VERSION ""

NS_ :

BS_:

BU_: OpticalSensor EMUS_BMS SCIMO_PE TelemetryNode Master SensorF SensorR BrakeF BrakeR PDU HVCU HVTU TestBench

BO_ 1538 SensorR_SDO_Req_Down: 2 TelemetryNode
 SG_ SensorR_SDO_ID M : 0|12@1+ (1,0) [0|4095] ""  SensorR

BO_ 1794 SensorR_Heartbeat: 1 SensorR
 SG_ SensorR_NodeState : 0|8@1+ (1,0) [0|0] ""  SensorF,Master,TelemetryNode

BO_ 1858 SensorR_BTL_TX: 8 SensorR

BO_ 1922 SensorR_BTL_RX: 8 TelemetryNode

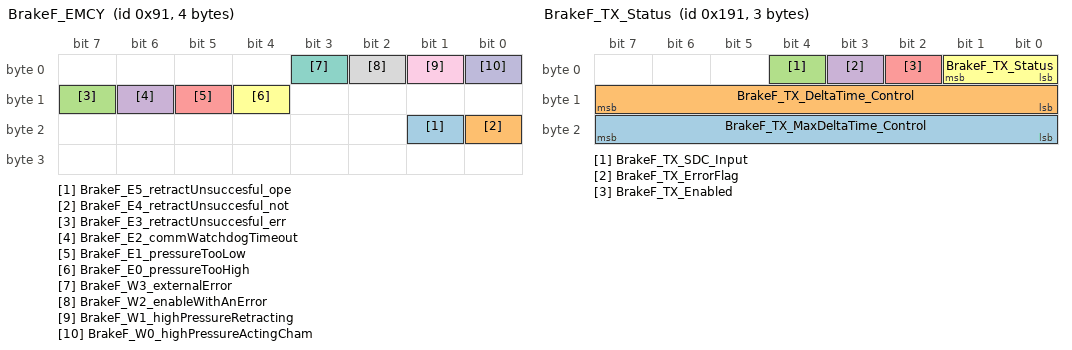
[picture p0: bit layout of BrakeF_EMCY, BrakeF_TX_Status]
BO_ 145 BrakeF_EMCY: 4 BrakeF
 SG_ BrakeF_E5_retractUnsuccesful_ope : 17|1@1+ (1,0) [0|0] ""  Master,TelemetryNode
 SG_ BrakeF_E4_retractUnsuccesful_not : 16|1@1+ (1,0) [0|0] ""  Master,TelemetryNode
 SG_ BrakeF_E3_retractUnsuccesful_err : 15|1@1+ (1,0) [0|0] ""  Master,TelemetryNode
 SG_ BrakeF_E2_commWatchdogTimeout : 14|1@1+ (1,0) [0|0] ""  Master,TelemetryNode
 SG_ BrakeF_E1_pressureTooLow : 13|1@1+ (1,0) [0|0] ""  Master,TelemetryNode
 SG_ BrakeF_E0_pressureTooHigh : 12|1@1+ (1,0) [0|0] ""  Master,TelemetryNode
 SG_ BrakeF_W3_externalError : 3|1@1+ (1,0) [0|0] ""  Master,TelemetryNode
 SG_ BrakeF_W2_enableWithAnError : 2|1@1+ (1,0) [0|0] ""  Master,TelemetryNode
 SG_ BrakeF_W1_highPressureRetracting : 1|1@1+ (1,0) [0|0] ""  Master,TelemetryNode
 SG_ BrakeF_W0_highPressureActingCham : 0|1@1+ (1,0) [0|0] ""  Master,TelemetryNode

BO_ 401 BrakeF_TX_Status: 3 BrakeF
 SG_ BrakeF_TX_MaxDeltaTime_Control : 16|8@1+ (1,0) [0|255] "ms" Vector__XXX
 SG_ BrakeF_TX_DeltaTime_Control : 8|8@1+ (1,0) [0|255] "ms" Vector__XXX
 SG_ BrakeF_TX_SDC_Input : 4|1@1+ (1,0) [0|0] "" Vector__XXX
 SG_ BrakeF_TX_ErrorFlag : 3|1@1+ (1,0) [0|0] ""  SensorF
 SG_ BrakeF_TX_Enabled : 2|1@1+ (1,0) [0|0] ""  SensorF
 SG_ BrakeF_TX_Status : 0|2@1+ (1,0) [0|0] ""  SensorF

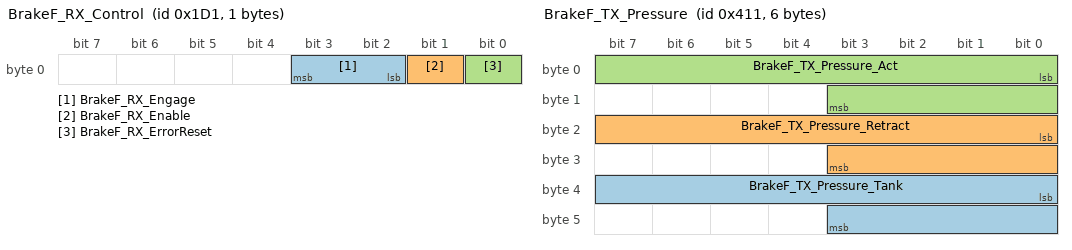
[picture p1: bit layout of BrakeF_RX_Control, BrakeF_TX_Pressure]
BO_ 465 BrakeF_RX_Control: 1 SensorF
 SG_ BrakeF_RX_Engage : 2|2@1+ (1,0) [0|0] "" Vector__XXX
 SG_ BrakeF_RX_Enable : 1|1@1+ (1,0) [0|0] "" Vector__XXX
 SG_ BrakeF_RX_ErrorReset : 0|1@1+ (1,0) [0|0] "" Vector__XXX

BO_ 529 BrakeF_TX_PDO2: 0 BrakeF

BO_ 593 BrakeF_RX_PDO2: 0 Vector__XXX

BO_ 657 BrakeF_TX_PDO3: 0 BrakeF

BO_ 721 BrakeF_RX_PDO3: 0 Vector__XXX

BO_ 785 BrakeF_TX_PDO4: 0 BrakeF

BO_ 849 BrakeF_RX_PDO4: 0 Vector__XXX

BO_ 913 BrakeF_TX_PDO5: 0 BrakeF

BO_ 977 BrakeF_TX_PDO6: 0 BrakeF

BO_ 1041 BrakeF_TX_Pressure: 6 BrakeF
 SG_ BrakeF_TX_Pressure_Tank : 32|12@1+ (0.005,-2) [-2|18.475] "bar" Vector__XXX
 SG_ BrakeF_TX_Pressure_Retract : 16|12@1+ (0.005,-2) [-2|18.475] "bar" Vector__XXX
 SG_ BrakeF_TX_Pressure_Act : 0|12@1+ (0.005,-2) [-2|18.475] "bar" Vector__XXX

BO_ 1105 BrakeF_TX_PDO8: 0 BrakeF

BO_ 1169 BrakeF_TX_PDO9: 0 BrakeF

BO_ 1233 BrakeF_TX_PDO10: 0 BrakeF

BO_ 1297 BrakeF_TX_PDO11: 0 BrakeF

BO_ 1361 BrakeF_TX_PDO12: 0 BrakeF

BO_ 1425 BrakeF_SDO_Resp: 8 BrakeF
 SG_ BrakeF_OD_valveUpperTolerance m2053 : 16|16@1+ (0.005,0) [0|327.675] "bar"  TelemetryNode
 SG_ BrakeF_OD_commWatchdog m2052 : 16|16@1+ (1,0) [0|65535] "ms"  TelemetryNode
 SG_ BrakeF_OD_counterLimit m2051 : 16|8@1+ (1,0) [0|255] ""  TelemetryNode
 SG_ BrakeF_OD_delay m2050 : 16|8@1+ (0.5,0) [0|127.5] "ms"  TelemetryNode
 SG_ BrakeF_OD_tankUpperControlLimit m2049 : 16|16@1+ (0.005,0) [0|327.675] "bar"  TelemetryNode
 SG_ BrakeF_OD_tankLowerControlLimit m2048 : 16|16@1+ (0.005,0) [0|327.675] "bar"  TelemetryNode
 SG_ BrakeF_OD_CAN2_DelayedTxMessages m1129 : 16|24@1+ (1,0) [0|16777215] ""  TelemetryNode
 SG_ BrakeF_OD_CAN2_ErrorStatus m1128 : 16|8@1+ (1,0) [0|255] ""  TelemetryNode
 SG_ BrakeF_OD_CAN2_DiscardedTxMessag m1127 : 16|24@1+ (1,0) [0|16777215] ""  TelemetryNode
 SG_ BrakeF_OD_CAN2_Status m1126 : 16|8@1+ (1,0) [0|255] ""  TelemetryNode
 SG_ BrakeF_OD_CAN2_Baudrate m1124 : 16|16@1+ (1,0) [125|1000] "kbps"  TelemetryNode
 SG_ BrakeF_OD_CAN2_autoErrorReset m1123 : 16|8@1+ (1,0) [0|255] ""  TelemetryNode
 SG_ BrakeF_OD_CAN2_lastErrorCode m1122 : 16|32@1+ (1,0) [0|4294967295] ""  TelemetryNode
 SG_ BrakeF_OD_CAN2_RxErrCnt m1121 : 16|8@1+ (1,0) [0|255] ""  TelemetryNode
 SG_ BrakeF_OD_CAN2_TxErrCnt m1120 : 16|8@1+ (1,0) [0|255] ""  TelemetryNode
 SG_ BrakeF_OD_CAN1_DelayedTxMessages m1113 : 16|24@1+ (1,0) [0|16777215] ""  TelemetryNode
 SG_ BrakeF_OD_CAN1_ErrorStatus m1112 : 16|8@1+ (1,0) [0|255] ""  TelemetryNode
 SG_ BrakeF_OD_CAN1_DiscardedTxMessag m1111 : 16|24@1+ (1,0) [0|16777215] ""  TelemetryNode
 SG_ BrakeF_OD_CAN1_Status m1110 : 16|8@1+ (1,0) [0|255] ""  TelemetryNode
 SG_ BrakeF_OD_CAN1_Baudrate m1108 : 16|16@1+ (1,0) [125|1000] "kbps"  TelemetryNode
 SG_ BrakeF_OD_CAN1_autoErrorReset m1107 : 16|8@1+ (1,0) [0|255] ""  TelemetryNode
 SG_ BrakeF_OD_CAN1_lastErrorCode m1106 : 16|32@1+ (1,0) [0|4294967295] ""  TelemetryNode
 SG_ BrakeF_OD_CAN1_RxErrCnt m1105 : 16|8@1+ (1,0) [0|255] ""  TelemetryNode
 SG_ BrakeF_OD_CAN1_TxErrCnt m1104 : 16|8@1+ (1,0) [0|255] ""  TelemetryNode
 SG_ BrakeF_OD_BuildTime m1073 : 16|24@1+ (1,0) [0|16777215] ""  TelemetryNode
 SG_ BrakeF_OD_BuildDate m1072 : 16|32@1+ (1,0) [0|4294967295] ""  TelemetryNode
 SG_ BrakeF_OD_ChipUID2 m1057 : 16|48@1+ (1,0) [0|281474976710655] ""  TelemetryNode
 SG_ BrakeF_OD_ChipUID1 m1056 : 16|48@1+ (1,0) [0|281474976710655] ""  TelemetryNode
 SG_ BrakeF_OD_SdcOut m1046 : 16|8@1+ (1,0) [0|255] ""  TelemetryNode
 SG_ BrakeF_OD_SdcIn m1045 : 16|8@1+ (1,0) [0|255] ""  TelemetryNode
 SG_ BrakeF_OD_runtime m1044 : 16|24@1+ (1,0) [0|16777215] "ms"  TelemetryNode
 SG_ BrakeF_OD_InputVoltage m1043 : 16|16@1+ (0.001,0) [0|65.535] "V"  TelemetryNode
 SG_ BrakeF_OD_BoardTemp m1042 : 16|16@1+ (0.01,-30) [-30|625.35] "°C"  TelemetryNode
 SG_ BrakeF_OD_MemFree m1041 : 16|16@1+ (4,0) [0|262140] "bytes"  TelemetryNode
 SG_ BrakeF_OD_CpuUsage m1040 : 16|8@1+ (0.5,0) [0|100] "%"  TelemetryNode
 SG_ BrakeF_OD_OdEntrySendInterval m33 : 16|16@1+ (1,0) [0|65535] "ms"  TelemetryNode
 SG_ BrakeF_OD_SendOdOnBootup m32 : 16|8@1+ (1,0) [0|255] ""  TelemetryNode
 SG_ BrakeF_OD_HeartbeatInterval m16 : 16|16@1+ (1,0) [0|65535] "ms"  TelemetryNode
 SG_ BrakeF_OD_DbcVersion m5 : 16|16@1+ (1,0) [0|65535] ""  TelemetryNode
 SG_ BrakeF_OD_StackVersion m4 : 16|16@1+ (1,0) [0|65535] ""  TelemetryNode
 SG_ BrakeF_OD_ProtocolVersion m3 : 16|16@1+ (1,0) [0|65535] ""  TelemetryNode
 SG_ BrakeF_OD_NodeStatus m2 : 16|8@1+ (1,0) [0|255] ""  TelemetryNode
 SG_ BrakeF_OD_NodeID m1 : 16|8@1+ (1,0) [0|255] ""  TelemetryNode
 SG_ BrakeF_SDO_RespCode : 12|4@1+ (1,0) [0|0] ""  TelemetryNode
 SG_ BrakeF_SDO_ID M : 0|12@1+ (1,0) [0|4095] ""  TelemetryNode

BO_ 1489 BrakeF_SDO_Req_Up: 8 TelemetryNode
 SG_ BrakeF_OD_valveUpperTolerance m2053 : 16|16@1+ (0.005,0) [0|327.675] "bar"  BrakeF
 SG_ BrakeF_OD_commWatchdog m2052 : 16|16@1+ (1,0) [0|65535] "ms"  BrakeF
 SG_ BrakeF_OD_counterLimit m2051 : 16|8@1+ (1,0) [0|255] ""  BrakeF
 SG_ BrakeF_OD_delay m2050 : 16|8@1+ (0.5,0) [0|127.5] "ms"  BrakeF
 SG_ BrakeF_OD_tankUpperControlLimit m2049 : 16|16@1+ (0.005,0) [0|327.675] "bar"  BrakeF
 SG_ BrakeF_OD_tankLowerControlLimit m2048 : 16|16@1+ (0.005,0) [0|327.675] "bar"  BrakeF
 SG_ BrakeF_OD_CAN2_DelayedTxMessages m1129 : 16|24@1+ (1,0) [0|16777215] ""  BrakeF
 SG_ BrakeF_OD_CAN2_ErrorStatus m1128 : 16|8@1+ (1,0) [0|255] ""  BrakeF
 SG_ BrakeF_OD_CAN2_DiscardedTxM_0000 m1127 : 16|24@1+ (1,0) [0|16777215] ""  BrakeF
 SG_ BrakeF_OD_CAN2_Status m1126 : 16|8@1+ (1,0) [0|255] ""  BrakeF
 SG_ BrakeF_OD_CAN2_Baudrate m1124 : 16|16@1+ (1,0) [125|1000] "kbps"  BrakeF
 SG_ BrakeF_OD_CAN2_autoErrorReset m1123 : 16|8@1+ (1,0) [0|255] ""  BrakeF
 SG_ BrakeF_OD_CAN2_lastErrorCode m1122 : 16|32@1+ (1,0) [0|4294967295] ""  BrakeF
 SG_ BrakeF_OD_CAN2_RxErrCnt m1121 : 16|8@1+ (1,0) [0|255] ""  BrakeF
 SG_ BrakeF_OD_CAN2_TxErrCnt m1120 : 16|8@1+ (1,0) [0|255] ""  BrakeF
 SG_ BrakeF_OD_CAN1_DelayedTxMessages m1113 : 16|24@1+ (1,0) [0|16777215] ""  BrakeF
 SG_ BrakeF_OD_CAN1_ErrorStatus m1112 : 16|8@1+ (1,0) [0|255] ""  BrakeF
 SG_ BrakeF_OD_CAN1_DiscardedTxM_0000 m1111 : 16|24@1+ (1,0) [0|16777215] ""  BrakeF
 SG_ BrakeF_OD_CAN1_Status m1110 : 16|8@1+ (1,0) [0|255] ""  BrakeF
 SG_ BrakeF_OD_CAN1_Baudrate m1108 : 16|16@1+ (1,0) [125|1000] "kbps"  BrakeF
 SG_ BrakeF_OD_CAN1_autoErrorReset m1107 : 16|8@1+ (1,0) [0|255] ""  BrakeF
 SG_ BrakeF_OD_CAN1_lastErrorCode m1106 : 16|32@1+ (1,0) [0|4294967295] ""  BrakeF
 SG_ BrakeF_OD_CAN1_RxErrCnt m1105 : 16|8@1+ (1,0) [0|255] ""  BrakeF
 SG_ BrakeF_OD_CAN1_TxErrCnt m1104 : 16|8@1+ (1,0) [0|255] ""  BrakeF
 SG_ BrakeF_OD_BuildTime m1073 : 16|24@1+ (1,0) [0|16777215] ""  BrakeF
 SG_ BrakeF_OD_BuildDate m1072 : 16|32@1+ (1,0) [0|4294967295] ""  BrakeF
 SG_ BrakeF_OD_ChipUID2 m1057 : 16|48@1+ (1,0) [0|281474976710655] ""  BrakeF
 SG_ BrakeF_OD_ChipUID1 m1056 : 16|48@1+ (1,0) [0|281474976710655] ""  BrakeF
 SG_ BrakeF_OD_SdcOut m1046 : 16|8@1+ (1,0) [0|255] ""  BrakeF
 SG_ BrakeF_OD_SdcIn m1045 : 16|8@1+ (1,0) [0|255] ""  BrakeF
 SG_ BrakeF_OD_runtime m1044 : 16|24@1+ (1,0) [0|16777215] "ms"  BrakeF
 SG_ BrakeF_OD_InputVoltage m1043 : 16|16@1+ (0.001,0) [0|65.535] "V"  BrakeF
 SG_ BrakeF_OD_BoardTemp m1042 : 16|16@1+ (0.01,-30) [-30|625.35] "°C"  BrakeF
 SG_ BrakeF_OD_MemFree m1041 : 16|16@1+ (4,0) [0|262140] "bytes"  BrakeF
 SG_ BrakeF_OD_CpuUsage m1040 : 16|8@1+ (0.5,0) [0|100] "%"  BrakeF
 SG_ BrakeF_OD_OdEntrySendInterval m33 : 16|16@1+ (1,0) [0|65535] "ms"  BrakeF
 SG_ BrakeF_OD_SendOdOnBootup m32 : 16|8@1+ (1,0) [0|255] ""  BrakeF
 SG_ BrakeF_OD_HeartbeatInterval m16 : 16|16@1+ (1,0) [0|65535] "ms"  BrakeF
 SG_ BrakeF_OD_DbcVersion m5 : 16|16@1+ (1,0) [0|65535] ""  BrakeF
 SG_ BrakeF_OD_StackVersion m4 : 16|16@1+ (1,0) [0|65535] ""  BrakeF
 SG_ BrakeF_OD_ProtocolVersion m3 : 16|16@1+ (1,0) [0|65535] ""  BrakeF
 SG_ BrakeF_OD_NodeStatus m2 : 16|8@1+ (1,0) [0|255] ""  BrakeF
 SG_ BrakeF_OD_NodeID m1 : 16|8@1+ (1,0) [0|255] ""  BrakeF
 SG_ BrakeF_SDO_ID M : 0|12@1+ (1,0) [0|4095] ""  BrakeF

BO_ 1553 BrakeF_SDO_Req_Down: 2 TelemetryNode
 SG_ BrakeF_SDO_ID M : 0|12@1+ (1,0) [0|4095] ""  BrakeF

BO_ 1809 BrakeF_Heartbeat: 1 BrakeF
 SG_ BrakeF_NodeState : 0|8@1+ (1,0) [0|0] ""  SensorF,Master,TelemetryNode

BO_ 1873 BrakeF_BTL_TX: 8 BrakeF

BO_ 1937 BrakeF_BTL_RX: 8 TelemetryNode

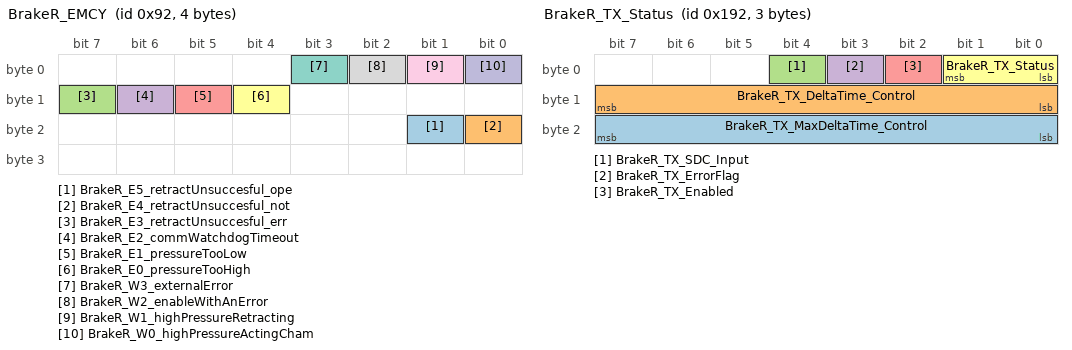
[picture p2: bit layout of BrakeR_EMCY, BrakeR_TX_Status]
BO_ 146 BrakeR_EMCY: 4 BrakeR
 SG_ BrakeR_E5_retractUnsuccesful_ope : 17|1@1+ (1,0) [0|0] ""  Master,TelemetryNode
 SG_ BrakeR_E4_retractUnsuccesful_not : 16|1@1+ (1,0) [0|0] ""  Master,TelemetryNode
 SG_ BrakeR_E3_retractUnsuccesful_err : 15|1@1+ (1,0) [0|0] ""  Master,TelemetryNode
 SG_ BrakeR_E2_commWatchdogTimeout : 14|1@1+ (1,0) [0|0] ""  Master,TelemetryNode
 SG_ BrakeR_E1_pressureTooLow : 13|1@1+ (1,0) [0|0] ""  Master,TelemetryNode
 SG_ BrakeR_E0_pressureTooHigh : 12|1@1+ (1,0) [0|0] ""  Master,TelemetryNode
 SG_ BrakeR_W3_externalError : 3|1@1+ (1,0) [0|0] ""  Master,TelemetryNode
 SG_ BrakeR_W2_enableWithAnError : 2|1@1+ (1,0) [0|0] ""  Master,TelemetryNode
 SG_ BrakeR_W1_highPressureRetracting : 1|1@1+ (1,0) [0|0] ""  Master,TelemetryNode
 SG_ BrakeR_W0_highPressureActingCham : 0|1@1+ (1,0) [0|0] ""  Master,TelemetryNode

BO_ 402 BrakeR_TX_Status: 3 BrakeR
 SG_ BrakeR_TX_MaxDeltaTime_Control : 16|8@1+ (1,0) [0|255] "ms" Vector__XXX
 SG_ BrakeR_TX_DeltaTime_Control : 8|8@1+ (1,0) [0|255] "ms" Vector__XXX
 SG_ BrakeR_TX_SDC_Input : 4|1@1+ (1,0) [0|0] "" Vector__XXX
 SG_ BrakeR_TX_ErrorFlag : 3|1@1+ (1,0) [0|0] ""  SensorF
 SG_ BrakeR_TX_Enabled : 2|1@1+ (1,0) [0|0] ""  SensorF
 SG_ BrakeR_TX_Status : 0|2@1+ (1,0) [0|0] ""  SensorF

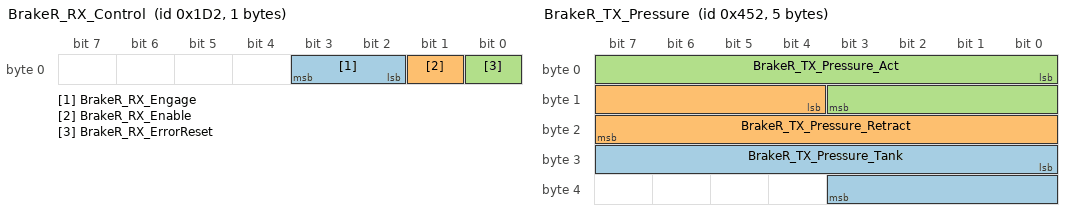
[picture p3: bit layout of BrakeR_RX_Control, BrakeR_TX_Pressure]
BO_ 466 BrakeR_RX_Control: 1 SensorF
 SG_ BrakeR_RX_Engage : 2|2@1+ (1,0) [0|0] "" Vector__XXX
 SG_ BrakeR_RX_Enable : 1|1@1+ (1,0) [0|0] "" Vector__XXX
 SG_ BrakeR_RX_ErrorReset : 0|1@1+ (1,0) [0|0] "" Vector__XXX

BO_ 530 BrakeR_TX_PDO2: 0 BrakeR

BO_ 594 BrakeR_RX_PDO2: 0 Vector__XXX

BO_ 658 BrakeR_TX_PDO3: 0 BrakeR

BO_ 722 BrakeR_RX_PDO3: 0 Vector__XXX

BO_ 786 BrakeR_TX_PDO4: 0 BrakeR

BO_ 850 BrakeR_RX_PDO4: 0 Vector__XXX

BO_ 914 BrakeR_TX_PDO5: 0 BrakeR

BO_ 978 BrakeR_TX_PDO6: 0 BrakeR

BO_ 1042 BrakeR_TX_PDO7: 0 BrakeR

BO_ 1106 BrakeR_TX_Pressure: 5 BrakeR
 SG_ BrakeR_TX_Pressure_Tank : 24|12@1+ (0.005,-2) [-2|18.475] "bar" Vector__XXX
 SG_ BrakeR_TX_Pressure_Retract : 12|12@1+ (0.005,-2) [-2|18.475] "bar" Vector__XXX
 SG_ BrakeR_TX_Pressure_Act : 0|12@1+ (0.005,-2) [-2|18.475] "bar" Vector__XXX

BO_ 1170 BrakeR_TX_PDO9: 0 BrakeR

BO_ 1234 BrakeR_TX_PDO10: 0 BrakeR

BO_ 1298 BrakeR_TX_PDO11: 0 BrakeR

BO_ 1362 BrakeR_TX_PDO12: 0 BrakeR

BO_ 1426 BrakeR_SDO_Resp: 8 BrakeR
 SG_ BrakeR_OD_valveUpperTolerance m2053 : 16|16@1+ (0.005,0) [0|327.675] "bar"  TelemetryNode
 SG_ BrakeR_OD_commWatchdog m2052 : 16|16@1+ (1,0) [0|65535] "ms"  TelemetryNode
 SG_ BrakeR_OD_counterLimit m2051 : 16|8@1+ (1,0) [0|255] ""  TelemetryNode
 SG_ BrakeR_OD_delay m2050 : 16|8@1+ (0.5,0) [0|127.5] "ms"  TelemetryNode
 SG_ BrakeR_OD_tankUpperControlLimit m2049 : 16|16@1+ (0.005,0) [0|327.675] "bar"  TelemetryNode
 SG_ BrakeR_OD_tankLowerControlLimit m2048 : 16|16@1+ (0.005,0) [0|327.675] "bar"  TelemetryNode
 SG_ BrakeR_OD_CAN2_DelayedTxMessages m1129 : 16|24@1+ (1,0) [0|16777215] ""  TelemetryNode
 SG_ BrakeR_OD_CAN2_ErrorStatus m1128 : 16|8@1+ (1,0) [0|255] ""  TelemetryNode
 SG_ BrakeR_OD_CAN2_DiscardedTxMessag m1127 : 16|24@1+ (1,0) [0|16777215] ""  TelemetryNode
 SG_ BrakeR_OD_CAN2_Status m1126 : 16|8@1+ (1,0) [0|255] ""  TelemetryNode
 SG_ BrakeR_OD_CAN2_Baudrate m1124 : 16|16@1+ (1,0) [125|1000] "kbps"  TelemetryNode
 SG_ BrakeR_OD_CAN2_autoErrorReset m1123 : 16|8@1+ (1,0) [0|255] ""  TelemetryNode
 SG_ BrakeR_OD_CAN2_lastErrorCode m1122 : 16|32@1+ (1,0) [0|4294967295] ""  TelemetryNode
 SG_ BrakeR_OD_CAN2_RxErrCnt m1121 : 16|8@1+ (1,0) [0|255] ""  TelemetryNode
 SG_ BrakeR_OD_CAN2_TxErrCnt m1120 : 16|8@1+ (1,0) [0|255] ""  TelemetryNode
 SG_ BrakeR_OD_CAN1_DelayedTxMessages m1113 : 16|24@1+ (1,0) [0|16777215] ""  TelemetryNode
 SG_ BrakeR_OD_CAN1_ErrorStatus m1112 : 16|8@1+ (1,0) [0|255] ""  TelemetryNode
 SG_ BrakeR_OD_CAN1_DiscardedTxMessag m1111 : 16|24@1+ (1,0) [0|16777215] ""  TelemetryNode
 SG_ BrakeR_OD_CAN1_Status m1110 : 16|8@1+ (1,0) [0|255] ""  TelemetryNode
 SG_ BrakeR_OD_CAN1_Baudrate m1108 : 16|16@1+ (1,0) [125|1000] "kbps"  TelemetryNode
 SG_ BrakeR_OD_CAN1_autoErrorReset m1107 : 16|8@1+ (1,0) [0|255] ""  TelemetryNode
 SG_ BrakeR_OD_CAN1_lastErrorCode m1106 : 16|32@1+ (1,0) [0|4294967295] ""  TelemetryNode
 SG_ BrakeR_OD_CAN1_RxErrCnt m1105 : 16|8@1+ (1,0) [0|255] ""  TelemetryNode
 SG_ BrakeR_OD_CAN1_TxErrCnt m1104 : 16|8@1+ (1,0) [0|255] ""  TelemetryNode
 SG_ BrakeR_OD_BuildTime m1073 : 16|24@1+ (1,0) [0|16777215] ""  TelemetryNode
 SG_ BrakeR_OD_BuildDate m1072 : 16|32@1+ (1,0) [0|4294967295] ""  TelemetryNode
 SG_ BrakeR_OD_ChipUID2 m1057 : 16|48@1+ (1,0) [0|281474976710655] ""  TelemetryNode
 SG_ BrakeR_OD_ChipUID1 m1056 : 16|48@1+ (1,0) [0|281474976710655] ""  TelemetryNode
 SG_ BrakeR_OD_SdcOut m1046 : 16|8@1+ (1,0) [0|255] ""  TelemetryNode
 SG_ BrakeR_OD_SdcIn m1045 : 16|8@1+ (1,0) [0|255] ""  TelemetryNode
 SG_ BrakeR_OD_runtime m1044 : 16|24@1+ (1,0) [0|16777215] "ms"  TelemetryNode
 SG_ BrakeR_OD_InputVoltage m1043 : 16|16@1+ (0.001,0) [0|65.535] "V"  TelemetryNode
 SG_ BrakeR_OD_BoardTemp m1042 : 16|16@1+ (0.01,-30) [-30|625.35] "°C"  TelemetryNode
 SG_ BrakeR_OD_MemFree m1041 : 16|16@1+ (4,0) [0|262140] "bytes"  TelemetryNode
 SG_ BrakeR_OD_CpuUsage m1040 : 16|8@1+ (0.5,0) [0|100] "%"  TelemetryNode
 SG_ BrakeR_OD_OdEntrySendInterval m33 : 16|16@1+ (1,0) [0|65535] "ms"  TelemetryNode
 SG_ BrakeR_OD_SendOdOnBootup m32 : 16|8@1+ (1,0) [0|255] ""  TelemetryNode
 SG_ BrakeR_OD_HeartbeatInterval m16 : 16|16@1+ (1,0) [0|65535] "ms"  TelemetryNode
 SG_ BrakeR_OD_DbcVersion m5 : 16|16@1+ (1,0) [0|65535] ""  TelemetryNode
 SG_ BrakeR_OD_StackVersion m4 : 16|16@1+ (1,0) [0|65535] ""  TelemetryNode
 SG_ BrakeR_OD_ProtocolVersion m3 : 16|16@1+ (1,0) [0|65535] ""  TelemetryNode
 SG_ BrakeR_OD_NodeStatus m2 : 16|8@1+ (1,0) [0|255] ""  TelemetryNode
 SG_ BrakeR_OD_NodeID m1 : 16|8@1+ (1,0) [0|255] ""  TelemetryNode
 SG_ BrakeR_SDO_RespCode : 12|4@1+ (1,0) [0|0] ""  TelemetryNode
 SG_ BrakeR_SDO_ID M : 0|12@1+ (1,0) [0|4095] ""  TelemetryNode

BO_ 1490 BrakeR_SDO_Req_Up: 8 TelemetryNode
 SG_ BrakeR_OD_valveUpperTolerance m2053 : 16|16@1+ (0.005,0) [0|327.675] "bar"  BrakeR
 SG_ BrakeR_OD_commWatchdog m2052 : 16|16@1+ (1,0) [0|65535] "ms"  BrakeR
 SG_ BrakeR_OD_counterLimit m2051 : 16|8@1+ (1,0) [0|255] ""  BrakeR
 SG_ BrakeR_OD_delay m2050 : 16|8@1+ (0.5,0) [0|127.5] "ms"  BrakeR
 SG_ BrakeR_OD_tankUpperControlLimit m2049 : 16|16@1+ (0.005,0) [0|327.675] "bar"  BrakeR
 SG_ BrakeR_OD_tankLowerControlLimit m2048 : 16|16@1+ (0.005,0) [0|327.675] "bar"  BrakeR
 SG_ BrakeR_OD_CAN2_DelayedTxMessages m1129 : 16|24@1+ (1,0) [0|16777215] ""  BrakeR
 SG_ BrakeR_OD_CAN2_ErrorStatus m1128 : 16|8@1+ (1,0) [0|255] ""  BrakeR
 SG_ BrakeR_OD_CAN2_DiscardedTxM_0000 m1127 : 16|24@1+ (1,0) [0|16777215] ""  BrakeR
 SG_ BrakeR_OD_CAN2_Status m1126 : 16|8@1+ (1,0) [0|255] ""  BrakeR
 SG_ BrakeR_OD_CAN2_Baudrate m1124 : 16|16@1+ (1,0) [125|1000] "kbps"  BrakeR
 SG_ BrakeR_OD_CAN2_autoErrorReset m1123 : 16|8@1+ (1,0) [0|255] ""  BrakeR
 SG_ BrakeR_OD_CAN2_lastErrorCode m1122 : 16|32@1+ (1,0) [0|4294967295] ""  BrakeR
 SG_ BrakeR_OD_CAN2_RxErrCnt m1121 : 16|8@1+ (1,0) [0|255] ""  BrakeR
 SG_ BrakeR_OD_CAN2_TxErrCnt m1120 : 16|8@1+ (1,0) [0|255] ""  BrakeR
 SG_ BrakeR_OD_CAN1_DelayedTxMessages m1113 : 16|24@1+ (1,0) [0|16777215] ""  BrakeR
 SG_ BrakeR_OD_CAN1_ErrorStatus m1112 : 16|8@1+ (1,0) [0|255] ""  BrakeR
 SG_ BrakeR_OD_CAN1_DiscardedTxM_0000 m1111 : 16|24@1+ (1,0) [0|16777215] ""  BrakeR
 SG_ BrakeR_OD_CAN1_Status m1110 : 16|8@1+ (1,0) [0|255] ""  BrakeR
 SG_ BrakeR_OD_CAN1_Baudrate m1108 : 16|16@1+ (1,0) [125|1000] "kbps"  BrakeR
 SG_ BrakeR_OD_CAN1_autoErrorReset m1107 : 16|8@1+ (1,0) [0|255] ""  BrakeR
 SG_ BrakeR_OD_CAN1_lastErrorCode m1106 : 16|32@1+ (1,0) [0|4294967295] ""  BrakeR
 SG_ BrakeR_OD_CAN1_RxErrCnt m1105 : 16|8@1+ (1,0) [0|255] ""  BrakeR
 SG_ BrakeR_OD_CAN1_TxErrCnt m1104 : 16|8@1+ (1,0) [0|255] ""  BrakeR
 SG_ BrakeR_OD_BuildTime m1073 : 16|24@1+ (1,0) [0|16777215] ""  BrakeR
 SG_ BrakeR_OD_BuildDate m1072 : 16|32@1+ (1,0) [0|4294967295] ""  BrakeR
 SG_ BrakeR_OD_ChipUID2 m1057 : 16|48@1+ (1,0) [0|281474976710655] ""  BrakeR
 SG_ BrakeR_OD_ChipUID1 m1056 : 16|48@1+ (1,0) [0|281474976710655] ""  BrakeR
 SG_ BrakeR_OD_SdcOut m1046 : 16|8@1+ (1,0) [0|255] ""  BrakeR
 SG_ BrakeR_OD_SdcIn m1045 : 16|8@1+ (1,0) [0|255] ""  BrakeR
 SG_ BrakeR_OD_runtime m1044 : 16|24@1+ (1,0) [0|16777215] "ms"  BrakeR
 SG_ BrakeR_OD_InputVoltage m1043 : 16|16@1+ (0.001,0) [0|65.535] "V"  BrakeR
 SG_ BrakeR_OD_BoardTemp m1042 : 16|16@1+ (0.01,-30) [-30|625.35] "°C"  BrakeR
 SG_ BrakeR_OD_MemFree m1041 : 16|16@1+ (4,0) [0|262140] "bytes"  BrakeR
 SG_ BrakeR_OD_CpuUsage m1040 : 16|8@1+ (0.5,0) [0|100] "%"  BrakeR
 SG_ BrakeR_OD_OdEntrySendInterval m33 : 16|16@1+ (1,0) [0|65535] "ms"  BrakeR
 SG_ BrakeR_OD_SendOdOnBootup m32 : 16|8@1+ (1,0) [0|255] ""  BrakeR
 SG_ BrakeR_OD_HeartbeatInterval m16 : 16|16@1+ (1,0) [0|65535] "ms"  BrakeR
 SG_ BrakeR_OD_DbcVersion m5 : 16|16@1+ (1,0) [0|65535] ""  BrakeR
 SG_ BrakeR_OD_StackVersion m4 : 16|16@1+ (1,0) [0|65535] ""  BrakeR
 SG_ BrakeR_OD_ProtocolVersion m3 : 16|16@1+ (1,0) [0|65535] ""  BrakeR
 SG_ BrakeR_OD_NodeStatus m2 : 16|8@1+ (1,0) [0|255] ""  BrakeR
 SG_ BrakeR_OD_NodeID m1 : 16|8@1+ (1,0) [0|255] ""  BrakeR
 SG_ BrakeR_SDO_ID M : 0|12@1+ (1,0) [0|4095] ""  BrakeR

BO_ 1554 BrakeR_SDO_Req_Down: 2 TelemetryNode
 SG_ BrakeR_SDO_ID M : 0|12@1+ (1,0) [0|4095] ""  BrakeR

BO_ 1810 BrakeR_Heartbeat: 1 BrakeR
 SG_ BrakeR_NodeState : 0|8@1+ (1,0) [0|0] ""  SensorF,Master,TelemetryNode

BO_ 1874 BrakeR_BTL_TX: 8 BrakeR

BO_ 1938 BrakeR_BTL_RX: 8 TelemetryNode

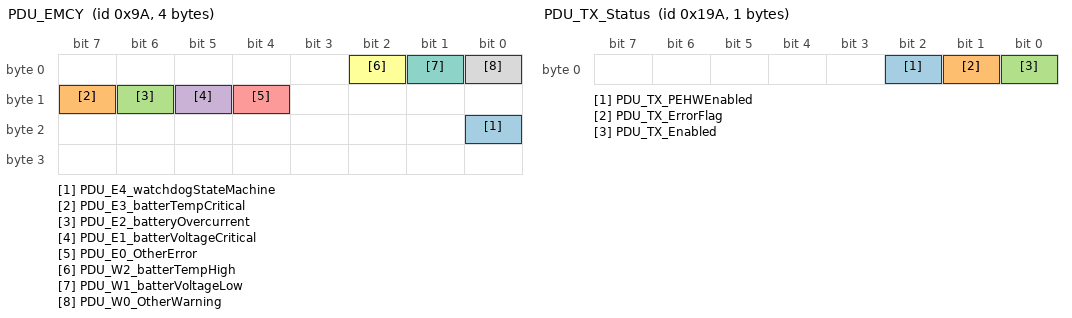
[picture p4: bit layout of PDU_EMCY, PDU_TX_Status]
BO_ 154 PDU_EMCY: 4 PDU
 SG_ PDU_E4_watchdogStateMachine : 16|1@1+ (1,0) [0|0] ""  Master,TelemetryNode
 SG_ PDU_E3_batterTempCritical : 15|1@1+ (1,0) [0|0] ""  Master,TelemetryNode
 SG_ PDU_E2_batteryOvercurrent : 14|1@1+ (1,0) [0|0] ""  Master,TelemetryNode
 SG_ PDU_E1_batterVoltageCritical : 13|1@1+ (1,0) [0|0] ""  Master,TelemetryNode
 SG_ PDU_E0_OtherError : 12|1@1+ (1,0) [0|0] ""  Master,TelemetryNode
 SG_ PDU_W2_batterTempHigh : 2|1@1+ (1,0) [0|0] ""  Master,TelemetryNode
 SG_ PDU_W1_batterVoltageLow : 1|1@1+ (1,0) [0|0] ""  Master,TelemetryNode
 SG_ PDU_W0_OtherWarning : 0|1@1+ (1,0) [0|0] ""  Master,TelemetryNode

BO_ 410 PDU_TX_Status: 1 PDU
 SG_ PDU_TX_PEHWEnabled : 2|1@1+ (1,0) [0|0] ""  SensorF
 SG_ PDU_TX_ErrorFlag : 1|1@1+ (1,0) [0|0] ""  SensorF
 SG_ PDU_TX_Enabled : 0|1@1+ (1,0) [0|0] ""  SensorF

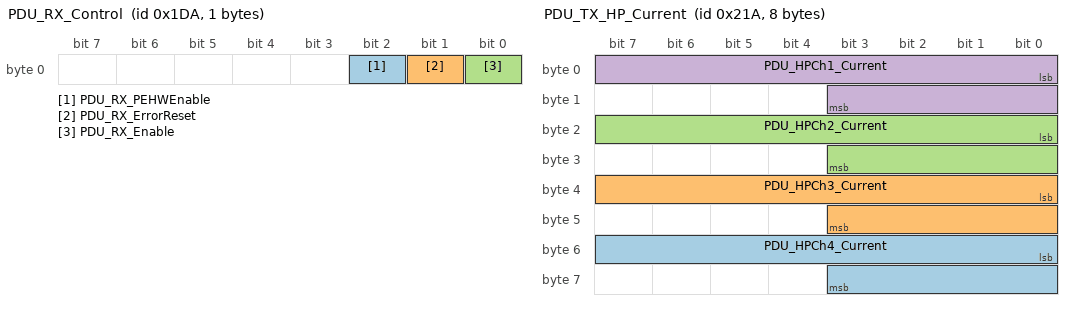
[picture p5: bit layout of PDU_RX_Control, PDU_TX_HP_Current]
BO_ 474 PDU_RX_Control: 1 SensorF
 SG_ PDU_RX_PEHWEnable : 2|1@1+ (1,0) [0|0] "" Vector__XXX
 SG_ PDU_RX_ErrorReset : 1|1@1+ (1,0) [0|0] "" Vector__XXX
 SG_ PDU_RX_Enable : 0|1@1+ (1,0) [0|0] "" Vector__XXX

BO_ 538 PDU_TX_HP_Current: 8 PDU
 SG_ PDU_HPCh4_Current : 48|12@1+ (0.004,0) [0|16.38] "A" Vector__XXX
 SG_ PDU_HPCh3_Current : 32|12@1+ (0.004,0) [0|16.38] "A" Vector__XXX
 SG_ PDU_HPCh2_Current : 16|12@1+ (0.004,0) [0|16.38] "A" Vector__XXX
 SG_ PDU_HPCh1_Current : 0|12@1+ (0.004,0) [0|16.38] "A" Vector__XXX

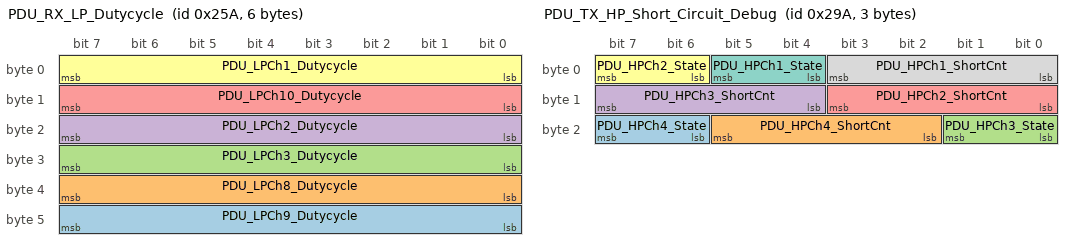
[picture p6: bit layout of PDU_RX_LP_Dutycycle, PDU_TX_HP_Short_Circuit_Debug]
BO_ 602 PDU_RX_LP_Dutycycle: 6 Vector__XXX
 SG_ PDU_LPCh9_Dutycycle : 40|8@1+ (0.5,0) [0|100] "%" Vector__XXX
 SG_ PDU_LPCh8_Dutycycle : 32|8@1+ (0.5,0) [0|100] "%" Vector__XXX
 SG_ PDU_LPCh3_Dutycycle : 24|8@1+ (0.5,0) [0|100] "%" Vector__XXX
 SG_ PDU_LPCh2_Dutycycle : 16|8@1+ (0.5,0) [0|100] "%" Vector__XXX
 SG_ PDU_LPCh10_Dutycycle : 8|8@1+ (0.5,0) [0|100] "%" Vector__XXX
 SG_ PDU_LPCh1_Dutycycle : 0|8@1+ (0.5,0) [0|100] "%" Vector__XXX

BO_ 666 PDU_TX_HP_Short_Circuit_Debug: 3 PDU
 SG_ PDU_HPCh4_State : 22|2@1+ (1,0) [0|3] "" Vector__XXX
 SG_ PDU_HPCh4_ShortCnt : 18|4@1+ (1,0) [0|15] "" Vector__XXX
 SG_ PDU_HPCh3_State : 16|2@1+ (1,0) [0|3] "" Vector__XXX
 SG_ PDU_HPCh3_ShortCnt : 12|4@1+ (1,0) [0|15] "" Vector__XXX
 SG_ PDU_HPCh2_ShortCnt : 8|4@1+ (1,0) [0|15] "" Vector__XXX
 SG_ PDU_HPCh2_State : 6|2@1+ (1,0) [0|3] "" Vector__XXX
 SG_ PDU_HPCh1_State : 4|2@1+ (1,0) [0|3] "" Vector__XXX
 SG_ PDU_HPCh1_ShortCnt : 0|4@1+ (1,0) [0|15] "" Vector__XXX

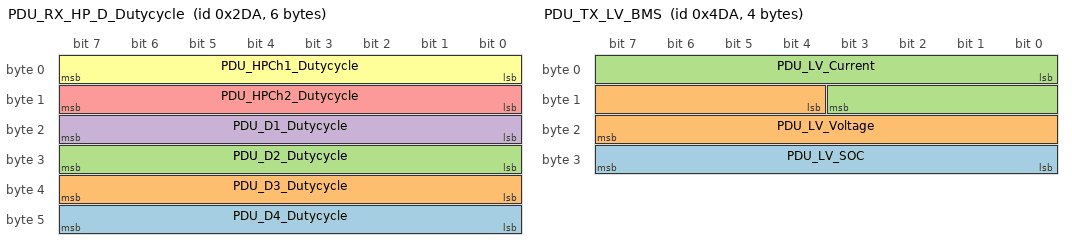
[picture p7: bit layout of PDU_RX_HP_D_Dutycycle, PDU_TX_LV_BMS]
BO_ 730 PDU_RX_HP_D_Dutycycle: 6 Vector__XXX
 SG_ PDU_D4_Dutycycle : 40|8@1+ (0.5,0) [0|100] "%" Vector__XXX
 SG_ PDU_D3_Dutycycle : 32|8@1+ (0.5,0) [0|100] "%" Vector__XXX
 SG_ PDU_D2_Dutycycle : 24|8@1+ (0.5,0) [0|100] "%" Vector__XXX
 SG_ PDU_D1_Dutycycle : 16|8@1+ (0.5,0) [0|100] "%" Vector__XXX
 SG_ PDU_HPCh2_Dutycycle : 8|8@1+ (0.5,0) [0|100] "%" Vector__XXX
 SG_ PDU_HPCh1_Dutycycle : 0|8@1+ (0.5,0) [0|100] "%" Vector__XXX

BO_ 794 PDU_TX_PDO4: 0 PDU

BO_ 858 PDU_RX_Manual_Control: 3 Vector__XXX
 SG_ PDU_SDC_Enable : 18|1@1+ (1,0) [0|0] "" Vector__XXX
 SG_ PDU_D4_Enable : 17|1@1+ (1,0) [0|1] "" Vector__XXX
 SG_ PDU_D3_Enable : 16|1@1+ (1,0) [0|1] "" Vector__XXX
 SG_ PDU_D2_Enable : 15|1@1+ (1,0) [0|1] "" Vector__XXX
 SG_ PDU_D1_Enable : 14|1@1+ (1,0) [0|1] "" Vector__XXX
 SG_ PDU_HPCh4_Enable : 13|1@1+ (1,0) [0|1] "" Vector__XXX
 SG_ PDU_HPCh3_Enable : 12|1@1+ (1,0) [0|1] "" Vector__XXX
 SG_ PDU_HPCh2_Enable : 11|1@1+ (1,0) [0|1] "" Vector__XXX
 SG_ PDU_HPCh1_Enable : 10|1@1+ (1,0) [0|1] "" Vector__XXX
 SG_ PDU_LPCh10_Enable : 9|1@1+ (1,0) [0|1] "" Vector__XXX
 SG_ PDU_LPCh9_Enable : 8|1@1+ (1,0) [0|1] "" Vector__XXX
 SG_ PDU_LPCh8_Enable : 7|1@1+ (1,0) [0|1] "" Vector__XXX
 SG_ PDU_LPCh7_Enable : 6|1@1+ (1,0) [0|1] "" Vector__XXX
 SG_ PDU_LPCh6_Enable : 5|1@1+ (1,0) [0|1] "" Vector__XXX
 SG_ PDU_LPCh5_Enable : 4|1@1+ (1,0) [0|1] "" Vector__XXX
 SG_ PDU_LPCh4_Enable : 3|1@1+ (1,0) [0|1] "" Vector__XXX
 SG_ PDU_LPCh3_Enable : 2|1@1+ (1,0) [0|1] "" Vector__XXX
 SG_ PDU_LPCh2_Enable : 1|1@1+ (1,0) [0|1] "" Vector__XXX
 SG_ PDU_LPCh1_Enable : 0|1@1+ (1,0) [0|1] "" Vector__XXX

BO_ 922 PDU_TX_PDO5: 0 PDU

BO_ 986 PDU_TX_PDO6: 0 PDU

BO_ 1050 PDU_TX_PDO7: 0 PDU

BO_ 1114 PDU_TX_PDO8: 0 PDU

BO_ 1178 PDU_TX_LP_Short_Circuit_Debug: 8 PDU
 SG_ PDU_LPCh9_State : 58|2@1+ (1,0) [0|3] "" Vector__XXX
 SG_ PDU_LPCh8_State : 56|2@1+ (1,0) [0|3] "" Vector__XXX
 SG_ PDU_LPCh7_State : 54|2@1+ (1,0) [0|3] "" Vector__XXX
 SG_ PDU_LPCh6_State : 52|2@1+ (1,0) [0|3] "" Vector__XXX
 SG_ PDU_LPCh5_State : 50|2@1+ (1,0) [0|3] "" Vector__XXX
 SG_ PDU_LPCh4_State : 48|2@1+ (1,0) [0|3] "" Vector__XXX
 SG_ PDU_LPCh3_State : 46|2@1+ (1,0) [0|3] "" Vector__XXX
 SG_ PDU_LPCh2_State : 44|2@1+ (1,0) [0|3] "" Vector__XXX
 SG_ PDU_LPCh1_State : 42|2@1+ (1,0) [0|3] "" Vector__XXX
 SG_ PDU_LPCh10_State : 40|2@1+ (1,0) [0|3] "" Vector__XXX
 SG_ PDU_LPCh9_ShortCnt : 36|4@1+ (1,0) [0|15] "" Vector__XXX
 SG_ PDU_LPCh8_ShortCnt : 32|4@1+ (1,0) [0|15] "" Vector__XXX
 SG_ PDU_LPCh7_ShortCnt : 28|4@1+ (1,0) [0|15] "" Vector__XXX
 SG_ PDU_LPCh6_ShortCnt : 24|4@1+ (1,0) [0|15] "" Vector__XXX
 SG_ PDU_LPCh5_ShortCnt : 20|4@1+ (1,0) [0|15] "" Vector__XXX
 SG_ PDU_LPCh4_ShortCnt : 16|4@1+ (1,0) [0|15] "" Vector__XXX
 SG_ PDU_LPCh3_ShortCnt : 12|4@1+ (1,0) [0|15] "" Vector__XXX
 SG_ PDU_LPCh2_ShortCnt : 8|4@1+ (1,0) [0|15] "" Vector__XXX
 SG_ PDU_LPCh1_ShortCnt : 4|4@1+ (1,0) [0|15] "" Vector__XXX
 SG_ PDU_LPCh10_ShortCnt : 0|4@1+ (1,0) [0|15] "" Vector__XXX

BO_ 1242 PDU_TX_LV_BMS: 4 PDU
 SG_ PDU_LV_SOC : 24|8@1- (1,0) [0|100] "%" Vector__XXX
 SG_ PDU_LV_Voltage : 12|12@1+ (0.01,0) [0|40.95] "V" Vector__XXX
 SG_ PDU_LV_Current : 0|12@1+ (0.01,0) [0|40.95] "A" Vector__XXX

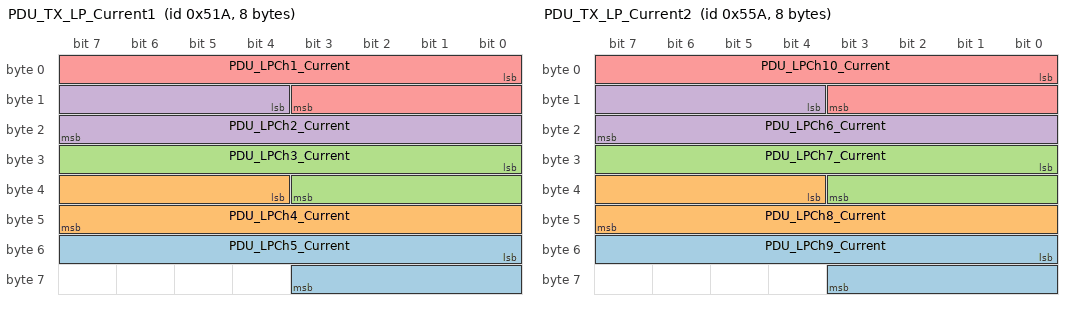
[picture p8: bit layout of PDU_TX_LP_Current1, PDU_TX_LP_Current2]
BO_ 1306 PDU_TX_LP_Current1: 8 PDU
 SG_ PDU_LPCh5_Current : 48|12@1+ (0.002,0) [0|8.19] "A" Vector__XXX
 SG_ PDU_LPCh4_Current : 36|12@1+ (0.002,0) [0|8.19] "A" Vector__XXX
 SG_ PDU_LPCh3_Current : 24|12@1+ (0.002,0) [0|8.19] "A" Vector__XXX
 SG_ PDU_LPCh2_Current : 12|12@1+ (0.002,0) [0|8.19] "A" Vector__XXX
 SG_ PDU_LPCh1_Current : 0|12@1+ (0.002,0) [0|8.19] "A" Vector__XXX

BO_ 1370 PDU_TX_LP_Current2: 8 PDU
 SG_ PDU_LPCh9_Current : 48|12@1+ (0.002,0) [0|8.19] "A" Vector__XXX
 SG_ PDU_LPCh8_Current : 36|12@1+ (0.002,0) [0|8.19] "A" Vector__XXX
 SG_ PDU_LPCh7_Current : 24|12@1+ (0.002,0) [0|8.19] "A" Vector__XXX
 SG_ PDU_LPCh6_Current : 12|12@1+ (0.002,0) [0|8.19] "A" Vector__XXX
 SG_ PDU_LPCh10_Current : 0|12@1+ (0.002,0) [0|8.19] "A" Vector__XXX

BO_ 1434 PDU_SDO_Resp: 8 PDU
 SG_ PDU_OD_CoolingPumpEnabled m2816 : 16|8@1+ (1,0) [0|255] ""  TelemetryNode
 SG_ PDU_OD_LedCommands m2562 : 16|16@1+ (1,0) [0|65535] ""  TelemetryNode
 SG_ PDU_OD_projectXXEnabled m2560 : 16|8@1+ (1,0) [0|255] ""  TelemetryNode
 SG_ PDU_OD_watchdogTimeout m2306 : 16|16@1+ (1,0) [0|65535] "ms"  TelemetryNode
 SG_ PDU_OD_statusSendInterval m2305 : 16|16@1+ (1,0) [0|65535] "ms"  TelemetryNode
 SG_ PDU_OD_currentReadInterval m2304 : 16|16@1+ (1,0) [0|65535] "ms"  TelemetryNode
 SG_ PDU_OD_batteryOvercurrent m2128 : 16|16@1+ (0.01,0) [0|655.35] "A"  TelemetryNode
 SG_ PDU_OD_overTempCritical m2051 : 16|16@1+ (0.1,0) [0|6553.5] "degrees"  TelemetryNode
 SG_ PDU_OD_overTempWarn m2050 : 16|16@1+ (0.1,0) [0|6553.5] "degrees"  TelemetryNode
 SG_ PDU_OD_batterVoltageCritical m2049 : 16|16@1+ (0.01,0) [0|655.35] "V"  TelemetryNode
 SG_ PDU_OD_batterVoltageLow m2048 : 16|16@1+ (0.01,0) [0|655.35] "V"  TelemetryNode
 SG_ PDU_OD_CAN2_DelayedTxMessages m1129 : 16|24@1+ (1,0) [0|16777215] ""  TelemetryNode
 SG_ PDU_OD_CAN2_ErrorStatus m1128 : 16|8@1+ (1,0) [0|255] ""  TelemetryNode
 SG_ PDU_OD_CAN2_DiscardedTxMessages m1127 : 16|24@1+ (1,0) [0|16777215] ""  TelemetryNode
 SG_ PDU_OD_CAN2_Status m1126 : 16|8@1+ (1,0) [0|255] ""  TelemetryNode
 SG_ PDU_OD_CAN2_Baudrate m1124 : 16|16@1+ (1,0) [125|1000] "kbps"  TelemetryNode
 SG_ PDU_OD_CAN2_autoErrorReset m1123 : 16|8@1+ (1,0) [0|255] ""  TelemetryNode
 SG_ PDU_OD_CAN2_lastErrorCode m1122 : 16|32@1+ (1,0) [0|4294967295] ""  TelemetryNode
 SG_ PDU_OD_CAN2_RxErrCnt m1121 : 16|8@1+ (1,0) [0|255] ""  TelemetryNode
 SG_ PDU_OD_CAN2_TxErrCnt m1120 : 16|8@1+ (1,0) [0|255] ""  TelemetryNode
 SG_ PDU_OD_CAN1_DelayedTxMessages m1113 : 16|24@1+ (1,0) [0|16777215] ""  TelemetryNode
 SG_ PDU_OD_CAN1_ErrorStatus m1112 : 16|8@1+ (1,0) [0|255] ""  TelemetryNode
 SG_ PDU_OD_CAN1_DiscardedTxMessages m1111 : 16|24@1+ (1,0) [0|16777215] ""  TelemetryNode
 SG_ PDU_OD_CAN1_Status m1110 : 16|8@1+ (1,0) [0|255] ""  TelemetryNode
 SG_ PDU_OD_CAN1_Baudrate m1108 : 16|16@1+ (1,0) [125|1000] "kbps"  TelemetryNode
 SG_ PDU_OD_CAN1_autoErrorReset m1107 : 16|8@1+ (1,0) [0|255] ""  TelemetryNode
 SG_ PDU_OD_CAN1_lastErrorCode m1106 : 16|32@1+ (1,0) [0|4294967295] ""  TelemetryNode
 SG_ PDU_OD_CAN1_RxErrCnt m1105 : 16|8@1+ (1,0) [0|255] ""  TelemetryNode
 SG_ PDU_OD_CAN1_TxErrCnt m1104 : 16|8@1+ (1,0) [0|255] ""  TelemetryNode
 SG_ PDU_OD_BuildTime m1073 : 16|24@1+ (1,0) [0|16777215] ""  TelemetryNode
 SG_ PDU_OD_BuildDate m1072 : 16|32@1+ (1,0) [0|4294967295] ""  TelemetryNode
 SG_ PDU_OD_ChipUID2 m1057 : 16|48@1+ (1,0) [0|281474976710655] ""  TelemetryNode
 SG_ PDU_OD_ChipUID1 m1056 : 16|48@1+ (1,0) [0|281474976710655] ""  TelemetryNode
 SG_ PDU_OD_SdcOut m1046 : 16|8@1+ (1,0) [0|255] ""  TelemetryNode
 SG_ PDU_OD_SdcIn m1045 : 16|8@1+ (1,0) [0|255] ""  TelemetryNode
 SG_ PDU_OD_runtime m1044 : 16|24@1+ (1,0) [0|16777215] "ms"  TelemetryNode
 SG_ PDU_OD_InputVoltage m1043 : 16|16@1+ (0.001,0) [0|65.535] "V"  TelemetryNode
 SG_ PDU_OD_BoardTemp m1042 : 16|16@1+ (0.01,-30) [-30|625.35] "°C"  TelemetryNode
 SG_ PDU_OD_MemFree m1041 : 16|16@1+ (4,0) [0|262140] "bytes"  TelemetryNode
 SG_ PDU_OD_CpuUsage m1040 : 16|8@1+ (0.5,0) [0|100] "%"  TelemetryNode
 SG_ PDU_OD_OdEntrySendInterval m33 : 16|16@1+ (1,0) [0|65535] "ms"  TelemetryNode
 SG_ PDU_OD_SendOdOnBootup m32 : 16|8@1+ (1,0) [0|255] ""  TelemetryNode
 SG_ PDU_OD_HeartbeatInterval m16 : 16|16@1+ (1,0) [0|65535] "ms"  TelemetryNode
 SG_ PDU_OD_DbcVersion m5 : 16|16@1+ (1,0) [0|65535] ""  TelemetryNode
 SG_ PDU_OD_StackVersion m4 : 16|16@1+ (1,0) [0|65535] ""  TelemetryNode
 SG_ PDU_OD_ProtocolVersion m3 : 16|16@1+ (1,0) [0|65535] ""  TelemetryNode
 SG_ PDU_OD_NodeStatus m2 : 16|8@1+ (1,0) [0|255] ""  TelemetryNode
 SG_ PDU_OD_NodeID m1 : 16|8@1+ (1,0) [0|255] ""  TelemetryNode
 SG_ PDU_SDO_RespCode : 12|4@1+ (1,0) [0|0] ""  TelemetryNode
 SG_ PDU_SDO_ID M : 0|12@1+ (1,0) [0|4095] ""  TelemetryNode

BO_ 1498 PDU_SDO_Req_Up: 8 TelemetryNode
 SG_ PDU_OD_CoolingPumpEnabled m2816 : 16|8@1+ (1,0) [0|255] ""  PDU
 SG_ PDU_OD_LedCommands m2562 : 16|16@1+ (1,0) [0|65535] ""  PDU
 SG_ PDU_OD_projectXXEnabled m2560 : 16|8@1+ (1,0) [0|255] ""  PDU
 SG_ PDU_OD_watchdogTimeout m2306 : 16|16@1+ (1,0) [0|65535] "ms"  PDU
 SG_ PDU_OD_statusSendInterval m2305 : 16|16@1+ (1,0) [0|65535] "ms"  PDU
 SG_ PDU_OD_currentReadInterval m2304 : 16|16@1+ (1,0) [0|65535] "ms"  PDU
 SG_ PDU_OD_batteryOvercurrent m2128 : 16|16@1+ (0.01,0) [0|655.35] "A"  PDU
 SG_ PDU_OD_overTempCritical m2051 : 16|16@1+ (0.1,0) [0|6553.5] "degrees"  PDU
 SG_ PDU_OD_overTempWarn m2050 : 16|16@1+ (0.1,0) [0|6553.5] "degrees"  PDU
 SG_ PDU_OD_batterVoltageCritical m2049 : 16|16@1+ (0.01,0) [0|655.35] "V"  PDU
 SG_ PDU_OD_batterVoltageLow m2048 : 16|16@1+ (0.01,0) [0|655.35] "V"  PDU
 SG_ PDU_OD_CAN2_DelayedTxMessages m1129 : 16|24@1+ (1,0) [0|16777215] ""  PDU
 SG_ PDU_OD_CAN2_ErrorStatus m1128 : 16|8@1+ (1,0) [0|255] ""  PDU
 SG_ PDU_OD_CAN2_DiscardedTxMessages m1127 : 16|24@1+ (1,0) [0|16777215] ""  PDU
 SG_ PDU_OD_CAN2_Status m1126 : 16|8@1+ (1,0) [0|255] ""  PDU
 SG_ PDU_OD_CAN2_Baudrate m1124 : 16|16@1+ (1,0) [125|1000] "kbps"  PDU
 SG_ PDU_OD_CAN2_autoErrorReset m1123 : 16|8@1+ (1,0) [0|255] ""  PDU
 SG_ PDU_OD_CAN2_lastErrorCode m1122 : 16|32@1+ (1,0) [0|4294967295] ""  PDU
 SG_ PDU_OD_CAN2_RxErrCnt m1121 : 16|8@1+ (1,0) [0|255] ""  PDU
 SG_ PDU_OD_CAN2_TxErrCnt m1120 : 16|8@1+ (1,0) [0|255] ""  PDU
 SG_ PDU_OD_CAN1_DelayedTxMessages m1113 : 16|24@1+ (1,0) [0|16777215] ""  PDU
 SG_ PDU_OD_CAN1_ErrorStatus m1112 : 16|8@1+ (1,0) [0|255] ""  PDU
 SG_ PDU_OD_CAN1_DiscardedTxMessages m1111 : 16|24@1+ (1,0) [0|16777215] ""  PDU
 SG_ PDU_OD_CAN1_Status m1110 : 16|8@1+ (1,0) [0|255] ""  PDU
 SG_ PDU_OD_CAN1_Baudrate m1108 : 16|16@1+ (1,0) [125|1000] "kbps"  PDU
 SG_ PDU_OD_CAN1_autoErrorReset m1107 : 16|8@1+ (1,0) [0|255] ""  PDU
 SG_ PDU_OD_CAN1_lastErrorCode m1106 : 16|32@1+ (1,0) [0|4294967295] ""  PDU
 SG_ PDU_OD_CAN1_RxErrCnt m1105 : 16|8@1+ (1,0) [0|255] ""  PDU
 SG_ PDU_OD_CAN1_TxErrCnt m1104 : 16|8@1+ (1,0) [0|255] ""  PDU
 SG_ PDU_OD_BuildTime m1073 : 16|24@1+ (1,0) [0|16777215] ""  PDU
 SG_ PDU_OD_BuildDate m1072 : 16|32@1+ (1,0) [0|4294967295] ""  PDU
 SG_ PDU_OD_ChipUID2 m1057 : 16|48@1+ (1,0) [0|281474976710655] ""  PDU
 SG_ PDU_OD_ChipUID1 m1056 : 16|48@1+ (1,0) [0|281474976710655] ""  PDU
 SG_ PDU_OD_SdcOut m1046 : 16|8@1+ (1,0) [0|255] ""  PDU
 SG_ PDU_OD_SdcIn m1045 : 16|8@1+ (1,0) [0|255] ""  PDU
 SG_ PDU_OD_runtime m1044 : 16|24@1+ (1,0) [0|16777215] "ms"  PDU
 SG_ PDU_OD_InputVoltage m1043 : 16|16@1+ (0.001,0) [0|65.535] "V"  PDU
 SG_ PDU_OD_BoardTemp m1042 : 16|16@1+ (0.01,-30) [-30|625.35] "°C"  PDU
 SG_ PDU_OD_MemFree m1041 : 16|16@1+ (4,0) [0|262140] "bytes"  PDU
 SG_ PDU_OD_CpuUsage m1040 : 16|8@1+ (0.5,0) [0|100] "%"  PDU
 SG_ PDU_OD_OdEntrySendInterval m33 : 16|16@1+ (1,0) [0|65535] "ms"  PDU
 SG_ PDU_OD_SendOdOnBootup m32 : 16|8@1+ (1,0) [0|255] ""  PDU
 SG_ PDU_OD_HeartbeatInterval m16 : 16|16@1+ (1,0) [0|65535] "ms"  PDU
 SG_ PDU_OD_DbcVersion m5 : 16|16@1+ (1,0) [0|65535] ""  PDU
 SG_ PDU_OD_StackVersion m4 : 16|16@1+ (1,0) [0|65535] ""  PDU
 SG_ PDU_OD_ProtocolVersion m3 : 16|16@1+ (1,0) [0|65535] ""  PDU
 SG_ PDU_OD_NodeStatus m2 : 16|8@1+ (1,0) [0|255] ""  PDU
 SG_ PDU_OD_NodeID m1 : 16|8@1+ (1,0) [0|255] ""  PDU
 SG_ PDU_SDO_ID M : 0|12@1+ (1,0) [0|4095] ""  PDU

BO_ 1562 PDU_SDO_Req_Down: 2 TelemetryNode
 SG_ PDU_SDO_ID M : 0|12@1+ (1,0) [0|4095] ""  PDU

BO_ 1818 PDU_Heartbeat: 1 PDU
 SG_ PDU_NodeState : 0|8@1+ (1,0) [0|0] ""  SensorF,Master,TelemetryNode

BO_ 1882 PDU_BTL_TX: 8 PDU

BO_ 1946 PDU_BTL_RX: 8 TelemetryNode

BO_ 138 HVCU_EMCY: 4 HVCU
 SG_ HVCU_E19_ChargingModeError : 31|1@1+ (1,0) [0|0] ""  Master,TelemetryNode
 SG_ HVCU_E18_SDCSwitchError : 30|1@1+ (1,0) [0|0] ""  Master,TelemetryNode
 SG_ HVCU_E17_ControlMessageTimeout : 29|1@1+ (1,0) [0|0] ""  Master,TelemetryNode
 SG_ HVCU_E16_NoEnable : 28|1@1+ (1,0) [0|0] ""  Master,TelemetryNode
 SG_ HVCU_E15_SDCOpen : 27|1@1+ (1,0) [0|0] ""  Master,TelemetryNode
 SG_ HVCU_E14_HVMPError : 26|1@1+ (1,0) [0|0] ""  Master,TelemetryNode
 SG_ HVCU_E13_BIR4Error : 25|1@1+ (1,0) [0|0] ""  Master,TelemetryNode
 SG_ HVCU_E12_BIR3Error : 24|1@1+ (1,0) [0|0] ""  Master,TelemetryNode
 SG_ HVCU_E11_BIR2Error : 23|1@1+ (1,0) [0|0] ""  Master,TelemetryNode
 SG_ HVCU_E10_BIR1Error : 22|1@1+ (1,0) [0|0] ""  Master,TelemetryNode
 SG_ HVCU_E9_HVSLError : 21|1@1+ (1,0) [0|0] ""  Master,TelemetryNode
 SG_ HVCU_E8_VoltageMeasuring : 20|1@1+ (1,0) [0|0] ""  Master,TelemetryNode
 SG_ HVCU_E7_BALError : 19|1@1+ (1,0) [0|0] ""  Master,TelemetryNode
 SG_ HVCU_E6_DischargeError : 18|1@1+ (1,0) [0|0] ""  Master,TelemetryNode
 SG_ HVCU_E5_DischargeTimeout : 17|1@1+ (1,0) [0|0] ""  Master,TelemetryNode
 SG_ HVCU_E4_BMSPermissionMissing : 16|1@1+ (1,0) [0|0] ""  Master,TelemetryNode
 SG_ HVCU_E3_PrechargeError : 15|1@1+ (1,0) [0|0] ""  Master,TelemetryNode
 SG_ HVCU_E2_BMSError : 14|1@1+ (1,0) [0|0] ""  Master,TelemetryNode
 SG_ HVCU_E1_IMDError : 13|1@1+ (1,0) [0|0] ""  Master,TelemetryNode
 SG_ HVCU_E0_OtherError : 12|1@1+ (1,0) [0|0] ""  Master,TelemetryNode
 SG_ HVCU_W8_ChargingMode : 8|1@1+ (1,0) [0|0] ""  Master,TelemetryNode
 SG_ HVCU_W7_IsolationResistanceLow : 7|1@1+ (1,0) [0|0] ""  Master,TelemetryNode
 SG_ HVCU_W6_Bir4On : 6|1@1+ (1,0) [0|0] ""  Master,TelemetryNode
 SG_ HVCU_W5_Bir3On : 5|1@1+ (1,0) [0|0] ""  Master,TelemetryNode
 SG_ HVCU_W4_Bir2On : 4|1@1+ (1,0) [0|0] ""  Master,TelemetryNode
 SG_ HVCU_W3_Bir1On : 3|1@1+ (1,0) [0|0] ""  Master,TelemetryNode
 SG_ HVCU_W2_PreChargeOn : 2|1@1+ (1,0) [0|0] ""  Master,TelemetryNode
 SG_ HVCU_W1_HighVoltage : 1|1@1+ (1,0) [0|0] ""  Master,TelemetryNode
 SG_ HVCU_W0_OtherWarning : 0|1@1+ (1,0) [0|0] ""  Master,TelemetryNode

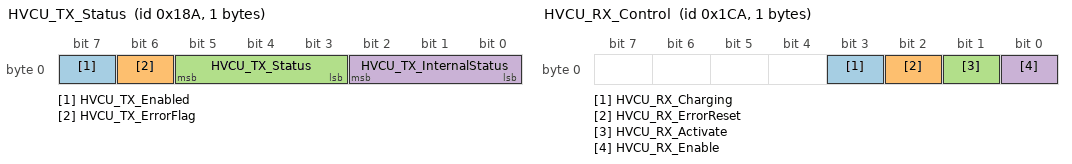
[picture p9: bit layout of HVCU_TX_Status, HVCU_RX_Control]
BO_ 394 HVCU_TX_Status: 1 HVCU
 SG_ HVCU_TX_Enabled : 7|1@1+ (1,0) [0|0] ""  SensorF
 SG_ HVCU_TX_ErrorFlag : 6|1@1+ (1,0) [0|0] ""  SensorF
 SG_ HVCU_TX_Status : 3|3@1+ (1,0) [0|0] ""  SensorF
 SG_ HVCU_TX_InternalStatus : 0|3@1+ (1,0) [0|0] ""  SensorF

BO_ 458 HVCU_RX_Control: 1 SensorF
 SG_ HVCU_RX_Charging : 3|1@1+ (1,0) [0|0] "" Vector__XXX
 SG_ HVCU_RX_ErrorReset : 2|1@1+ (1,0) [0|0] "" Vector__XXX
 SG_ HVCU_RX_Activate : 1|1@1+ (1,0) [0|0] "" Vector__XXX
 SG_ HVCU_RX_Enable : 0|1@1+ (1,0) [0|0] "" Vector__XXX

BO_ 522 HVCU_TX_PDO2: 0 HVCU

BO_ 586 HVCU_RX_PDO2: 0 Vector__XXX

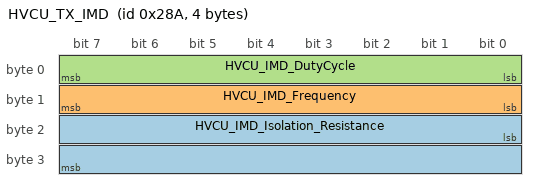
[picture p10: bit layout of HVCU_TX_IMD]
BO_ 650 HVCU_TX_IMD: 4 HVCU
 SG_ HVCU_IMD_Isolation_Resistance : 16|16@1+ (1,0) [0|65535] "kOhm" Vector__XXX
 SG_ HVCU_IMD_Frequency : 8|8@1+ (1,0) [0|60] "Hz" Vector__XXX
 SG_ HVCU_IMD_DutyCycle : 0|8@1+ (1,0) [0|100] "%" Vector__XXX

BO_ 714 HVCU_RX_PDO3: 0 Vector__XXX

BO_ 778 HVCU_TX_PDO4: 0 HVCU

BO_ 842 HVCU_RX_PDO4: 0 Vector__XXX

BO_ 906 HVCU_TX_PDO5: 0 HVCU

BO_ 970 HVCU_TX_PDO6: 0 HVCU

BO_ 1034 HVCU_TX_PDO7: 0 HVCU

BO_ 1098 HVCU_TX_PDO8: 0 HVCU

BO_ 1162 HVCU_TX_PDO9: 0 HVCU

BO_ 1226 HVCU_TX_PDO10: 0 HVCU

BO_ 1290 HVCU_TX_PDO11: 0 HVCU

BO_ 1354 HVCU_TX_PDO12: 0 HVCU

BO_ 1418 HVCU_SDO_Resp: 8 HVCU
 SG_ HVCU_OD_CAN2_DelayedTxMessages m1129 : 16|24@1+ (1,0) [0|16777215] ""  TelemetryNode
 SG_ HVCU_OD_CAN2_ErrorStatus m1128 : 16|8@1+ (1,0) [0|255] ""  TelemetryNode
 SG_ HVCU_OD_CAN2_DiscardedTxMessages m1127 : 16|24@1+ (1,0) [0|16777215] ""  TelemetryNode
 SG_ HVCU_OD_CAN2_Status m1126 : 16|8@1+ (1,0) [0|255] ""  TelemetryNode
 SG_ HVCU_OD_CAN2_Baudrate m1124 : 16|16@1+ (1,0) [125|1000] "kbps"  TelemetryNode
 SG_ HVCU_OD_CAN2_autoErrorReset m1123 : 16|8@1+ (1,0) [0|255] ""  TelemetryNode
 SG_ HVCU_OD_CAN2_lastErrorCode m1122 : 16|32@1+ (1,0) [0|4294967295] ""  TelemetryNode
 SG_ HVCU_OD_CAN2_RxErrCnt m1121 : 16|8@1+ (1,0) [0|255] ""  TelemetryNode
 SG_ HVCU_OD_CAN2_TxErrCnt m1120 : 16|8@1+ (1,0) [0|255] ""  TelemetryNode
 SG_ HVCU_OD_CAN1_DelayedTxMessages m1113 : 16|24@1+ (1,0) [0|16777215] ""  TelemetryNode
 SG_ HVCU_OD_CAN1_ErrorStatus m1112 : 16|8@1+ (1,0) [0|255] ""  TelemetryNode
 SG_ HVCU_OD_CAN1_DiscardedTxMessages m1111 : 16|24@1+ (1,0) [0|16777215] ""  TelemetryNode
 SG_ HVCU_OD_CAN1_Status m1110 : 16|8@1+ (1,0) [0|255] ""  TelemetryNode
 SG_ HVCU_OD_CAN1_Baudrate m1108 : 16|16@1+ (1,0) [125|1000] "kbps"  TelemetryNode
 SG_ HVCU_OD_CAN1_autoErrorReset m1107 : 16|8@1+ (1,0) [0|255] ""  TelemetryNode
 SG_ HVCU_OD_CAN1_lastErrorCode m1106 : 16|32@1+ (1,0) [0|4294967295] ""  TelemetryNode
 SG_ HVCU_OD_CAN1_RxErrCnt m1105 : 16|8@1+ (1,0) [0|255] ""  TelemetryNode
 SG_ HVCU_OD_CAN1_TxErrCnt m1104 : 16|8@1+ (1,0) [0|255] ""  TelemetryNode
 SG_ HVCU_OD_BuildTime m1073 : 16|24@1+ (1,0) [0|16777215] ""  TelemetryNode
 SG_ HVCU_OD_BuildDate m1072 : 16|32@1+ (1,0) [0|4294967295] ""  TelemetryNode
 SG_ HVCU_OD_ChipUID2 m1057 : 16|48@1+ (1,0) [0|281474976710655] ""  TelemetryNode
 SG_ HVCU_OD_ChipUID1 m1056 : 16|48@1+ (1,0) [0|281474976710655] ""  TelemetryNode
 SG_ HVCU_OD_SdcOut m1046 : 16|8@1+ (1,0) [0|255] ""  TelemetryNode
 SG_ HVCU_OD_SdcIn m1045 : 16|8@1+ (1,0) [0|255] ""  TelemetryNode
 SG_ HVCU_OD_runtime m1044 : 16|24@1+ (1,0) [0|16777215] "ms"  TelemetryNode
 SG_ HVCU_OD_InputVoltage m1043 : 16|16@1+ (0.001,0) [0|65.535] "V"  TelemetryNode
 SG_ HVCU_OD_BoardTemp m1042 : 16|16@1+ (0.01,-30) [-30|625.35] "°C"  TelemetryNode
 SG_ HVCU_OD_MemFree m1041 : 16|16@1+ (4,0) [0|262140] "bytes"  TelemetryNode
 SG_ HVCU_OD_CpuUsage m1040 : 16|8@1+ (0.5,0) [0|100] "%"  TelemetryNode
 SG_ HVCU_OD_OdEntrySendInterval m33 : 16|16@1+ (1,0) [0|65535] "ms"  TelemetryNode
 SG_ HVCU_OD_SendOdOnBootup m32 : 16|8@1+ (1,0) [0|255] ""  TelemetryNode
 SG_ HVCU_OD_HeartbeatInterval m16 : 16|16@1+ (1,0) [0|65535] "ms"  TelemetryNode
 SG_ HVCU_OD_DbcVersion m5 : 16|16@1+ (1,0) [0|65535] ""  TelemetryNode
 SG_ HVCU_OD_StackVersion m4 : 16|16@1+ (1,0) [0|65535] ""  TelemetryNode
 SG_ HVCU_OD_ProtocolVersion m3 : 16|16@1+ (1,0) [0|65535] ""  TelemetryNode
 SG_ HVCU_OD_NodeStatus m2 : 16|8@1+ (1,0) [0|255] ""  TelemetryNode
 SG_ HVCU_OD_NodeID m1 : 16|8@1+ (1,0) [0|255] ""  TelemetryNode
 SG_ HVCU_SDO_RespCode : 12|4@1+ (1,0) [0|0] ""  TelemetryNode
 SG_ HVCU_SDO_ID M : 0|12@1+ (1,0) [0|4095] ""  TelemetryNode

CM_ BO_ 1538 "DO NOT CHANGE ANYTHING HERE!
SDO Request Download from node SensorR with Node-ID 0x2";
CM_ SG_ 1538 SensorR_SDO_ID "Specifies SDO-ID of SensorR";
CM_ BO_ 1794 "Heartbeat of node SensorR with Node-ID 0x2";
CM_ SG_ 1794 SensorR_NodeState "Heartbeat status of node SensorR";
CM_ BO_ 1858 "Bootloader transmit from node SensorR with Node-ID 0x2";
CM_ BO_ 1922 "Bootloader receive by node SensorR with Node-ID 0x2";
CM_ BO_ 145 "Emergency message of node BrakeF with Node-ID 0x11";
CM_ SG_ 145 BrakeF_E5_retractUnsuccesful_ope "Instruction to retract was received, but the SDC is detected to be open";
CM_ SG_ 145 BrakeF_E4_retractUnsuccesful_not "Instruction to retract was received, but the ECU is not enabled";
CM_ SG_ 145 BrakeF_E3_retractUnsuccesful_err "Instruction to retract was received, but an error flag inhibited retraction";
CM_ SG_ 145 BrakeF_E2_commWatchdogTimeout "Communication Watchdog timeout. It took more than the time set to receive a new message from the state machine";
CM_ SG_ 145 BrakeF_E1_pressureTooLow "Pressure tank has a lower value than the provided LowerControlLimit";
CM_ SG_ 145 BrakeF_E0_pressureTooHigh "Pressure tank has a higher value than the provided UpperControlLimit";
CM_ SG_ 145 BrakeF_W3_externalError "SDC reading indicates it's open, but there's no internal error in the ECU";
CM_ SG_ 145 BrakeF_W2_enableWithAnError "The ECU was enabled with an error flag";
CM_ SG_ 145 BrakeF_W1_highPressureRetracting "Pressure higher than desired was measured in the acting chamber";
CM_ SG_ 145 BrakeF_W0_highPressureActingCham "Pressure higher than desired was measured in the acting chamber";
CM_ BO_ 401 "Transmit PDO 1 of node BrakeF with Node-ID 0x11";
CM_ SG_ 401 BrakeF_TX_SDC_Input "Sends the current value of the SDC received by BrakeF.
";
CM_ SG_ 401 BrakeF_TX_ErrorFlag "Error status of BrakeF.";
CM_ SG_ 401 BrakeF_TX_Enabled "Enable status of BrakeF.";
CM_ SG_ 401 BrakeF_TX_Status "Status signal of BrakeF.";
CM_ BO_ 465 "Receive PDO 1 of node BrakeF with Node-ID 0x11";
CM_ SG_ 465 BrakeF_RX_Engage "Engage signal for BrakeF.";
CM_ SG_ 465 BrakeF_RX_Enable "Enable signal for BrakeF.";
CM_ SG_ 465 BrakeF_RX_ErrorReset "Error reset signal for BrakeF.";
CM_ BO_ 529 "Transmit PDO 2 of node BrakeF with Node-ID 0x11";
CM_ BO_ 593 "Receive PDO 2 of node BrakeF with Node-ID 0x11";
CM_ BO_ 657 "Transmit PDO 3 of node BrakeF with Node-ID 0x11";
CM_ BO_ 721 "Receive PDO 3 of node BrakeF with Node-ID 0x11";
CM_ BO_ 785 "Transmit PDO 4 of node BrakeF with Node-ID 0x11";
CM_ BO_ 849 "Receive PDO 4 of node BrakeF with Node-ID 0x11";
CM_ BO_ 913 "Transmit PDO 5 of node BrakeF with Node-ID 0x11";
CM_ BO_ 977 "Transmit PDO 6 of node BrakeF with Node-ID 0x11";
CM_ BO_ 1041 "Transmit PDO 7 of node BrakeF with Node-ID 0x11";
CM_ BO_ 1105 "Transmit PDO 8 of node BrakeF with Node-ID 0x11";
CM_ BO_ 1169 "Transmit PDO 9 of node BrakeF with Node-ID 0x11";
CM_ BO_ 1233 "Transmit PDO 10 of node BrakeF with Node-ID 0x11";
CM_ BO_ 1297 "Transmit PDO 11 of node BrakeF with Node-ID 0x11";
CM_ BO_ 1361 "Transmit PDO 12 of node BrakeF with Node-ID 0x11";
CM_ BO_ 1425 "DO NOT CHANGE ANYTHING HERE!
SDO Response of node BrakeF with Node-ID 0x11";
CM_ SG_ 1425 BrakeF_OD_valveUpperTolerance "Tolerance of the lower pressure pneumatic circuit";
CM_ SG_ 1425 BrakeF_OD_commWatchdog "Max. number of ms to receive a new message";
CM_ SG_ 1425 BrakeF_OD_counterLimit "Number of cycles in the loop to measure pressure once";
CM_ SG_ 1425 BrakeF_OD_delay "Delay used in every cycle of the loop.";
CM_ SG_ 1425 BrakeF_OD_tankUpperControlLimit "Maximum pressure of tank in bar.";
CM_ SG_ 1425 BrakeF_OD_tankLowerControlLimit "Minimum pressure of tank in bar.";
CM_ SG_ 1425 BrakeF_OD_CAN2_DelayedTxMessages "Number of delayed TX messages on CAN2 because no messagebox was free.";
CM_ SG_ 1425 BrakeF_OD_CAN2_ErrorStatus "Internal error status (e.g. Error active, Error passive, Bus Off)";
CM_ SG_ 1425 BrakeF_OD_CAN2_DiscardedTxMessag "Number of discarded TX messages on CAN2 because all messageboxes were full";
CM_ SG_ 1425 BrakeF_OD_CAN2_Status "Status of CAN2.";
CM_ SG_ 1425 BrakeF_OD_CAN2_Baudrate "Baudrate of CAN.";
CM_ SG_ 1425 BrakeF_OD_CAN2_autoErrorReset "Automatic reset of errors.";
CM_ SG_ 1425 BrakeF_OD_CAN2_lastErrorCode "Last error code.";
CM_ SG_ 1425 BrakeF_OD_CAN2_RxErrCnt "Receive error count of CAN1.";
CM_ SG_ 1425 BrakeF_OD_CAN2_TxErrCnt "Transmit error count of CAN1.";
CM_ SG_ 1425 BrakeF_OD_CAN1_DelayedTxMessages "Number of delayed TX messages on CAN1 because no messagebox was free.";
CM_ SG_ 1425 BrakeF_OD_CAN1_ErrorStatus "Internal error status (e.g. Error active, Error passive, Bus Off)";
CM_ SG_ 1425 BrakeF_OD_CAN1_DiscardedTxMessag "Number of discarded TX messages on CAN1 because all messageboxes were full";
CM_ SG_ 1425 BrakeF_OD_CAN1_Status "Status of CAN1.";
CM_ SG_ 1425 BrakeF_OD_CAN1_Baudrate "Baudrate of CAN.";
CM_ SG_ 1425 BrakeF_OD_CAN1_autoErrorReset "Automatic reset of errors.";
CM_ SG_ 1425 BrakeF_OD_CAN1_lastErrorCode "Last error code.";
CM_ SG_ 1425 BrakeF_OD_CAN1_RxErrCnt "Receive error count of CAN1.";
CM_ SG_ 1425 BrakeF_OD_CAN1_TxErrCnt "Transmit error count of CAN1.";
CM_ SG_ 1425 BrakeF_OD_BuildTime "Software build time in the format HHMMSS.";
CM_ SG_ 1425 BrakeF_OD_BuildDate "Software build date in the format YYYYMMDD.";
CM_ SG_ 1425 BrakeF_OD_ChipUID2 "Seccond part of unique ID of microcontroller.";
CM_ SG_ 1425 BrakeF_OD_ChipUID1 "First part of unique ID of microcontroller.";
CM_ SG_ 1425 BrakeF_OD_SdcOut "Measurement of Shutdown Circuit Output";
CM_ SG_ 1425 BrakeF_OD_SdcIn "Measurement of Shutdown Circuit Input";
CM_ SG_ 1425 BrakeF_OD_runtime "Runtime of chip in milliseconds.";
CM_ SG_ 1425 BrakeF_OD_InputVoltage "Board supply voltage.";
CM_ SG_ 1425 BrakeF_OD_BoardTemp "Temperature of board";
CM_ SG_ 1425 BrakeF_OD_MemFree "Free memory in bytes.";
CM_ SG_ 1425 BrakeF_OD_CpuUsage "Current CPU usage in %.";
CM_ SG_ 1425 BrakeF_OD_OdEntrySendInterval "Interval for sending all readable OD entries. Sending is disabled if less than 5 ms.";
CM_ SG_ 1425 BrakeF_OD_SendOdOnBootup "Whether to send all OD entries on bootup.";
CM_ SG_ 1425 BrakeF_OD_HeartbeatInterval "Heartbeat Interval in milliseconds.";
CM_ SG_ 1425 BrakeF_OD_DbcVersion "CANzero DBC version.";
CM_ SG_ 1425 BrakeF_OD_StackVersion "CANzero stack version.";
CM_ SG_ 1425 BrakeF_OD_ProtocolVersion "CANzero Protocol Version.";
CM_ SG_ 1425 BrakeF_OD_NodeStatus "State of the node.";
CM_ SG_ 1425 BrakeF_OD_NodeID "CANzero Node-ID.";
CM_ SG_ 1425 BrakeF_SDO_RespCode "Response code of SDO access.";
CM_ SG_ 1425 BrakeF_SDO_ID "Specifies SDO-ID of BrakeF";
CM_ BO_ 1489 "DO NOT CHANGE ANYTHING HERE!
SDO Request Upload to node BrakeF with Node-ID 0x11";
CM_ SG_ 1489 BrakeF_OD_valveUpperTolerance "Tolerance of the lower pressure pneumatic circuit";
CM_ SG_ 1489 BrakeF_OD_commWatchdog "Max. number of ms to receive a new message";
CM_ SG_ 1489 BrakeF_OD_counterLimit "Number of cycles in the loop to measure pressure once";
CM_ SG_ 1489 BrakeF_OD_delay "Delay used in every cycle of the loop.";
CM_ SG_ 1489 BrakeF_OD_tankUpperControlLimit "Maximum pressure of tank in bar.";
CM_ SG_ 1489 BrakeF_OD_tankLowerControlLimit "Minimum pressure of tank in bar.";
CM_ SG_ 1489 BrakeF_OD_CAN2_DelayedTxMessages "Number of delayed TX messages on CAN2 because no messagebox was free.";
CM_ SG_ 1489 BrakeF_OD_CAN2_ErrorStatus "Internal error status (e.g. Error active, Error passive, Bus Off)";
CM_ SG_ 1489 BrakeF_OD_CAN2_DiscardedTxM_0000 "Number of discarded TX messages on CAN2 because all messageboxes were full";
CM_ SG_ 1489 BrakeF_OD_CAN2_Status "Status of CAN2.";
CM_ SG_ 1489 BrakeF_OD_CAN2_Baudrate "Baudrate of CAN.";
CM_ SG_ 1489 BrakeF_OD_CAN2_autoErrorReset "Automatic reset of errors.";
CM_ SG_ 1489 BrakeF_OD_CAN2_lastErrorCode "Last error code.";
CM_ SG_ 1489 BrakeF_OD_CAN2_RxErrCnt "Receive error count of CAN1.";
CM_ SG_ 1489 BrakeF_OD_CAN2_TxErrCnt "Transmit error count of CAN1.";
CM_ SG_ 1489 BrakeF_OD_CAN1_DelayedTxMessages "Number of delayed TX messages on CAN1 because no messagebox was free.";
CM_ SG_ 1489 BrakeF_OD_CAN1_ErrorStatus "Internal error status (e.g. Error active, Error passive, Bus Off)";
CM_ SG_ 1489 BrakeF_OD_CAN1_DiscardedTxM_0000 "Number of discarded TX messages on CAN1 because all messageboxes were full";
CM_ SG_ 1489 BrakeF_OD_CAN1_Status "Status of CAN1.";
CM_ SG_ 1489 BrakeF_OD_CAN1_Baudrate "Baudrate of CAN.";
CM_ SG_ 1489 BrakeF_OD_CAN1_autoErrorReset "Automatic reset of errors.";
CM_ SG_ 1489 BrakeF_OD_CAN1_lastErrorCode "Last error code.";
CM_ SG_ 1489 BrakeF_OD_CAN1_RxErrCnt "Receive error count of CAN1.";
CM_ SG_ 1489 BrakeF_OD_CAN1_TxErrCnt "Transmit error count of CAN1.";
CM_ SG_ 1489 BrakeF_OD_BuildTime "Software build time in the format HHMMSS.";
CM_ SG_ 1489 BrakeF_OD_BuildDate "Software build date in the format YYYYMMDD.";
CM_ SG_ 1489 BrakeF_OD_ChipUID2 "Seccond part of unique ID of microcontroller.";
CM_ SG_ 1489 BrakeF_OD_ChipUID1 "First part of unique ID of microcontroller.";
CM_ SG_ 1489 BrakeF_OD_SdcOut "Measurement of Shutdown Circuit Output";
CM_ SG_ 1489 BrakeF_OD_SdcIn "Measurement of Shutdown Circuit Input";
CM_ SG_ 1489 BrakeF_OD_runtime "Runtime of chip in milliseconds.";
CM_ SG_ 1489 BrakeF_OD_InputVoltage "Board supply voltage.";
CM_ SG_ 1489 BrakeF_OD_BoardTemp "Temperature of board";
CM_ SG_ 1489 BrakeF_OD_MemFree "Free memory in bytes.";
CM_ SG_ 1489 BrakeF_OD_CpuUsage "Current CPU usage in %.";
CM_ SG_ 1489 BrakeF_OD_OdEntrySendInterval "Interval for sending all readable OD entries. Sending is disabled if less than 5 ms.";
CM_ SG_ 1489 BrakeF_OD_SendOdOnBootup "Whether to send all OD entries on bootup.";
CM_ SG_ 1489 BrakeF_OD_HeartbeatInterval "Heartbeat Interval in milliseconds.";
CM_ SG_ 1489 BrakeF_OD_DbcVersion "CANzero DBC version.";
CM_ SG_ 1489 BrakeF_OD_StackVersion "CANzero stack version.";
CM_ SG_ 1489 BrakeF_OD_ProtocolVersion "CANzero Protocol Version.";
CM_ SG_ 1489 BrakeF_OD_NodeStatus "State of the node.";
CM_ SG_ 1489 BrakeF_OD_NodeID "CANzero Node-ID.";
CM_ SG_ 1489 BrakeF_SDO_ID "Specifies SDO-ID of BrakeF";
CM_ BO_ 1553 "DO NOT CHANGE ANYTHING HERE!
SDO Request Download from node BrakeF with Node-ID 0x11";
CM_ SG_ 1553 BrakeF_SDO_ID "Specifies SDO-ID of BrakeF";
CM_ BO_ 1809 "Heartbeat of node BrakeF with Node-ID 0x11";
CM_ SG_ 1809 BrakeF_NodeState "Heartbeat status of node BrakeF";
CM_ BO_ 1873 "Bootloader transmit from node BrakeF with Node-ID 0x11";
CM_ BO_ 1937 "Bootloader receive by node BrakeF with Node-ID 0x11";
CM_ BO_ 146 "Emergency message of node BrakeR with Node-ID 0x12";
CM_ SG_ 146 BrakeR_E5_retractUnsuccesful_ope "Instruction to retract was received, but the SDC is detected to be open";
CM_ SG_ 146 BrakeR_E4_retractUnsuccesful_not "Instruction to retract was received, but the ECU is not enabled";
CM_ SG_ 146 BrakeR_E3_retractUnsuccesful_err "Instruction to retract was received, but an error flag inhibited retraction";
CM_ SG_ 146 BrakeR_E2_commWatchdogTimeout "Communication Watchdog timeout. It took more than the time set to receive a new message from the state machine";
CM_ SG_ 146 BrakeR_E1_pressureTooLow "Pressure tank has a lower value than the provided LowerControlLimit";
CM_ SG_ 146 BrakeR_E0_pressureTooHigh "Pressure tank has a higher value than the provided UpperControlLimit";
CM_ SG_ 146 BrakeR_W3_externalError "SDC reading indicates it's open, but there's no internal error in the ECU";
CM_ SG_ 146 BrakeR_W2_enableWithAnError "The ECU was enabled with an error flag";
CM_ SG_ 146 BrakeR_W1_highPressureRetracting "Pressure higher than desired was measured in the acting chamber";
CM_ SG_ 146 BrakeR_W0_highPressureActingCham "Pressure higher than desired was measured in the acting chamber";
CM_ BO_ 402 "Transmit PDO 1 of node BrakeR with Node-ID 0x12";
CM_ SG_ 402 BrakeR_TX_SDC_Input "Sends the current value of the SDC received by BrakeR.
";
CM_ SG_ 402 BrakeR_TX_ErrorFlag "Error status of BrakeR.";
CM_ SG_ 402 BrakeR_TX_Enabled "Enable status of BrakeR.";
CM_ SG_ 402 BrakeR_TX_Status "Status signal of BrakeR.";
CM_ BO_ 466 "Receive PDO 1 of node BrakeR with Node-ID 0x12";
CM_ SG_ 466 BrakeR_RX_Engage "Engage signal for BrakeR.";
CM_ SG_ 466 BrakeR_RX_Enable "Enable signal for BrakeR.";
CM_ SG_ 466 BrakeR_RX_ErrorReset "Error reset signal for BrakeR.";
CM_ BO_ 530 "Transmit PDO 2 of node BrakeR with Node-ID 0x12";
CM_ BO_ 594 "Receive PDO 2 of node BrakeR with Node-ID 0x12";
CM_ BO_ 658 "Transmit PDO 3 of node BrakeR with Node-ID 0x12";
CM_ BO_ 722 "Receive PDO 3 of node BrakeR with Node-ID 0x12";
CM_ BO_ 786 "Transmit PDO 4 of node BrakeR with Node-ID 0x12";
CM_ BO_ 850 "Receive PDO 4 of node BrakeR with Node-ID 0x12";
CM_ BO_ 914 "Transmit PDO 5 of node BrakeR with Node-ID 0x12";
CM_ BO_ 978 "Transmit PDO 6 of node BrakeR with Node-ID 0x12";
CM_ BO_ 1042 "Transmit PDO 7 of node BrakeR with Node-ID 0x12";
CM_ BO_ 1106 "Transmit PDO 8 of node BrakeR with Node-ID 0x12";
CM_ BO_ 1170 "Transmit PDO 9 of node BrakeR with Node-ID 0x12";
CM_ BO_ 1234 "Transmit PDO 10 of node BrakeR with Node-ID 0x12";
CM_ BO_ 1298 "Transmit PDO 11 of node BrakeR with Node-ID 0x12";
CM_ BO_ 1362 "Transmit PDO 12 of node BrakeR with Node-ID 0x12";
CM_ BO_ 1426 "DO NOT CHANGE ANYTHING HERE!
SDO Response of node BrakeR with Node-ID 0x12";
CM_ SG_ 1426 BrakeR_OD_valveUpperTolerance "Tolerance of the lower pressure pneumatic circuit";
CM_ SG_ 1426 BrakeR_OD_commWatchdog "Max. number of ms to receive a new message";
CM_ SG_ 1426 BrakeR_OD_counterLimit "Number of cycles in the loop to measure pressure once";
CM_ SG_ 1426 BrakeR_OD_delay "Delay used in every cycle of the loop.";
CM_ SG_ 1426 BrakeR_OD_tankUpperControlLimit "Maximum pressure of tank in bar.";
CM_ SG_ 1426 BrakeR_OD_tankLowerControlLimit "Minimum pressure of tank in bar.";
CM_ SG_ 1426 BrakeR_OD_CAN2_DelayedTxMessages "Number of delayed TX messages on CAN2 because no messagebox was free.";
CM_ SG_ 1426 BrakeR_OD_CAN2_ErrorStatus "Internal error status (e.g. Error active, Error passive, Bus Off)";
CM_ SG_ 1426 BrakeR_OD_CAN2_DiscardedTxMessag "Number of discarded TX messages on CAN2 because all messageboxes were full";
CM_ SG_ 1426 BrakeR_OD_CAN2_Status "Status of CAN2.";
CM_ SG_ 1426 BrakeR_OD_CAN2_Baudrate "Baudrate of CAN.";
CM_ SG_ 1426 BrakeR_OD_CAN2_autoErrorReset "Automatic reset of errors.";
CM_ SG_ 1426 BrakeR_OD_CAN2_lastErrorCode "Last error code.";
CM_ SG_ 1426 BrakeR_OD_CAN2_RxErrCnt "Receive error count of CAN1.";
CM_ SG_ 1426 BrakeR_OD_CAN2_TxErrCnt "Transmit error count of CAN1.";
CM_ SG_ 1426 BrakeR_OD_CAN1_DelayedTxMessages "Number of delayed TX messages on CAN1 because no messagebox was free.";
CM_ SG_ 1426 BrakeR_OD_CAN1_ErrorStatus "Internal error status (e.g. Error active, Error passive, Bus Off)";
CM_ SG_ 1426 BrakeR_OD_CAN1_DiscardedTxMessag "Number of discarded TX messages on CAN1 because all messageboxes were full";
CM_ SG_ 1426 BrakeR_OD_CAN1_Status "Status of CAN1.";
CM_ SG_ 1426 BrakeR_OD_CAN1_Baudrate "Baudrate of CAN.";
CM_ SG_ 1426 BrakeR_OD_CAN1_autoErrorReset "Automatic reset of errors.";
CM_ SG_ 1426 BrakeR_OD_CAN1_lastErrorCode "Last error code.";
CM_ SG_ 1426 BrakeR_OD_CAN1_RxErrCnt "Receive error count of CAN1.";
CM_ SG_ 1426 BrakeR_OD_CAN1_TxErrCnt "Transmit error count of CAN1.";
CM_ SG_ 1426 BrakeR_OD_BuildTime "Software build time in the format HHMMSS.";
CM_ SG_ 1426 BrakeR_OD_BuildDate "Software build date in the format YYYYMMDD.";
CM_ SG_ 1426 BrakeR_OD_ChipUID2 "Seccond part of unique ID of microcontroller.";
CM_ SG_ 1426 BrakeR_OD_ChipUID1 "First part of unique ID of microcontroller.";
CM_ SG_ 1426 BrakeR_OD_SdcOut "Measurement of Shutdown Circuit Output";
CM_ SG_ 1426 BrakeR_OD_SdcIn "Measurement of Shutdown Circuit Input";
CM_ SG_ 1426 BrakeR_OD_runtime "Runtime of chip in milliseconds.";
CM_ SG_ 1426 BrakeR_OD_InputVoltage "Board supply voltage.";
CM_ SG_ 1426 BrakeR_OD_BoardTemp "Temperature of board";
CM_ SG_ 1426 BrakeR_OD_MemFree "Free memory in bytes.";
CM_ SG_ 1426 BrakeR_OD_CpuUsage "Current CPU usage in %.";
CM_ SG_ 1426 BrakeR_OD_OdEntrySendInterval "Interval for sending all readable OD entries. Sending is disabled if less than 5 ms.";
CM_ SG_ 1426 BrakeR_OD_SendOdOnBootup "Whether to send all OD entries on bootup.";
CM_ SG_ 1426 BrakeR_OD_HeartbeatInterval "Heartbeat Interval in milliseconds.";
CM_ SG_ 1426 BrakeR_OD_DbcVersion "CANzero DBC version.";
CM_ SG_ 1426 BrakeR_OD_StackVersion "CANzero stack version.";
CM_ SG_ 1426 BrakeR_OD_ProtocolVersion "CANzero Protocol Version.";
CM_ SG_ 1426 BrakeR_OD_NodeStatus "State of the node.";
CM_ SG_ 1426 BrakeR_OD_NodeID "CANzero Node-ID.";
CM_ SG_ 1426 BrakeR_SDO_RespCode "Response code of SDO access.";
CM_ SG_ 1426 BrakeR_SDO_ID "Specifies SDO-ID of BrakeR";
CM_ BO_ 1490 "DO NOT CHANGE ANYTHING HERE!
SDO Request Upload to node BrakeR with Node-ID 0x12";
CM_ SG_ 1490 BrakeR_OD_valveUpperTolerance "Tolerance of the lower pressure pneumatic circuit";
CM_ SG_ 1490 BrakeR_OD_commWatchdog "Max. number of ms to receive a new message";
CM_ SG_ 1490 BrakeR_OD_counterLimit "Number of cycles in the loop to measure pressure once";
CM_ SG_ 1490 BrakeR_OD_delay "Delay used in every cycle of the loop.";
CM_ SG_ 1490 BrakeR_OD_tankUpperControlLimit "Maximum pressure of tank in bar.";
CM_ SG_ 1490 BrakeR_OD_tankLowerControlLimit "Minimum pressure of tank in bar.";
CM_ SG_ 1490 BrakeR_OD_CAN2_DelayedTxMessages "Number of delayed TX messages on CAN2 because no messagebox was free.";
CM_ SG_ 1490 BrakeR_OD_CAN2_ErrorStatus "Internal error status (e.g. Error active, Error passive, Bus Off)";
CM_ SG_ 1490 BrakeR_OD_CAN2_DiscardedTxM_0000 "Number of discarded TX messages on CAN2 because all messageboxes were full";
CM_ SG_ 1490 BrakeR_OD_CAN2_Status "Status of CAN2.";
CM_ SG_ 1490 BrakeR_OD_CAN2_Baudrate "Baudrate of CAN.";
CM_ SG_ 1490 BrakeR_OD_CAN2_autoErrorReset "Automatic reset of errors.";
CM_ SG_ 1490 BrakeR_OD_CAN2_lastErrorCode "Last error code.";
CM_ SG_ 1490 BrakeR_OD_CAN2_RxErrCnt "Receive error count of CAN1.";
CM_ SG_ 1490 BrakeR_OD_CAN2_TxErrCnt "Transmit error count of CAN1.";
CM_ SG_ 1490 BrakeR_OD_CAN1_DelayedTxMessages "Number of delayed TX messages on CAN1 because no messagebox was free.";
CM_ SG_ 1490 BrakeR_OD_CAN1_ErrorStatus "Internal error status (e.g. Error active, Error passive, Bus Off)";
CM_ SG_ 1490 BrakeR_OD_CAN1_DiscardedTxM_0000 "Number of discarded TX messages on CAN1 because all messageboxes were full";
CM_ SG_ 1490 BrakeR_OD_CAN1_Status "Status of CAN1.";
CM_ SG_ 1490 BrakeR_OD_CAN1_Baudrate "Baudrate of CAN.";
CM_ SG_ 1490 BrakeR_OD_CAN1_autoErrorReset "Automatic reset of errors.";
CM_ SG_ 1490 BrakeR_OD_CAN1_lastErrorCode "Last error code.";
CM_ SG_ 1490 BrakeR_OD_CAN1_RxErrCnt "Receive error count of CAN1.";
CM_ SG_ 1490 BrakeR_OD_CAN1_TxErrCnt "Transmit error count of CAN1.";
CM_ SG_ 1490 BrakeR_OD_BuildTime "Software build time in the format HHMMSS.";
CM_ SG_ 1490 BrakeR_OD_BuildDate "Software build date in the format YYYYMMDD.";
CM_ SG_ 1490 BrakeR_OD_ChipUID2 "Seccond part of unique ID of microcontroller.";
CM_ SG_ 1490 BrakeR_OD_ChipUID1 "First part of unique ID of microcontroller.";
CM_ SG_ 1490 BrakeR_OD_SdcOut "Measurement of Shutdown Circuit Output";
CM_ SG_ 1490 BrakeR_OD_SdcIn "Measurement of Shutdown Circuit Input";
CM_ SG_ 1490 BrakeR_OD_runtime "Runtime of chip in milliseconds.";
CM_ SG_ 1490 BrakeR_OD_InputVoltage "Board supply voltage.";
CM_ SG_ 1490 BrakeR_OD_BoardTemp "Temperature of board";
CM_ SG_ 1490 BrakeR_OD_MemFree "Free memory in bytes.";
CM_ SG_ 1490 BrakeR_OD_CpuUsage "Current CPU usage in %.";
CM_ SG_ 1490 BrakeR_OD_OdEntrySendInterval "Interval for sending all readable OD entries. Sending is disabled if less than 5 ms.";
CM_ SG_ 1490 BrakeR_OD_SendOdOnBootup "Whether to send all OD entries on bootup.";
CM_ SG_ 1490 BrakeR_OD_HeartbeatInterval "Heartbeat Interval in milliseconds.";
CM_ SG_ 1490 BrakeR_OD_DbcVersion "CANzero DBC version.";
CM_ SG_ 1490 BrakeR_OD_StackVersion "CANzero stack version.";
CM_ SG_ 1490 BrakeR_OD_ProtocolVersion "CANzero Protocol Version.";
CM_ SG_ 1490 BrakeR_OD_NodeStatus "State of the node.";
CM_ SG_ 1490 BrakeR_OD_NodeID "CANzero Node-ID.";
CM_ SG_ 1490 BrakeR_SDO_ID "Specifies SDO-ID of BrakeR";
CM_ BO_ 1554 "DO NOT CHANGE ANYTHING HERE!
SDO Request Download from node BrakeR with Node-ID 0x12";
CM_ SG_ 1554 BrakeR_SDO_ID "Specifies SDO-ID of BrakeR";
CM_ BO_ 1810 "Heartbeat of node BrakeR with Node-ID 0x12";
CM_ SG_ 1810 BrakeR_NodeState "Heartbeat status of node BrakeR";
CM_ BO_ 1874 "Bootloader transmit from node BrakeR with Node-ID 0x12";
CM_ BO_ 1938 "Bootloader receive by node BrakeR with Node-ID 0x12";
CM_ BO_ 154 "Emergency message of node PDU with Node-ID 0x1A";
CM_ SG_ 154 PDU_E4_watchdogStateMachine "The watchdog for the state machine timed out.";
CM_ SG_ 154 PDU_E3_batterTempCritical "Temperature limit of the battery reached.";
CM_ SG_ 154 PDU_E2_batteryOvercurrent "Overcurrent limit of the battery reached.";
CM_ SG_ 154 PDU_E1_batterVoltageCritical "Error when battery voltage is getting critical low. Pod will be shut down";
CM_ SG_ 154 PDU_E0_OtherError "Other error.";
CM_ SG_ 154 PDU_W2_batterTempHigh "Warning when battery temperature is rising high";
CM_ SG_ 154 PDU_W1_batterVoltageLow "Warning when battery voltage is getting low";
CM_ SG_ 154 PDU_W0_OtherWarning "Other warning.";
CM_ BO_ 410 "Transmit PDO 1 of node PDU with Node-ID 0x1A";
CM_ SG_ 410 PDU_TX_PEHWEnabled "PE Hardware Enable status signal of PDU.";
CM_ SG_ 410 PDU_TX_ErrorFlag "Error status of PDU.";
CM_ SG_ 410 PDU_TX_Enabled "Enable status of PDU.";
CM_ BO_ 474 "Control message of the PDU sent by the State Machine.";
CM_ SG_ 474 PDU_RX_PEHWEnable "PE Hardware Enable signal of PDU.";
CM_ SG_ 474 PDU_RX_ErrorReset "Error reset signal for PDU.";
CM_ SG_ 474 PDU_RX_Enable "Enable signal for PDU.";
CM_ BO_ 538 "Transmit PDO 2 of node PDU with Node-ID 0x1A";
CM_ BO_ 602 "Dutycycle for the channels of the PDU that support PWM.";
CM_ BO_ 666 "Transmit PDO 3 of node PDU with Node-ID 0x1A";
CM_ BO_ 730 "Receive PDO 3 of node PDU with Node-ID 0x1A";
CM_ BO_ 794 "Transmit PDO 4 of node PDU with Node-ID 0x1A";
CM_ BO_ 858 "Receive PDO 4 of node PDU with Node-ID 0x1A";
CM_ BO_ 922 "Transmit PDO 5 of node PDU with Node-ID 0x1A";
CM_ BO_ 986 "Transmit PDO 6 of node PDU with Node-ID 0x1A";
CM_ BO_ 1050 "Transmit PDO 7 of node PDU with Node-ID 0x1A";
CM_ BO_ 1114 "Transmit PDO 8 of node PDU with Node-ID 0x1A";
CM_ BO_ 1178 "Transmit PDO 9 of node PDU with Node-ID 0x1A";
CM_ BO_ 1242 "Transmit PDO 10 of node PDU with Node-ID 0x1A";
CM_ BO_ 1306 "Transmit PDO 11 of node PDU with Node-ID 0x1A";
CM_ BO_ 1370 "Transmit PDO 12 of node PDU with Node-ID 0x1A";
CM_ BO_ 1434 "DO NOT CHANGE ANYTHING HERE!
SDO Response of node PDU with Node-ID 0x1A";
CM_ SG_ 1434 PDU_OD_CoolingPumpEnabled "Enable the Cooling Pump.";
CM_ SG_ 1434 PDU_OD_LedCommands "Commands from Telemetry to leds";
CM_ SG_ 1434 PDU_OD_projectXXEnabled "Enable the Project XX leds.";
CM_ SG_ 1434 PDU_OD_watchdogTimeout "Timeout for the state machine watchdog in milliseconds.";
CM_ SG_ 1434 PDU_OD_statusSendInterval "Sending intervall for the status in milliseconds.";
CM_ SG_ 1434 PDU_OD_currentReadInterval "Sampling time in millisecconds for reading the currents.";
CM_ SG_ 1434 PDU_OD_batteryOvercurrent "Overcurrent limit in ampere of the low voltage battery.";
CM_ SG_ 1434 PDU_OD_overTempCritical "Error when battery temperature is getting critical high. Pod will be shut down";
CM_ SG_ 1434 PDU_OD_overTempWarn "Warning when battery temperature is getting high";
CM_ SG_ 1434 PDU_OD_batterVoltageCritical "Error when battery voltage is getting critical low. Pod will be shut down";
CM_ SG_ 1434 PDU_OD_batterVoltageLow "Warning when battery voltage is getting low";
CM_ SG_ 1434 PDU_OD_CAN2_DelayedTxMessages "Number of delayed TX messages on CAN2 because no messagebox was free.";
CM_ SG_ 1434 PDU_OD_CAN2_ErrorStatus "Internal error status (e.g. Error active, Error passive, Bus Off)";
CM_ SG_ 1434 PDU_OD_CAN2_DiscardedTxMessages "Number of discarded TX messages on CAN2 because all messageboxes were full";
CM_ SG_ 1434 PDU_OD_CAN2_Status "Status of CAN2.";
CM_ SG_ 1434 PDU_OD_CAN2_Baudrate "Baudrate of CAN.";
CM_ SG_ 1434 PDU_OD_CAN2_autoErrorReset "Automatic reset of errors.";
CM_ SG_ 1434 PDU_OD_CAN2_lastErrorCode "Last error code.";
CM_ SG_ 1434 PDU_OD_CAN2_RxErrCnt "Receive error count of CAN1.";
CM_ SG_ 1434 PDU_OD_CAN2_TxErrCnt "Transmit error count of CAN1.";
CM_ SG_ 1434 PDU_OD_CAN1_DelayedTxMessages "Number of delayed TX messages on CAN1 because no messagebox was free.";
CM_ SG_ 1434 PDU_OD_CAN1_ErrorStatus "Internal error status (e.g. Error active, Error passive, Bus Off)";
CM_ SG_ 1434 PDU_OD_CAN1_DiscardedTxMessages "Number of discarded TX messages on CAN1 because all messageboxes were full";
CM_ SG_ 1434 PDU_OD_CAN1_Status "Status of CAN1.";
CM_ SG_ 1434 PDU_OD_CAN1_Baudrate "Baudrate of CAN.";
CM_ SG_ 1434 PDU_OD_CAN1_autoErrorReset "Automatic reset of errors.";
CM_ SG_ 1434 PDU_OD_CAN1_lastErrorCode "Last error code.";
CM_ SG_ 1434 PDU_OD_CAN1_RxErrCnt "Receive error count of CAN1.";
CM_ SG_ 1434 PDU_OD_CAN1_TxErrCnt "Transmit error count of CAN1.";
CM_ SG_ 1434 PDU_OD_BuildTime "Software build time in the format HHMMSS.";
CM_ SG_ 1434 PDU_OD_BuildDate "Software build date in the format YYYYMMDD.";
CM_ SG_ 1434 PDU_OD_ChipUID2 "Seccond part of unique ID of microcontroller.";
CM_ SG_ 1434 PDU_OD_ChipUID1 "First part of unique ID of microcontroller.";
CM_ SG_ 1434 PDU_OD_SdcOut "Measurement of Shutdown Circuit Output";
CM_ SG_ 1434 PDU_OD_SdcIn "Measurement of Shutdown Circuit Input";
CM_ SG_ 1434 PDU_OD_runtime "Runtime of chip in milliseconds.";
CM_ SG_ 1434 PDU_OD_InputVoltage "Board supply voltage.";
CM_ SG_ 1434 PDU_OD_BoardTemp "Temperature of board";
CM_ SG_ 1434 PDU_OD_MemFree "Free memory in bytes.";
CM_ SG_ 1434 PDU_OD_CpuUsage "Current CPU usage in %.";
CM_ SG_ 1434 PDU_OD_OdEntrySendInterval "Interval for sending all readable OD entries. Sending is disabled if less than 5 ms.";
CM_ SG_ 1434 PDU_OD_SendOdOnBootup "Whether to send all OD entries on bootup.";
CM_ SG_ 1434 PDU_OD_HeartbeatInterval "Heartbeat Interval in milliseconds.";
CM_ SG_ 1434 PDU_OD_DbcVersion "CANzero DBC version.";
CM_ SG_ 1434 PDU_OD_StackVersion "CANzero stack version.";
CM_ SG_ 1434 PDU_OD_ProtocolVersion "CANzero Protocol Version.";
CM_ SG_ 1434 PDU_OD_NodeStatus "State of the node.";
CM_ SG_ 1434 PDU_OD_NodeID "CANzero Node-ID.";
CM_ SG_ 1434 PDU_SDO_RespCode "Response code of SDO access.";
CM_ SG_ 1434 PDU_SDO_ID "Specifies SDO-ID of PDU";
CM_ BO_ 1498 "DO NOT CHANGE ANYTHING HERE!
SDO Request Upload to node PDU with Node-ID 0x1A";
CM_ SG_ 1498 PDU_OD_CoolingPumpEnabled "Enable the Cooling Pump.";
CM_ SG_ 1498 PDU_OD_LedCommands "Commands from Telemetry to leds";
CM_ SG_ 1498 PDU_OD_projectXXEnabled "Enable the Project XX leds.";
CM_ SG_ 1498 PDU_OD_watchdogTimeout "Timeout for the state machine watchdog in milliseconds.";
CM_ SG_ 1498 PDU_OD_statusSendInterval "Sending intervall for the status in milliseconds.";
CM_ SG_ 1498 PDU_OD_currentReadInterval "Sampling time in millisecconds for reading the currents.";
CM_ SG_ 1498 PDU_OD_batteryOvercurrent "Overcurrent limit in ampere of the low voltage battery.";
CM_ SG_ 1498 PDU_OD_overTempCritical "Error when battery temperature is getting critical high. Pod will be shut down";
CM_ SG_ 1498 PDU_OD_overTempWarn "Warning when battery temperature is getting high";
CM_ SG_ 1498 PDU_OD_batterVoltageCritical "Error when battery voltage is getting critical low. Pod will be shut down";
CM_ SG_ 1498 PDU_OD_batterVoltageLow "Warning when battery voltage is getting low";
CM_ SG_ 1498 PDU_OD_CAN2_DelayedTxMessages "Number of delayed TX messages on CAN2 because no messagebox was free.";
CM_ SG_ 1498 PDU_OD_CAN2_ErrorStatus "Internal error status (e.g. Error active, Error passive, Bus Off)";
CM_ SG_ 1498 PDU_OD_CAN2_DiscardedTxMessages "Number of discarded TX messages on CAN2 because all messageboxes were full";
CM_ SG_ 1498 PDU_OD_CAN2_Status "Status of CAN2.";
CM_ SG_ 1498 PDU_OD_CAN2_Baudrate "Baudrate of CAN.";
CM_ SG_ 1498 PDU_OD_CAN2_autoErrorReset "Automatic reset of errors.";
CM_ SG_ 1498 PDU_OD_CAN2_lastErrorCode "Last error code.";
CM_ SG_ 1498 PDU_OD_CAN2_RxErrCnt "Receive error count of CAN1.";
CM_ SG_ 1498 PDU_OD_CAN2_TxErrCnt "Transmit error count of CAN1.";
CM_ SG_ 1498 PDU_OD_CAN1_DelayedTxMessages "Number of delayed TX messages on CAN1 because no messagebox was free.";
CM_ SG_ 1498 PDU_OD_CAN1_ErrorStatus "Internal error status (e.g. Error active, Error passive, Bus Off)";
CM_ SG_ 1498 PDU_OD_CAN1_DiscardedTxMessages "Number of discarded TX messages on CAN1 because all messageboxes were full";
CM_ SG_ 1498 PDU_OD_CAN1_Status "Status of CAN1.";
CM_ SG_ 1498 PDU_OD_CAN1_Baudrate "Baudrate of CAN.";
CM_ SG_ 1498 PDU_OD_CAN1_autoErrorReset "Automatic reset of errors.";
CM_ SG_ 1498 PDU_OD_CAN1_lastErrorCode "Last error code.";
CM_ SG_ 1498 PDU_OD_CAN1_RxErrCnt "Receive error count of CAN1.";
CM_ SG_ 1498 PDU_OD_CAN1_TxErrCnt "Transmit error count of CAN1.";
CM_ SG_ 1498 PDU_OD_BuildTime "Software build time in the format HHMMSS.";
CM_ SG_ 1498 PDU_OD_BuildDate "Software build date in the format YYYYMMDD.";
CM_ SG_ 1498 PDU_OD_ChipUID2 "Seccond part of unique ID of microcontroller.";
CM_ SG_ 1498 PDU_OD_ChipUID1 "First part of unique ID of microcontroller.";
CM_ SG_ 1498 PDU_OD_SdcOut "Measurement of Shutdown Circuit Output";
CM_ SG_ 1498 PDU_OD_SdcIn "Measurement of Shutdown Circuit Input";
CM_ SG_ 1498 PDU_OD_runtime "Runtime of chip in milliseconds.";
CM_ SG_ 1498 PDU_OD_InputVoltage "Board supply voltage.";
CM_ SG_ 1498 PDU_OD_BoardTemp "Temperature of board";
CM_ SG_ 1498 PDU_OD_MemFree "Free memory in bytes.";
CM_ SG_ 1498 PDU_OD_CpuUsage "Current CPU usage in %.";
CM_ SG_ 1498 PDU_OD_OdEntrySendInterval "Interval for sending all readable OD entries. Sending is disabled if less than 5 ms.";
CM_ SG_ 1498 PDU_OD_SendOdOnBootup "Whether to send all OD entries on bootup.";
CM_ SG_ 1498 PDU_OD_HeartbeatInterval "Heartbeat Interval in milliseconds.";
CM_ SG_ 1498 PDU_OD_DbcVersion "CANzero DBC version.";
CM_ SG_ 1498 PDU_OD_StackVersion "CANzero stack version.";
CM_ SG_ 1498 PDU_OD_ProtocolVersion "CANzero Protocol Version.";
CM_ SG_ 1498 PDU_OD_NodeStatus "State of the node.";
CM_ SG_ 1498 PDU_OD_NodeID "CANzero Node-ID.";
CM_ SG_ 1498 PDU_SDO_ID "Specifies SDO-ID of PDU";
CM_ BO_ 1562 "DO NOT CHANGE ANYTHING HERE!
SDO Request Download from node PDU with Node-ID 0x1A";
CM_ SG_ 1562 PDU_SDO_ID "Specifies SDO-ID of PDU";
CM_ BO_ 1818 "Heartbeat of node PDU with Node-ID 0x1A";
CM_ SG_ 1818 PDU_NodeState "Heartbeat status of node PDU";
CM_ BO_ 1882 "Bootloader transmit from node PDU with Node-ID 0x1A";
CM_ BO_ 1946 "Bootloader receive by node PDU with Node-ID 0x1A";
CM_ BO_ 138 "Emergency message of node HVCU with Node-ID 0xA";
CM_ SG_ 138 HVCU_E19_ChargingModeError "Change to Charging Mode is only allowed in IDLE";
CM_ SG_ 138 HVCU_E18_SDCSwitchError "HVCU SDC switch is off, but SDC is active or not possible to close the Shutdown Circuit";
CM_ SG_ 138 HVCU_E17_ControlMessageTimeout "No control message from State Machine";
CM_ SG_ 138 HVCU_E16_NoEnable "Enable Signal not avaliable";
CM_ SG_ 138 HVCU_E15_SDCOpen "Shutdown Circuit is open";
CM_ SG_ 138 HVCU_E14_HVMPError "Currentflow trough High Voltage Measuring Point";
CM_ SG_ 138 HVCU_E13_BIR4Error "HIGH VOLTAGE! Physical state and electrical control is different";
CM_ SG_ 138 HVCU_E12_BIR3Error "HIGH VOLTAGE! Physical state and electrical control is different";
CM_ SG_ 138 HVCU_E11_BIR2Error "HIGH VOLTAGE! Physical state and electrical control is different";
CM_ SG_ 138 HVCU_E10_BIR1Error "HIGH VOLTAGE! Physical state and electrical control is different";
CM_ SG_ 138 HVCU_E9_HVSLError "High Voltage Active Light is faulty";
CM_ SG_ 138 HVCU_E8_VoltageMeasuring "Invalid Measuring. Check HVD";
CM_ SG_ 138 HVCU_E7_BALError "Battery Active Light is faulty";
CM_ SG_ 138 HVCU_E6_DischargeError "Discharge circuit is active even though it's not supposed to or Discharge Disable Signal is wrong.";
CM_ SG_ 138 HVCU_E5_DischargeTimeout "HIGH VOLTAGE! Discharging takes too long";
CM_ SG_ 138 HVCU_E4_BMSPermissionMissing "No BMS Permission to close the Relays";
CM_ SG_ 138 HVCU_E3_PrechargeError "Check the Fuses and Relays";
CM_ SG_ 138 HVCU_E2_BMSError "BMS Error";
CM_ SG_ 138 HVCU_E1_IMDError "Isolation Resistance too low or other IMD Error";
CM_ SG_ 138 HVCU_E0_OtherError "Other error.";
CM_ SG_ 138 HVCU_W8_ChargingMode "Charging Mode active";
CM_ SG_ 138 HVCU_W7_IsolationResistanceLow "Isolation Resistance under 500 kOhm";
CM_ SG_ 138 HVCU_W6_Bir4On "Battery Relay 4 is closed";
CM_ SG_ 138 HVCU_W5_Bir3On "Battery Relay 3 is closed";
CM_ SG_ 138 HVCU_W4_Bir2On "Battery Relay 2 is closed";
CM_ SG_ 138 HVCU_W3_Bir1On "Battery Relay 1 is closed";
CM_ SG_ 138 HVCU_W2_PreChargeOn "Pre-Charge Relay is cloesd";
CM_ SG_ 138 HVCU_W1_HighVoltage "HIGH VOLTAGE ACTIVE";
CM_ SG_ 138 HVCU_W0_OtherWarning "Other warning.";
CM_ BO_ 394 "Transmit PDO 1 of node HVCU with Node-ID 0xA";
CM_ SG_ 394 HVCU_TX_Enabled "Enable status of HVCU.";
CM_ SG_ 394 HVCU_TX_ErrorFlag "Error status of HVCU.";
CM_ SG_ 394 HVCU_TX_Status "HVCU status signal.";
CM_ SG_ 394 HVCU_TX_InternalStatus "HVCU internal status signal. For Debug.";
CM_ BO_ 458 "Receive PDO 1 of node HVCU with Node-ID 0xA";
CM_ SG_ 458 HVCU_RX_Charging "HVCU Charging signal for HV system.";
CM_ SG_ 458 HVCU_RX_ErrorReset "Error reset signal for HVCU.";
CM_ SG_ 458 HVCU_RX_Activate "HVCU Activate signal for HV system.";
CM_ SG_ 458 HVCU_RX_Enable "Enable signal for HVCU.";
CM_ BO_ 522 "Transmit PDO 2 of node HVCU with Node-ID 0xA";
CM_ BO_ 586 "Receive PDO 2 of node HVCU with Node-ID 0xA";
CM_ BO_ 650 "Transmit PDO 3 of node HVCU with Node-ID 0xA";
CM_ BO_ 714 "Receive PDO 3 of node HVCU with Node-ID 0xA";
CM_ BO_ 778 "Transmit PDO 4 of node HVCU with Node-ID 0xA";
CM_ BO_ 842 "Receive PDO 4 of node HVCU with Node-ID 0xA";
CM_ BO_ 906 "Transmit PDO 5 of node HVCU with Node-ID 0xA";
CM_ BO_ 970 "Transmit PDO 6 of node HVCU with Node-ID 0xA";
CM_ BO_ 1034 "Transmit PDO 7 of node HVCU with Node-ID 0xA";
CM_ BO_ 1098 "Transmit PDO 8 of node HVCU with Node-ID 0xA";
CM_ BO_ 1162 "Transmit PDO 9 of node HVCU with Node-ID 0xA";
CM_ BO_ 1226 "Transmit PDO 10 of node HVCU with Node-ID 0xA";
CM_ BO_ 1290 "Transmit PDO 11 of node HVCU with Node-ID 0xA";
CM_ BO_ 1354 "Transmit PDO 12 of node HVCU with Node-ID 0xA";
CM_ BO_ 1418 "DO NOT CHANGE ANYTHING HERE!
SDO Response of node HVCU with Node-ID 0xA";
CM_ SG_ 1418 HVCU_OD_CAN2_DelayedTxMessages "Number of delayed TX messages on CAN2 because no messagebox was free.";
CM_ SG_ 1418 HVCU_OD_CAN2_ErrorStatus "Internal error status (e.g. Error active, Error passive, Bus Off)";
CM_ SG_ 1418 HVCU_OD_CAN2_DiscardedTxMessages "Number of discarded TX messages on CAN2 because all messageboxes were full";
CM_ SG_ 1418 HVCU_OD_CAN2_Status "Status of CAN2.";
CM_ SG_ 1418 HVCU_OD_CAN2_Baudrate "Baudrate of CAN.";
CM_ SG_ 1418 HVCU_OD_CAN2_autoErrorReset "Automatic reset of errors.";
CM_ SG_ 1418 HVCU_OD_CAN2_lastErrorCode "Last error code.";
CM_ SG_ 1418 HVCU_OD_CAN2_RxErrCnt "Receive error count of CAN1.";
CM_ SG_ 1418 HVCU_OD_CAN2_TxErrCnt "Transmit error count of CAN1.";
CM_ SG_ 1418 HVCU_OD_CAN1_DelayedTxMessages "Number of delayed TX messages on CAN1 because no messagebox was free.";
CM_ SG_ 1418 HVCU_OD_CAN1_ErrorStatus "Internal error status (e.g. Error active, Error passive, Bus Off)";
CM_ SG_ 1418 HVCU_OD_CAN1_DiscardedTxMessages "Number of discarded TX messages on CAN1 because all messageboxes were full";
CM_ SG_ 1418 HVCU_OD_CAN1_Status "Status of CAN1.";
CM_ SG_ 1418 HVCU_OD_CAN1_Baudrate "Baudrate of CAN.";
CM_ SG_ 1418 HVCU_OD_CAN1_autoErrorReset "Automatic reset of errors.";
CM_ SG_ 1418 HVCU_OD_CAN1_lastErrorCode "Last error code.";
CM_ SG_ 1418 HVCU_OD_CAN1_RxErrCnt "Receive error count of CAN1.";
CM_ SG_ 1418 HVCU_OD_CAN1_TxErrCnt "Transmit error count of CAN1.";
CM_ SG_ 1418 HVCU_OD_BuildTime "Software build time in the format HHMMSS.";
CM_ SG_ 1418 HVCU_OD_BuildDate "Software build date in the format YYYYMMDD.";
CM_ SG_ 1418 HVCU_OD_ChipUID2 "Seccond part of unique ID of microcontroller.";
CM_ SG_ 1418 HVCU_OD_ChipUID1 "First part of unique ID of microcontroller.";
CM_ SG_ 1418 HVCU_OD_SdcOut "Measurement of Shutdown Circuit Output";
CM_ SG_ 1418 HVCU_OD_SdcIn "Measurement of Shutdown Circuit Input";
CM_ SG_ 1418 HVCU_OD_runtime "Runtime of chip in milliseconds.";
CM_ SG_ 1418 HVCU_OD_InputVoltage "Board supply voltage.";
CM_ SG_ 1418 HVCU_OD_BoardTemp "Temperature of board";
CM_ SG_ 1418 HVCU_OD_MemFree "Free memory in bytes.";
CM_ SG_ 1418 HVCU_OD_CpuUsage "Current CPU usage in %.";
CM_ SG_ 1418 HVCU_OD_OdEntrySendInterval "Interval for sending all readable OD entries. Sending is disabled if less than 5 ms.";
CM_ SG_ 1418 HVCU_OD_SendOdOnBootup "Whether to send all OD entries on bootup.";
CM_ SG_ 1418 HVCU_OD_HeartbeatInterval "Heartbeat Interval in milliseconds.";
CM_ SG_ 1418 HVCU_OD_DbcVersion "CANzero DBC version.";
CM_ SG_ 1418 HVCU_OD_StackVersion "CANzero stack version.";
CM_ SG_ 1418 HVCU_OD_ProtocolVersion "CANzero Protocol Version.";
CM_ SG_ 1418 HVCU_OD_NodeStatus "State of the node.";
CM_ SG_ 1418 HVCU_OD_NodeID "CANzero Node-ID.";
CM_ SG_ 1418 HVCU_SDO_RespCode "Response code of SDO access.";
CM_ SG_ 1418 HVCU_SDO_ID "Specifies SDO-ID of HVCU";
BA_DEF_ SG_  "GenSigSendType" ENUM  "Cyclic","OnWrite","OnWriteWithRepetition","OnChange","OnChangeWithRepetition","IfActive","IfActiveWithRepetition","NoSigSendType";
BA_DEF_ BO_  "GenMsgSendType" ENUM  "Cyclic","not_used","not_used","not_used","not_used","Cyclic","not_used","IfActive","NoMsgSendType";
BA_DEF_ BO_  "GenMsgCycleTime" INT 2 50000;
BA_DEF_ BO_  "GenMsgDelayTime" INT 1 1000;
BA_DEF_ BO_  "GenMsgNrOfRepetitions" INT 1 999999;
BA_DEF_ SG_  "GenSigStartValue" FLOAT 0 100000000000;
BA_DEF_ SG_  "CANzero_SDO_Group" STRING ;
BA_DEF_ SG_  "CANzero_SDO_AccessIfOperational" ENUM  "No","Yes";
BA_DEF_ SG_  "CANzero_SDO_AccessType" ENUM  "Read Write","Read Only","Write Only";
BA_DEF_ SG_  "CANzero_SDO_Default" FLOAT 0 0;
BA_DEF_ SG_  "SystemSignalLongSymbol" STRING ;
BA_DEF_DEF_  "GenSigSendType" "Cyclic";
BA_DEF_DEF_  "GenMsgSendType" "NoMsgSendType";
BA_DEF_DEF_  "GenMsgCycleTime" 100;
BA_DEF_DEF_  "GenMsgDelayTime" 1;
BA_DEF_DEF_  "GenMsgNrOfRepetitions" 1;
BA_DEF_DEF_  "GenSigStartValue" 0;
BA_DEF_DEF_  "CANzero_SDO_Group" "";
BA_DEF_DEF_  "CANzero_SDO_AccessIfOperational" "No";
BA_DEF_DEF_  "CANzero_SDO_AccessType" "Read Write";
BA_DEF_DEF_  "CANzero_SDO_Default" 0;
BA_DEF_DEF_  "SystemSignalLongSymbol" "";
BA_ "SystemSignalLongSymbol" SG_ 145 BrakeF_E5_retractUnsuccesful_ope "BrakeF_E5_retractUnsuccesful_openSDC";
BA_ "SystemSignalLongSymbol" SG_ 145 BrakeF_E4_retractUnsuccesful_not "BrakeF_E4_retractUnsuccesful_notEnabled";
BA_ "SystemSignalLongSymbol" SG_ 145 BrakeF_E3_retractUnsuccesful_err "BrakeF_E3_retractUnsuccesful_errorFlag";
BA_ "SystemSignalLongSymbol" SG_ 145 BrakeF_W1_highPressureRetracting "BrakeF_W1_highPressureRetractingChamber";
BA_ "SystemSignalLongSymbol" SG_ 145 BrakeF_W0_highPressureActingCham "BrakeF_W0_highPressureActingChamber";
BA_ "GenSigStartValue" SG_ 1041 BrakeF_TX_Pressure_Tank 400;
BA_ "GenSigStartValue" SG_ 1041 BrakeF_TX_Pressure_Retract 400;
BA_ "GenSigStartValue" SG_ 1041 BrakeF_TX_Pressure_Act 400;
BA_ "CANzero_SDO_AccessIfOperational" SG_ 1425 BrakeF_OD_valveUpperTolerance 1;
BA_ "GenSigStartValue" SG_ 1425 BrakeF_OD_valveUpperTolerance 2000.0;
BA_ "CANzero_SDO_Default" SG_ 1425 BrakeF_OD_valveUpperTolerance 10;
BA_ "CANzero_SDO_AccessIfOperational" SG_ 1425 BrakeF_OD_commWatchdog 1;
BA_ "GenSigStartValue" SG_ 1425 BrakeF_OD_commWatchdog 60.0;
BA_ "CANzero_SDO_Default" SG_ 1425 BrakeF_OD_commWatchdog 60;
BA_ "CANzero_SDO_AccessIfOperational" SG_ 1425 BrakeF_OD_counterLimit 1;
BA_ "GenSigStartValue" SG_ 1425 BrakeF_OD_counterLimit 5.0;
BA_ "CANzero_SDO_Default" SG_ 1425 BrakeF_OD_counterLimit 5;
BA_ "CANzero_SDO_AccessIfOperational" SG_ 1425 BrakeF_OD_delay 1;
BA_ "GenSigStartValue" SG_ 1425 BrakeF_OD_delay 10.0;
BA_ "CANzero_SDO_Default" SG_ 1425 BrakeF_OD_delay 5;
BA_ "CANzero_SDO_AccessIfOperational" SG_ 1425 BrakeF_OD_tankUpperControlLimit 1;
BA_ "GenSigStartValue" SG_ 1425 BrakeF_OD_tankUpperControlLimit 3800.0;
BA_ "CANzero_SDO_Default" SG_ 1425 BrakeF_OD_tankUpperControlLimit 19;
BA_ "CANzero_SDO_AccessIfOperational" SG_ 1425 BrakeF_OD_tankLowerControlLimit 1;
BA_ "GenSigStartValue" SG_ 1425 BrakeF_OD_tankLowerControlLimit 1400.0;
BA_ "CANzero_SDO_Default" SG_ 1425 BrakeF_OD_tankLowerControlLimit 7;
BA_ "CANzero_SDO_Group" SG_ 1425 BrakeF_OD_CAN2_DelayedTxMessages "CAN";
BA_ "CANzero_SDO_AccessType" SG_ 1425 BrakeF_OD_CAN2_DelayedTxMessages 1;
BA_ "CANzero_SDO_AccessIfOperational" SG_ 1425 BrakeF_OD_CAN2_DelayedTxMessages 1;
BA_ "CANzero_SDO_Group" SG_ 1425 BrakeF_OD_CAN2_ErrorStatus "CAN";
BA_ "CANzero_SDO_AccessType" SG_ 1425 BrakeF_OD_CAN2_ErrorStatus 1;
BA_ "CANzero_SDO_AccessIfOperational" SG_ 1425 BrakeF_OD_CAN2_ErrorStatus 1;
BA_ "CANzero_SDO_Group" SG_ 1425 BrakeF_OD_CAN2_DiscardedTxMessag "CAN";
BA_ "CANzero_SDO_AccessType" SG_ 1425 BrakeF_OD_CAN2_DiscardedTxMessag 1;
BA_ "CANzero_SDO_AccessIfOperational" SG_ 1425 BrakeF_OD_CAN2_DiscardedTxMessag 1;
BA_ "SystemSignalLongSymbol" SG_ 1425 BrakeF_OD_CAN2_DiscardedTxMessag "BrakeF_OD_CAN2_DiscardedTxMessages";
BA_ "CANzero_SDO_Group" SG_ 1425 BrakeF_OD_CAN2_Status "CAN";
BA_ "CANzero_SDO_AccessType" SG_ 1425 BrakeF_OD_CAN2_Status 1;
BA_ "CANzero_SDO_AccessIfOperational" SG_ 1425 BrakeF_OD_CAN2_Status 1;
BA_ "CANzero_SDO_Group" SG_ 1425 BrakeF_OD_CAN2_Baudrate "CAN";
BA_ "CANzero_SDO_AccessIfOperational" SG_ 1425 BrakeF_OD_CAN2_Baudrate 1;
BA_ "GenSigStartValue" SG_ 1425 BrakeF_OD_CAN2_Baudrate 1000.0;
BA_ "CANzero_SDO_Default" SG_ 1425 BrakeF_OD_CAN2_Baudrate 1000;
BA_ "CANzero_SDO_Group" SG_ 1425 BrakeF_OD_CAN2_autoErrorReset "CAN";
BA_ "CANzero_SDO_AccessIfOperational" SG_ 1425 BrakeF_OD_CAN2_autoErrorReset 1;
BA_ "GenSigStartValue" SG_ 1425 BrakeF_OD_CAN2_autoErrorReset 1.0;
BA_ "CANzero_SDO_Default" SG_ 1425 BrakeF_OD_CAN2_autoErrorReset 1;
BA_ "CANzero_SDO_Group" SG_ 1425 BrakeF_OD_CAN2_lastErrorCode "CAN";
BA_ "CANzero_SDO_AccessType" SG_ 1425 BrakeF_OD_CAN2_lastErrorCode 1;
BA_ "CANzero_SDO_AccessIfOperational" SG_ 1425 BrakeF_OD_CAN2_lastErrorCode 1;
BA_ "CANzero_SDO_Group" SG_ 1425 BrakeF_OD_CAN2_RxErrCnt "CAN";
BA_ "CANzero_SDO_AccessType" SG_ 1425 BrakeF_OD_CAN2_RxErrCnt 1;
BA_ "CANzero_SDO_AccessIfOperational" SG_ 1425 BrakeF_OD_CAN2_RxErrCnt 1;
BA_ "CANzero_SDO_Group" SG_ 1425 BrakeF_OD_CAN2_TxErrCnt "CAN";
BA_ "CANzero_SDO_AccessType" SG_ 1425 BrakeF_OD_CAN2_TxErrCnt 1;
BA_ "CANzero_SDO_AccessIfOperational" SG_ 1425 BrakeF_OD_CAN2_TxErrCnt 1;
BA_ "CANzero_SDO_Group" SG_ 1425 BrakeF_OD_CAN1_DelayedTxMessages "CAN";
BA_ "CANzero_SDO_AccessType" SG_ 1425 BrakeF_OD_CAN1_DelayedTxMessages 1;
BA_ "CANzero_SDO_AccessIfOperational" SG_ 1425 BrakeF_OD_CAN1_DelayedTxMessages 1;
BA_ "CANzero_SDO_Group" SG_ 1425 BrakeF_OD_CAN1_ErrorStatus "CAN";
BA_ "CANzero_SDO_AccessType" SG_ 1425 BrakeF_OD_CAN1_ErrorStatus 1;
BA_ "CANzero_SDO_AccessIfOperational" SG_ 1425 BrakeF_OD_CAN1_ErrorStatus 1;
BA_ "CANzero_SDO_Group" SG_ 1425 BrakeF_OD_CAN1_DiscardedTxMessag "CAN";
BA_ "CANzero_SDO_AccessType" SG_ 1425 BrakeF_OD_CAN1_DiscardedTxMessag 1;
BA_ "CANzero_SDO_AccessIfOperational" SG_ 1425 BrakeF_OD_CAN1_DiscardedTxMessag 1;
BA_ "SystemSignalLongSymbol" SG_ 1425 BrakeF_OD_CAN1_DiscardedTxMessag "BrakeF_OD_CAN1_DiscardedTxMessages";
BA_ "CANzero_SDO_Group" SG_ 1425 BrakeF_OD_CAN1_Status "CAN";
BA_ "CANzero_SDO_AccessType" SG_ 1425 BrakeF_OD_CAN1_Status 1;
BA_ "CANzero_SDO_AccessIfOperational" SG_ 1425 BrakeF_OD_CAN1_Status 1;
BA_ "CANzero_SDO_Group" SG_ 1425 BrakeF_OD_CAN1_Baudrate "CAN";
BA_ "CANzero_SDO_AccessIfOperational" SG_ 1425 BrakeF_OD_CAN1_Baudrate 1;
BA_ "GenSigStartValue" SG_ 1425 BrakeF_OD_CAN1_Baudrate 1000.0;
BA_ "CANzero_SDO_Default" SG_ 1425 BrakeF_OD_CAN1_Baudrate 1000;
BA_ "CANzero_SDO_Group" SG_ 1425 BrakeF_OD_CAN1_autoErrorReset "CAN";
BA_ "CANzero_SDO_AccessIfOperational" SG_ 1425 BrakeF_OD_CAN1_autoErrorReset 1;
BA_ "GenSigStartValue" SG_ 1425 BrakeF_OD_CAN1_autoErrorReset 1.0;
BA_ "CANzero_SDO_Default" SG_ 1425 BrakeF_OD_CAN1_autoErrorReset 1;
BA_ "CANzero_SDO_Group" SG_ 1425 BrakeF_OD_CAN1_lastErrorCode "CAN";
BA_ "CANzero_SDO_AccessType" SG_ 1425 BrakeF_OD_CAN1_lastErrorCode 1;
BA_ "CANzero_SDO_AccessIfOperational" SG_ 1425 BrakeF_OD_CAN1_lastErrorCode 1;
BA_ "CANzero_SDO_Group" SG_ 1425 BrakeF_OD_CAN1_RxErrCnt "CAN";
BA_ "CANzero_SDO_AccessType" SG_ 1425 BrakeF_OD_CAN1_RxErrCnt 1;
BA_ "CANzero_SDO_AccessIfOperational" SG_ 1425 BrakeF_OD_CAN1_RxErrCnt 1;
BA_ "CANzero_SDO_Group" SG_ 1425 BrakeF_OD_CAN1_TxErrCnt "CAN";
BA_ "CANzero_SDO_AccessType" SG_ 1425 BrakeF_OD_CAN1_TxErrCnt 1;
BA_ "CANzero_SDO_AccessIfOperational" SG_ 1425 BrakeF_OD_CAN1_TxErrCnt 1;
BA_ "CANzero_SDO_AccessType" SG_ 1425 BrakeF_OD_BuildTime 1;
BA_ "CANzero_SDO_AccessIfOperational" SG_ 1425 BrakeF_OD_BuildTime 1;
BA_ "CANzero_SDO_AccessType" SG_ 1425 BrakeF_OD_BuildDate 1;
BA_ "CANzero_SDO_AccessIfOperational" SG_ 1425 BrakeF_OD_BuildDate 1;
BA_ "CANzero_SDO_AccessType" SG_ 1425 BrakeF_OD_ChipUID2 1;
BA_ "CANzero_SDO_AccessIfOperational" SG_ 1425 BrakeF_OD_ChipUID2 1;
BA_ "CANzero_SDO_AccessType" SG_ 1425 BrakeF_OD_ChipUID1 1;
BA_ "CANzero_SDO_AccessIfOperational" SG_ 1425 BrakeF_OD_ChipUID1 1;
BA_ "CANzero_SDO_AccessType" SG_ 1425 BrakeF_OD_SdcOut 1;
BA_ "CANzero_SDO_AccessIfOperational" SG_ 1425 BrakeF_OD_SdcOut 1;
BA_ "CANzero_SDO_AccessType" SG_ 1425 BrakeF_OD_SdcIn 1;
BA_ "CANzero_SDO_AccessIfOperational" SG_ 1425 BrakeF_OD_SdcIn 1;
BA_ "CANzero_SDO_AccessType" SG_ 1425 BrakeF_OD_runtime 1;
BA_ "CANzero_SDO_AccessIfOperational" SG_ 1425 BrakeF_OD_runtime 1;
BA_ "CANzero_SDO_AccessType" SG_ 1425 BrakeF_OD_InputVoltage 1;
BA_ "CANzero_SDO_AccessIfOperational" SG_ 1425 BrakeF_OD_InputVoltage 1;
BA_ "CANzero_SDO_AccessType" SG_ 1425 BrakeF_OD_BoardTemp 1;
BA_ "CANzero_SDO_AccessIfOperational" SG_ 1425 BrakeF_OD_BoardTemp 1;
BA_ "GenSigStartValue" SG_ 1425 BrakeF_OD_BoardTemp 3000.0;
BA_ "CANzero_SDO_AccessType" SG_ 1425 BrakeF_OD_MemFree 1;
BA_ "CANzero_SDO_AccessIfOperational" SG_ 1425 BrakeF_OD_MemFree 1;
BA_ "CANzero_SDO_AccessType" SG_ 1425 BrakeF_OD_CpuUsage 1;
BA_ "CANzero_SDO_AccessIfOperational" SG_ 1425 BrakeF_OD_CpuUsage 1;
BA_ "CANzero_SDO_AccessIfOperational" SG_ 1425 BrakeF_OD_OdEntrySendInterval 1;
BA_ "GenSigStartValue" SG_ 1425 BrakeF_OD_OdEntrySendInterval 50.0;
BA_ "CANzero_SDO_Default" SG_ 1425 BrakeF_OD_OdEntrySendInterval 50;
BA_ "CANzero_SDO_AccessIfOperational" SG_ 1425 BrakeF_OD_SendOdOnBootup 1;
BA_ "CANzero_SDO_AccessIfOperational" SG_ 1425 BrakeF_OD_HeartbeatInterval 1;
BA_ "GenSigStartValue" SG_ 1425 BrakeF_OD_HeartbeatInterval 100.0;
BA_ "CANzero_SDO_Default" SG_ 1425 BrakeF_OD_HeartbeatInterval 100;
BA_ "CANzero_SDO_AccessType" SG_ 1425 BrakeF_OD_DbcVersion 1;
BA_ "CANzero_SDO_AccessIfOperational" SG_ 1425 BrakeF_OD_DbcVersion 1;
BA_ "CANzero_SDO_AccessType" SG_ 1425 BrakeF_OD_StackVersion 1;
BA_ "CANzero_SDO_AccessIfOperational" SG_ 1425 BrakeF_OD_StackVersion 1;
BA_ "CANzero_SDO_AccessType" SG_ 1425 BrakeF_OD_ProtocolVersion 1;
BA_ "CANzero_SDO_AccessIfOperational" SG_ 1425 BrakeF_OD_ProtocolVersion 1;
BA_ "GenSigStartValue" SG_ 1425 BrakeF_OD_ProtocolVersion 1.0;
BA_ "CANzero_SDO_Default" SG_ 1425 BrakeF_OD_ProtocolVersion 1;
BA_ "CANzero_SDO_AccessType" SG_ 1425 BrakeF_OD_NodeStatus 1;
BA_ "CANzero_SDO_AccessIfOperational" SG_ 1425 BrakeF_OD_NodeStatus 1;
BA_ "CANzero_SDO_AccessType" SG_ 1425 BrakeF_OD_NodeID 1;
BA_ "CANzero_SDO_AccessIfOperational" SG_ 1425 BrakeF_OD_NodeID 1;
BA_ "CANzero_SDO_AccessIfOperational" SG_ 1489 BrakeF_OD_valveUpperTolerance 1;
BA_ "GenSigStartValue" SG_ 1489 BrakeF_OD_valveUpperTolerance 2000.0;
BA_ "CANzero_SDO_Default" SG_ 1489 BrakeF_OD_valveUpperTolerance 10;
BA_ "CANzero_SDO_AccessIfOperational" SG_ 1489 BrakeF_OD_commWatchdog 1;
BA_ "GenSigStartValue" SG_ 1489 BrakeF_OD_commWatchdog 60.0;
BA_ "CANzero_SDO_Default" SG_ 1489 BrakeF_OD_commWatchdog 60;
BA_ "CANzero_SDO_AccessIfOperational" SG_ 1489 BrakeF_OD_counterLimit 1;
BA_ "GenSigStartValue" SG_ 1489 BrakeF_OD_counterLimit 5.0;
BA_ "CANzero_SDO_Default" SG_ 1489 BrakeF_OD_counterLimit 5;
BA_ "CANzero_SDO_AccessIfOperational" SG_ 1489 BrakeF_OD_delay 1;
BA_ "GenSigStartValue" SG_ 1489 BrakeF_OD_delay 10.0;
BA_ "CANzero_SDO_Default" SG_ 1489 BrakeF_OD_delay 5;
BA_ "CANzero_SDO_AccessIfOperational" SG_ 1489 BrakeF_OD_tankUpperControlLimit 1;
BA_ "GenSigStartValue" SG_ 1489 BrakeF_OD_tankUpperControlLimit 3800.0;
BA_ "CANzero_SDO_Default" SG_ 1489 BrakeF_OD_tankUpperControlLimit 19;
BA_ "CANzero_SDO_AccessIfOperational" SG_ 1489 BrakeF_OD_tankLowerControlLimit 1;
BA_ "GenSigStartValue" SG_ 1489 BrakeF_OD_tankLowerControlLimit 1400.0;
BA_ "CANzero_SDO_Default" SG_ 1489 BrakeF_OD_tankLowerControlLimit 7;
BA_ "CANzero_SDO_Group" SG_ 1489 BrakeF_OD_CAN2_DelayedTxMessages "CAN";
BA_ "CANzero_SDO_AccessType" SG_ 1489 BrakeF_OD_CAN2_DelayedTxMessages 1;
BA_ "CANzero_SDO_AccessIfOperational" SG_ 1489 BrakeF_OD_CAN2_DelayedTxMessages 1;
BA_ "CANzero_SDO_Group" SG_ 1489 BrakeF_OD_CAN2_ErrorStatus "CAN";
BA_ "CANzero_SDO_AccessType" SG_ 1489 BrakeF_OD_CAN2_ErrorStatus 1;
BA_ "CANzero_SDO_AccessIfOperational" SG_ 1489 BrakeF_OD_CAN2_ErrorStatus 1;
BA_ "CANzero_SDO_Group" SG_ 1489 BrakeF_OD_CAN2_DiscardedTxM_0000 "CAN";
BA_ "CANzero_SDO_AccessType" SG_ 1489 BrakeF_OD_CAN2_DiscardedTxM_0000 1;
BA_ "CANzero_SDO_AccessIfOperational" SG_ 1489 BrakeF_OD_CAN2_DiscardedTxM_0000 1;
BA_ "SystemSignalLongSymbol" SG_ 1489 BrakeF_OD_CAN2_DiscardedTxM_0000 "BrakeF_OD_CAN2_DiscardedTxMessages";
BA_ "CANzero_SDO_Group" SG_ 1489 BrakeF_OD_CAN2_Status "CAN";
BA_ "CANzero_SDO_AccessType" SG_ 1489 BrakeF_OD_CAN2_Status 1;
BA_ "CANzero_SDO_AccessIfOperational" SG_ 1489 BrakeF_OD_CAN2_Status 1;
BA_ "CANzero_SDO_Group" SG_ 1489 BrakeF_OD_CAN2_Baudrate "CAN";
BA_ "CANzero_SDO_AccessIfOperational" SG_ 1489 BrakeF_OD_CAN2_Baudrate 1;
BA_ "GenSigStartValue" SG_ 1489 BrakeF_OD_CAN2_Baudrate 1000.0;
BA_ "CANzero_SDO_Default" SG_ 1489 BrakeF_OD_CAN2_Baudrate 1000;
BA_ "CANzero_SDO_Group" SG_ 1489 BrakeF_OD_CAN2_autoErrorReset "CAN";
BA_ "CANzero_SDO_AccessIfOperational" SG_ 1489 BrakeF_OD_CAN2_autoErrorReset 1;
BA_ "GenSigStartValue" SG_ 1489 BrakeF_OD_CAN2_autoErrorReset 1.0;
BA_ "CANzero_SDO_Default" SG_ 1489 BrakeF_OD_CAN2_autoErrorReset 1;
BA_ "CANzero_SDO_Group" SG_ 1489 BrakeF_OD_CAN2_lastErrorCode "CAN";
BA_ "CANzero_SDO_AccessType" SG_ 1489 BrakeF_OD_CAN2_lastErrorCode 1;
BA_ "CANzero_SDO_AccessIfOperational" SG_ 1489 BrakeF_OD_CAN2_lastErrorCode 1;
BA_ "CANzero_SDO_Group" SG_ 1489 BrakeF_OD_CAN2_RxErrCnt "CAN";
BA_ "CANzero_SDO_AccessType" SG_ 1489 BrakeF_OD_CAN2_RxErrCnt 1;
BA_ "CANzero_SDO_AccessIfOperational" SG_ 1489 BrakeF_OD_CAN2_RxErrCnt 1;
BA_ "CANzero_SDO_Group" SG_ 1489 BrakeF_OD_CAN2_TxErrCnt "CAN";
BA_ "CANzero_SDO_AccessType" SG_ 1489 BrakeF_OD_CAN2_TxErrCnt 1;
BA_ "CANzero_SDO_AccessIfOperational" SG_ 1489 BrakeF_OD_CAN2_TxErrCnt 1;
BA_ "CANzero_SDO_Group" SG_ 1489 BrakeF_OD_CAN1_DelayedTxMessages "CAN";
BA_ "CANzero_SDO_AccessType" SG_ 1489 BrakeF_OD_CAN1_DelayedTxMessages 1;
BA_ "CANzero_SDO_AccessIfOperational" SG_ 1489 BrakeF_OD_CAN1_DelayedTxMessages 1;
BA_ "CANzero_SDO_Group" SG_ 1489 BrakeF_OD_CAN1_ErrorStatus "CAN";
BA_ "CANzero_SDO_AccessType" SG_ 1489 BrakeF_OD_CAN1_ErrorStatus 1;
BA_ "CANzero_SDO_AccessIfOperational" SG_ 1489 BrakeF_OD_CAN1_ErrorStatus 1;
BA_ "CANzero_SDO_Group" SG_ 1489 BrakeF_OD_CAN1_DiscardedTxM_0000 "CAN";
BA_ "CANzero_SDO_AccessType" SG_ 1489 BrakeF_OD_CAN1_DiscardedTxM_0000 1;
BA_ "CANzero_SDO_AccessIfOperational" SG_ 1489 BrakeF_OD_CAN1_DiscardedTxM_0000 1;
BA_ "SystemSignalLongSymbol" SG_ 1489 BrakeF_OD_CAN1_DiscardedTxM_0000 "BrakeF_OD_CAN1_DiscardedTxMessages";
BA_ "CANzero_SDO_Group" SG_ 1489 BrakeF_OD_CAN1_Status "CAN";
BA_ "CANzero_SDO_AccessType" SG_ 1489 BrakeF_OD_CAN1_Status 1;
BA_ "CANzero_SDO_AccessIfOperational" SG_ 1489 BrakeF_OD_CAN1_Status 1;
BA_ "CANzero_SDO_Group" SG_ 1489 BrakeF_OD_CAN1_Baudrate "CAN";
BA_ "CANzero_SDO_AccessIfOperational" SG_ 1489 BrakeF_OD_CAN1_Baudrate 1;
BA_ "GenSigStartValue" SG_ 1489 BrakeF_OD_CAN1_Baudrate 1000.0;
BA_ "CANzero_SDO_Default" SG_ 1489 BrakeF_OD_CAN1_Baudrate 1000;
BA_ "CANzero_SDO_Group" SG_ 1489 BrakeF_OD_CAN1_autoErrorReset "CAN";
BA_ "CANzero_SDO_AccessIfOperational" SG_ 1489 BrakeF_OD_CAN1_autoErrorReset 1;
BA_ "GenSigStartValue" SG_ 1489 BrakeF_OD_CAN1_autoErrorReset 1.0;
BA_ "CANzero_SDO_Default" SG_ 1489 BrakeF_OD_CAN1_autoErrorReset 1;
BA_ "CANzero_SDO_Group" SG_ 1489 BrakeF_OD_CAN1_lastErrorCode "CAN";
BA_ "CANzero_SDO_AccessType" SG_ 1489 BrakeF_OD_CAN1_lastErrorCode 1;
BA_ "CANzero_SDO_AccessIfOperational" SG_ 1489 BrakeF_OD_CAN1_lastErrorCode 1;
BA_ "CANzero_SDO_Group" SG_ 1489 BrakeF_OD_CAN1_RxErrCnt "CAN";
BA_ "CANzero_SDO_AccessType" SG_ 1489 BrakeF_OD_CAN1_RxErrCnt 1;
BA_ "CANzero_SDO_AccessIfOperational" SG_ 1489 BrakeF_OD_CAN1_RxErrCnt 1;
BA_ "CANzero_SDO_Group" SG_ 1489 BrakeF_OD_CAN1_TxErrCnt "CAN";
BA_ "CANzero_SDO_AccessType" SG_ 1489 BrakeF_OD_CAN1_TxErrCnt 1;
BA_ "CANzero_SDO_AccessIfOperational" SG_ 1489 BrakeF_OD_CAN1_TxErrCnt 1;
BA_ "CANzero_SDO_AccessType" SG_ 1489 BrakeF_OD_BuildTime 1;
BA_ "CANzero_SDO_AccessIfOperational" SG_ 1489 BrakeF_OD_BuildTime 1;
BA_ "CANzero_SDO_AccessType" SG_ 1489 BrakeF_OD_BuildDate 1;
BA_ "CANzero_SDO_AccessIfOperational" SG_ 1489 BrakeF_OD_BuildDate 1;
BA_ "CANzero_SDO_AccessType" SG_ 1489 BrakeF_OD_ChipUID2 1;
BA_ "CANzero_SDO_AccessIfOperational" SG_ 1489 BrakeF_OD_ChipUID2 1;
BA_ "CANzero_SDO_AccessType" SG_ 1489 BrakeF_OD_ChipUID1 1;
BA_ "CANzero_SDO_AccessIfOperational" SG_ 1489 BrakeF_OD_ChipUID1 1;
BA_ "CANzero_SDO_AccessType" SG_ 1489 BrakeF_OD_SdcOut 1;
BA_ "CANzero_SDO_AccessIfOperational" SG_ 1489 BrakeF_OD_SdcOut 1;
BA_ "CANzero_SDO_AccessType" SG_ 1489 BrakeF_OD_SdcIn 1;
BA_ "CANzero_SDO_AccessIfOperational" SG_ 1489 BrakeF_OD_SdcIn 1;
BA_ "CANzero_SDO_AccessType" SG_ 1489 BrakeF_OD_runtime 1;
BA_ "CANzero_SDO_AccessIfOperational" SG_ 1489 BrakeF_OD_runtime 1;
BA_ "CANzero_SDO_AccessType" SG_ 1489 BrakeF_OD_InputVoltage 1;
BA_ "CANzero_SDO_AccessIfOperational" SG_ 1489 BrakeF_OD_InputVoltage 1;
BA_ "CANzero_SDO_AccessType" SG_ 1489 BrakeF_OD_BoardTemp 1;
BA_ "CANzero_SDO_AccessIfOperational" SG_ 1489 BrakeF_OD_BoardTemp 1;
BA_ "GenSigStartValue" SG_ 1489 BrakeF_OD_BoardTemp 3000.0;
BA_ "CANzero_SDO_AccessType" SG_ 1489 BrakeF_OD_MemFree 1;
BA_ "CANzero_SDO_AccessIfOperational" SG_ 1489 BrakeF_OD_MemFree 1;
BA_ "CANzero_SDO_AccessType" SG_ 1489 BrakeF_OD_CpuUsage 1;
BA_ "CANzero_SDO_AccessIfOperational" SG_ 1489 BrakeF_OD_CpuUsage 1;
BA_ "CANzero_SDO_AccessIfOperational" SG_ 1489 BrakeF_OD_OdEntrySendInterval 1;
BA_ "GenSigStartValue" SG_ 1489 BrakeF_OD_OdEntrySendInterval 50.0;
BA_ "CANzero_SDO_Default" SG_ 1489 BrakeF_OD_OdEntrySendInterval 50;
BA_ "CANzero_SDO_AccessIfOperational" SG_ 1489 BrakeF_OD_SendOdOnBootup 1;
BA_ "CANzero_SDO_AccessIfOperational" SG_ 1489 BrakeF_OD_HeartbeatInterval 1;
BA_ "GenSigStartValue" SG_ 1489 BrakeF_OD_HeartbeatInterval 100.0;
BA_ "CANzero_SDO_Default" SG_ 1489 BrakeF_OD_HeartbeatInterval 100;
BA_ "CANzero_SDO_AccessType" SG_ 1489 BrakeF_OD_DbcVersion 1;
BA_ "CANzero_SDO_AccessIfOperational" SG_ 1489 BrakeF_OD_DbcVersion 1;
BA_ "CANzero_SDO_AccessType" SG_ 1489 BrakeF_OD_StackVersion 1;
BA_ "CANzero_SDO_AccessIfOperational" SG_ 1489 BrakeF_OD_StackVersion 1;
BA_ "CANzero_SDO_AccessType" SG_ 1489 BrakeF_OD_ProtocolVersion 1;
BA_ "CANzero_SDO_AccessIfOperational" SG_ 1489 BrakeF_OD_ProtocolVersion 1;
BA_ "GenSigStartValue" SG_ 1489 BrakeF_OD_ProtocolVersion 1.0;
BA_ "CANzero_SDO_Default" SG_ 1489 BrakeF_OD_ProtocolVersion 1;
BA_ "CANzero_SDO_AccessType" SG_ 1489 BrakeF_OD_NodeStatus 1;
BA_ "CANzero_SDO_AccessIfOperational" SG_ 1489 BrakeF_OD_NodeStatus 1;
BA_ "CANzero_SDO_AccessType" SG_ 1489 BrakeF_OD_NodeID 1;
BA_ "CANzero_SDO_AccessIfOperational" SG_ 1489 BrakeF_OD_NodeID 1;
BA_ "SystemSignalLongSymbol" SG_ 146 BrakeR_E5_retractUnsuccesful_ope "BrakeR_E5_retractUnsuccesful_openSDC";
BA_ "SystemSignalLongSymbol" SG_ 146 BrakeR_E4_retractUnsuccesful_not "BrakeR_E4_retractUnsuccesful_notEnabled";
BA_ "SystemSignalLongSymbol" SG_ 146 BrakeR_E3_retractUnsuccesful_err "BrakeR_E3_retractUnsuccesful_errorFlag";
BA_ "SystemSignalLongSymbol" SG_ 146 BrakeR_W1_highPressureRetracting "BrakeR_W1_highPressureRetractingChamber";
BA_ "SystemSignalLongSymbol" SG_ 146 BrakeR_W0_highPressureActingCham "BrakeR_W0_highPressureActingChamber";
BA_ "GenSigStartValue" SG_ 1106 BrakeR_TX_Pressure_Tank 400;
BA_ "GenSigStartValue" SG_ 1106 BrakeR_TX_Pressure_Retract 400;
BA_ "GenSigStartValue" SG_ 1106 BrakeR_TX_Pressure_Act 400;
BA_ "CANzero_SDO_AccessIfOperational" SG_ 1426 BrakeR_OD_valveUpperTolerance 1;
BA_ "GenSigStartValue" SG_ 1426 BrakeR_OD_valveUpperTolerance 2000.0;
BA_ "CANzero_SDO_Default" SG_ 1426 BrakeR_OD_valveUpperTolerance 10;
BA_ "CANzero_SDO_AccessIfOperational" SG_ 1426 BrakeR_OD_commWatchdog 1;
BA_ "GenSigStartValue" SG_ 1426 BrakeR_OD_commWatchdog 60.0;
BA_ "CANzero_SDO_Default" SG_ 1426 BrakeR_OD_commWatchdog 60;
BA_ "CANzero_SDO_AccessIfOperational" SG_ 1426 BrakeR_OD_counterLimit 1;
BA_ "GenSigStartValue" SG_ 1426 BrakeR_OD_counterLimit 5.0;
BA_ "CANzero_SDO_Default" SG_ 1426 BrakeR_OD_counterLimit 5;
BA_ "CANzero_SDO_AccessIfOperational" SG_ 1426 BrakeR_OD_delay 1;
BA_ "GenSigStartValue" SG_ 1426 BrakeR_OD_delay 10.0;
BA_ "CANzero_SDO_Default" SG_ 1426 BrakeR_OD_delay 5;
BA_ "CANzero_SDO_AccessIfOperational" SG_ 1426 BrakeR_OD_tankUpperControlLimit 1;
BA_ "GenSigStartValue" SG_ 1426 BrakeR_OD_tankUpperControlLimit 3800.0;
BA_ "CANzero_SDO_Default" SG_ 1426 BrakeR_OD_tankUpperControlLimit 19;
BA_ "CANzero_SDO_AccessIfOperational" SG_ 1426 BrakeR_OD_tankLowerControlLimit 1;
BA_ "GenSigStartValue" SG_ 1426 BrakeR_OD_tankLowerControlLimit 1400.0;
BA_ "CANzero_SDO_Default" SG_ 1426 BrakeR_OD_tankLowerControlLimit 7;
BA_ "CANzero_SDO_Group" SG_ 1426 BrakeR_OD_CAN2_DelayedTxMessages "CAN";
BA_ "CANzero_SDO_AccessType" SG_ 1426 BrakeR_OD_CAN2_DelayedTxMessages 1;
BA_ "CANzero_SDO_AccessIfOperational" SG_ 1426 BrakeR_OD_CAN2_DelayedTxMessages 1;
BA_ "CANzero_SDO_Group" SG_ 1426 BrakeR_OD_CAN2_ErrorStatus "CAN";
BA_ "CANzero_SDO_AccessType" SG_ 1426 BrakeR_OD_CAN2_ErrorStatus 1;
BA_ "CANzero_SDO_AccessIfOperational" SG_ 1426 BrakeR_OD_CAN2_ErrorStatus 1;
BA_ "CANzero_SDO_Group" SG_ 1426 BrakeR_OD_CAN2_DiscardedTxMessag "CAN";
BA_ "CANzero_SDO_AccessType" SG_ 1426 BrakeR_OD_CAN2_DiscardedTxMessag 1;
BA_ "CANzero_SDO_AccessIfOperational" SG_ 1426 BrakeR_OD_CAN2_DiscardedTxMessag 1;
BA_ "SystemSignalLongSymbol" SG_ 1426 BrakeR_OD_CAN2_DiscardedTxMessag "BrakeR_OD_CAN2_DiscardedTxMessages";
BA_ "CANzero_SDO_Group" SG_ 1426 BrakeR_OD_CAN2_Status "CAN";
BA_ "CANzero_SDO_AccessType" SG_ 1426 BrakeR_OD_CAN2_Status 1;
BA_ "CANzero_SDO_AccessIfOperational" SG_ 1426 BrakeR_OD_CAN2_Status 1;
BA_ "CANzero_SDO_Group" SG_ 1426 BrakeR_OD_CAN2_Baudrate "CAN";
BA_ "CANzero_SDO_AccessIfOperational" SG_ 1426 BrakeR_OD_CAN2_Baudrate 1;
BA_ "GenSigStartValue" SG_ 1426 BrakeR_OD_CAN2_Baudrate 1000.0;
BA_ "CANzero_SDO_Default" SG_ 1426 BrakeR_OD_CAN2_Baudrate 1000;
BA_ "CANzero_SDO_Group" SG_ 1426 BrakeR_OD_CAN2_autoErrorReset "CAN";
BA_ "CANzero_SDO_AccessIfOperational" SG_ 1426 BrakeR_OD_CAN2_autoErrorReset 1;
BA_ "GenSigStartValue" SG_ 1426 BrakeR_OD_CAN2_autoErrorReset 1.0;
BA_ "CANzero_SDO_Default" SG_ 1426 BrakeR_OD_CAN2_autoErrorReset 1;
BA_ "CANzero_SDO_Group" SG_ 1426 BrakeR_OD_CAN2_lastErrorCode "CAN";
BA_ "CANzero_SDO_AccessType" SG_ 1426 BrakeR_OD_CAN2_lastErrorCode 1;
BA_ "CANzero_SDO_AccessIfOperational" SG_ 1426 BrakeR_OD_CAN2_lastErrorCode 1;
BA_ "CANzero_SDO_Group" SG_ 1426 BrakeR_OD_CAN2_RxErrCnt "CAN";
BA_ "CANzero_SDO_AccessType" SG_ 1426 BrakeR_OD_CAN2_RxErrCnt 1;
BA_ "CANzero_SDO_AccessIfOperational" SG_ 1426 BrakeR_OD_CAN2_RxErrCnt 1;
BA_ "CANzero_SDO_Group" SG_ 1426 BrakeR_OD_CAN2_TxErrCnt "CAN";
BA_ "CANzero_SDO_AccessType" SG_ 1426 BrakeR_OD_CAN2_TxErrCnt 1;
BA_ "CANzero_SDO_AccessIfOperational" SG_ 1426 BrakeR_OD_CAN2_TxErrCnt 1;
BA_ "CANzero_SDO_Group" SG_ 1426 BrakeR_OD_CAN1_DelayedTxMessages "CAN";
BA_ "CANzero_SDO_AccessType" SG_ 1426 BrakeR_OD_CAN1_DelayedTxMessages 1;
BA_ "CANzero_SDO_AccessIfOperational" SG_ 1426 BrakeR_OD_CAN1_DelayedTxMessages 1;
BA_ "CANzero_SDO_Group" SG_ 1426 BrakeR_OD_CAN1_ErrorStatus "CAN";
BA_ "CANzero_SDO_AccessType" SG_ 1426 BrakeR_OD_CAN1_ErrorStatus 1;
BA_ "CANzero_SDO_AccessIfOperational" SG_ 1426 BrakeR_OD_CAN1_ErrorStatus 1;
BA_ "CANzero_SDO_Group" SG_ 1426 BrakeR_OD_CAN1_DiscardedTxMessag "CAN";
BA_ "CANzero_SDO_AccessType" SG_ 1426 BrakeR_OD_CAN1_DiscardedTxMessag 1;
BA_ "CANzero_SDO_AccessIfOperational" SG_ 1426 BrakeR_OD_CAN1_DiscardedTxMessag 1;
BA_ "SystemSignalLongSymbol" SG_ 1426 BrakeR_OD_CAN1_DiscardedTxMessag "BrakeR_OD_CAN1_DiscardedTxMessages";
BA_ "CANzero_SDO_Group" SG_ 1426 BrakeR_OD_CAN1_Status "CAN";
BA_ "CANzero_SDO_AccessType" SG_ 1426 BrakeR_OD_CAN1_Status 1;
BA_ "CANzero_SDO_AccessIfOperational" SG_ 1426 BrakeR_OD_CAN1_Status 1;
BA_ "CANzero_SDO_Group" SG_ 1426 BrakeR_OD_CAN1_Baudrate "CAN";
BA_ "CANzero_SDO_AccessIfOperational" SG_ 1426 BrakeR_OD_CAN1_Baudrate 1;
BA_ "GenSigStartValue" SG_ 1426 BrakeR_OD_CAN1_Baudrate 1000.0;
BA_ "CANzero_SDO_Default" SG_ 1426 BrakeR_OD_CAN1_Baudrate 1000;
BA_ "CANzero_SDO_Group" SG_ 1426 BrakeR_OD_CAN1_autoErrorReset "CAN";
BA_ "CANzero_SDO_AccessIfOperational" SG_ 1426 BrakeR_OD_CAN1_autoErrorReset 1;
BA_ "GenSigStartValue" SG_ 1426 BrakeR_OD_CAN1_autoErrorReset 1.0;
BA_ "CANzero_SDO_Default" SG_ 1426 BrakeR_OD_CAN1_autoErrorReset 1;
BA_ "CANzero_SDO_Group" SG_ 1426 BrakeR_OD_CAN1_lastErrorCode "CAN";
BA_ "CANzero_SDO_AccessType" SG_ 1426 BrakeR_OD_CAN1_lastErrorCode 1;
BA_ "CANzero_SDO_AccessIfOperational" SG_ 1426 BrakeR_OD_CAN1_lastErrorCode 1;
BA_ "CANzero_SDO_Group" SG_ 1426 BrakeR_OD_CAN1_RxErrCnt "CAN";
BA_ "CANzero_SDO_AccessType" SG_ 1426 BrakeR_OD_CAN1_RxErrCnt 1;
BA_ "CANzero_SDO_AccessIfOperational" SG_ 1426 BrakeR_OD_CAN1_RxErrCnt 1;
BA_ "CANzero_SDO_Group" SG_ 1426 BrakeR_OD_CAN1_TxErrCnt "CAN";
BA_ "CANzero_SDO_AccessType" SG_ 1426 BrakeR_OD_CAN1_TxErrCnt 1;
BA_ "CANzero_SDO_AccessIfOperational" SG_ 1426 BrakeR_OD_CAN1_TxErrCnt 1;
BA_ "CANzero_SDO_AccessType" SG_ 1426 BrakeR_OD_BuildTime 1;
BA_ "CANzero_SDO_AccessIfOperational" SG_ 1426 BrakeR_OD_BuildTime 1;
BA_ "CANzero_SDO_AccessType" SG_ 1426 BrakeR_OD_BuildDate 1;
BA_ "CANzero_SDO_AccessIfOperational" SG_ 1426 BrakeR_OD_BuildDate 1;
BA_ "CANzero_SDO_AccessType" SG_ 1426 BrakeR_OD_ChipUID2 1;
BA_ "CANzero_SDO_AccessIfOperational" SG_ 1426 BrakeR_OD_ChipUID2 1;
BA_ "CANzero_SDO_AccessType" SG_ 1426 BrakeR_OD_ChipUID1 1;
BA_ "CANzero_SDO_AccessIfOperational" SG_ 1426 BrakeR_OD_ChipUID1 1;
BA_ "CANzero_SDO_AccessType" SG_ 1426 BrakeR_OD_SdcOut 1;
BA_ "CANzero_SDO_AccessIfOperational" SG_ 1426 BrakeR_OD_SdcOut 1;
BA_ "CANzero_SDO_AccessType" SG_ 1426 BrakeR_OD_SdcIn 1;
BA_ "CANzero_SDO_AccessIfOperational" SG_ 1426 BrakeR_OD_SdcIn 1;
BA_ "CANzero_SDO_AccessType" SG_ 1426 BrakeR_OD_runtime 1;
BA_ "CANzero_SDO_AccessIfOperational" SG_ 1426 BrakeR_OD_runtime 1;
BA_ "CANzero_SDO_AccessType" SG_ 1426 BrakeR_OD_InputVoltage 1;
BA_ "CANzero_SDO_AccessIfOperational" SG_ 1426 BrakeR_OD_InputVoltage 1;
BA_ "CANzero_SDO_AccessType" SG_ 1426 BrakeR_OD_BoardTemp 1;
BA_ "CANzero_SDO_AccessIfOperational" SG_ 1426 BrakeR_OD_BoardTemp 1;
BA_ "GenSigStartValue" SG_ 1426 BrakeR_OD_BoardTemp 3000.0;
BA_ "CANzero_SDO_AccessType" SG_ 1426 BrakeR_OD_MemFree 1;
BA_ "CANzero_SDO_AccessIfOperational" SG_ 1426 BrakeR_OD_MemFree 1;
BA_ "CANzero_SDO_AccessType" SG_ 1426 BrakeR_OD_CpuUsage 1;
BA_ "CANzero_SDO_AccessIfOperational" SG_ 1426 BrakeR_OD_CpuUsage 1;
BA_ "CANzero_SDO_AccessIfOperational" SG_ 1426 BrakeR_OD_OdEntrySendInterval 1;
BA_ "GenSigStartValue" SG_ 1426 BrakeR_OD_OdEntrySendInterval 50.0;
BA_ "CANzero_SDO_Default" SG_ 1426 BrakeR_OD_OdEntrySendInterval 50;
BA_ "CANzero_SDO_AccessIfOperational" SG_ 1426 BrakeR_OD_SendOdOnBootup 1;
BA_ "CANzero_SDO_AccessIfOperational" SG_ 1426 BrakeR_OD_HeartbeatInterval 1;
BA_ "GenSigStartValue" SG_ 1426 BrakeR_OD_HeartbeatInterval 100.0;
BA_ "CANzero_SDO_Default" SG_ 1426 BrakeR_OD_HeartbeatInterval 100;
BA_ "CANzero_SDO_AccessType" SG_ 1426 BrakeR_OD_DbcVersion 1;
BA_ "CANzero_SDO_AccessIfOperational" SG_ 1426 BrakeR_OD_DbcVersion 1;
BA_ "CANzero_SDO_AccessType" SG_ 1426 BrakeR_OD_StackVersion 1;
BA_ "CANzero_SDO_AccessIfOperational" SG_ 1426 BrakeR_OD_StackVersion 1;
BA_ "CANzero_SDO_AccessType" SG_ 1426 BrakeR_OD_ProtocolVersion 1;
BA_ "CANzero_SDO_AccessIfOperational" SG_ 1426 BrakeR_OD_ProtocolVersion 1;
BA_ "GenSigStartValue" SG_ 1426 BrakeR_OD_ProtocolVersion 1.0;
BA_ "CANzero_SDO_Default" SG_ 1426 BrakeR_OD_ProtocolVersion 1;
BA_ "CANzero_SDO_AccessType" SG_ 1426 BrakeR_OD_NodeStatus 1;
BA_ "CANzero_SDO_AccessIfOperational" SG_ 1426 BrakeR_OD_NodeStatus 1;
BA_ "CANzero_SDO_AccessType" SG_ 1426 BrakeR_OD_NodeID 1;
BA_ "CANzero_SDO_AccessIfOperational" SG_ 1426 BrakeR_OD_NodeID 1;
BA_ "CANzero_SDO_AccessIfOperational" SG_ 1490 BrakeR_OD_valveUpperTolerance 1;
BA_ "GenSigStartValue" SG_ 1490 BrakeR_OD_valveUpperTolerance 2000.0;
BA_ "CANzero_SDO_Default" SG_ 1490 BrakeR_OD_valveUpperTolerance 10;
BA_ "CANzero_SDO_AccessIfOperational" SG_ 1490 BrakeR_OD_commWatchdog 1;
BA_ "GenSigStartValue" SG_ 1490 BrakeR_OD_commWatchdog 60.0;
BA_ "CANzero_SDO_Default" SG_ 1490 BrakeR_OD_commWatchdog 60;
BA_ "CANzero_SDO_AccessIfOperational" SG_ 1490 BrakeR_OD_counterLimit 1;
BA_ "GenSigStartValue" SG_ 1490 BrakeR_OD_counterLimit 5.0;
BA_ "CANzero_SDO_Default" SG_ 1490 BrakeR_OD_counterLimit 5;
BA_ "CANzero_SDO_AccessIfOperational" SG_ 1490 BrakeR_OD_delay 1;
BA_ "GenSigStartValue" SG_ 1490 BrakeR_OD_delay 10.0;
BA_ "CANzero_SDO_Default" SG_ 1490 BrakeR_OD_delay 5;
BA_ "CANzero_SDO_AccessIfOperational" SG_ 1490 BrakeR_OD_tankUpperControlLimit 1;
BA_ "GenSigStartValue" SG_ 1490 BrakeR_OD_tankUpperControlLimit 3800.0;
BA_ "CANzero_SDO_Default" SG_ 1490 BrakeR_OD_tankUpperControlLimit 19;
BA_ "CANzero_SDO_AccessIfOperational" SG_ 1490 BrakeR_OD_tankLowerControlLimit 1;
BA_ "GenSigStartValue" SG_ 1490 BrakeR_OD_tankLowerControlLimit 1400.0;
BA_ "CANzero_SDO_Default" SG_ 1490 BrakeR_OD_tankLowerControlLimit 7;
BA_ "CANzero_SDO_Group" SG_ 1490 BrakeR_OD_CAN2_DelayedTxMessages "CAN";
BA_ "CANzero_SDO_AccessType" SG_ 1490 BrakeR_OD_CAN2_DelayedTxMessages 1;
BA_ "CANzero_SDO_AccessIfOperational" SG_ 1490 BrakeR_OD_CAN2_DelayedTxMessages 1;
BA_ "CANzero_SDO_Group" SG_ 1490 BrakeR_OD_CAN2_ErrorStatus "CAN";
BA_ "CANzero_SDO_AccessType" SG_ 1490 BrakeR_OD_CAN2_ErrorStatus 1;
BA_ "CANzero_SDO_AccessIfOperational" SG_ 1490 BrakeR_OD_CAN2_ErrorStatus 1;
BA_ "CANzero_SDO_Group" SG_ 1490 BrakeR_OD_CAN2_DiscardedTxM_0000 "CAN";
BA_ "CANzero_SDO_AccessType" SG_ 1490 BrakeR_OD_CAN2_DiscardedTxM_0000 1;
BA_ "CANzero_SDO_AccessIfOperational" SG_ 1490 BrakeR_OD_CAN2_DiscardedTxM_0000 1;
BA_ "SystemSignalLongSymbol" SG_ 1490 BrakeR_OD_CAN2_DiscardedTxM_0000 "BrakeR_OD_CAN2_DiscardedTxMessages";
BA_ "CANzero_SDO_Group" SG_ 1490 BrakeR_OD_CAN2_Status "CAN";
BA_ "CANzero_SDO_AccessType" SG_ 1490 BrakeR_OD_CAN2_Status 1;
BA_ "CANzero_SDO_AccessIfOperational" SG_ 1490 BrakeR_OD_CAN2_Status 1;
BA_ "CANzero_SDO_Group" SG_ 1490 BrakeR_OD_CAN2_Baudrate "CAN";
BA_ "CANzero_SDO_AccessIfOperational" SG_ 1490 BrakeR_OD_CAN2_Baudrate 1;
BA_ "GenSigStartValue" SG_ 1490 BrakeR_OD_CAN2_Baudrate 1000.0;
BA_ "CANzero_SDO_Default" SG_ 1490 BrakeR_OD_CAN2_Baudrate 1000;
BA_ "CANzero_SDO_Group" SG_ 1490 BrakeR_OD_CAN2_autoErrorReset "CAN";
BA_ "CANzero_SDO_AccessIfOperational" SG_ 1490 BrakeR_OD_CAN2_autoErrorReset 1;
BA_ "GenSigStartValue" SG_ 1490 BrakeR_OD_CAN2_autoErrorReset 1.0;
BA_ "CANzero_SDO_Default" SG_ 1490 BrakeR_OD_CAN2_autoErrorReset 1;
BA_ "CANzero_SDO_Group" SG_ 1490 BrakeR_OD_CAN2_lastErrorCode "CAN";
BA_ "CANzero_SDO_AccessType" SG_ 1490 BrakeR_OD_CAN2_lastErrorCode 1;
BA_ "CANzero_SDO_AccessIfOperational" SG_ 1490 BrakeR_OD_CAN2_lastErrorCode 1;
BA_ "CANzero_SDO_Group" SG_ 1490 BrakeR_OD_CAN2_RxErrCnt "CAN";
BA_ "CANzero_SDO_AccessType" SG_ 1490 BrakeR_OD_CAN2_RxErrCnt 1;
BA_ "CANzero_SDO_AccessIfOperational" SG_ 1490 BrakeR_OD_CAN2_RxErrCnt 1;
BA_ "CANzero_SDO_Group" SG_ 1490 BrakeR_OD_CAN2_TxErrCnt "CAN";
BA_ "CANzero_SDO_AccessType" SG_ 1490 BrakeR_OD_CAN2_TxErrCnt 1;
BA_ "CANzero_SDO_AccessIfOperational" SG_ 1490 BrakeR_OD_CAN2_TxErrCnt 1;
BA_ "CANzero_SDO_Group" SG_ 1490 BrakeR_OD_CAN1_DelayedTxMessages "CAN";
BA_ "CANzero_SDO_AccessType" SG_ 1490 BrakeR_OD_CAN1_DelayedTxMessages 1;
BA_ "CANzero_SDO_AccessIfOperational" SG_ 1490 BrakeR_OD_CAN1_DelayedTxMessages 1;
BA_ "CANzero_SDO_Group" SG_ 1490 BrakeR_OD_CAN1_ErrorStatus "CAN";
BA_ "CANzero_SDO_AccessType" SG_ 1490 BrakeR_OD_CAN1_ErrorStatus 1;
BA_ "CANzero_SDO_AccessIfOperational" SG_ 1490 BrakeR_OD_CAN1_ErrorStatus 1;
BA_ "CANzero_SDO_Group" SG_ 1490 BrakeR_OD_CAN1_DiscardedTxM_0000 "CAN";
BA_ "CANzero_SDO_AccessType" SG_ 1490 BrakeR_OD_CAN1_DiscardedTxM_0000 1;
BA_ "CANzero_SDO_AccessIfOperational" SG_ 1490 BrakeR_OD_CAN1_DiscardedTxM_0000 1;
BA_ "SystemSignalLongSymbol" SG_ 1490 BrakeR_OD_CAN1_DiscardedTxM_0000 "BrakeR_OD_CAN1_DiscardedTxMessages";
BA_ "CANzero_SDO_Group" SG_ 1490 BrakeR_OD_CAN1_Status "CAN";
BA_ "CANzero_SDO_AccessType" SG_ 1490 BrakeR_OD_CAN1_Status 1;
BA_ "CANzero_SDO_AccessIfOperational" SG_ 1490 BrakeR_OD_CAN1_Status 1;
BA_ "CANzero_SDO_Group" SG_ 1490 BrakeR_OD_CAN1_Baudrate "CAN";
BA_ "CANzero_SDO_AccessIfOperational" SG_ 1490 BrakeR_OD_CAN1_Baudrate 1;
BA_ "GenSigStartValue" SG_ 1490 BrakeR_OD_CAN1_Baudrate 1000.0;
BA_ "CANzero_SDO_Default" SG_ 1490 BrakeR_OD_CAN1_Baudrate 1000;
BA_ "CANzero_SDO_Group" SG_ 1490 BrakeR_OD_CAN1_autoErrorReset "CAN";
BA_ "CANzero_SDO_AccessIfOperational" SG_ 1490 BrakeR_OD_CAN1_autoErrorReset 1;
BA_ "GenSigStartValue" SG_ 1490 BrakeR_OD_CAN1_autoErrorReset 1.0;
BA_ "CANzero_SDO_Default" SG_ 1490 BrakeR_OD_CAN1_autoErrorReset 1;
BA_ "CANzero_SDO_Group" SG_ 1490 BrakeR_OD_CAN1_lastErrorCode "CAN";
BA_ "CANzero_SDO_AccessType" SG_ 1490 BrakeR_OD_CAN1_lastErrorCode 1;
BA_ "CANzero_SDO_AccessIfOperational" SG_ 1490 BrakeR_OD_CAN1_lastErrorCode 1;
BA_ "CANzero_SDO_Group" SG_ 1490 BrakeR_OD_CAN1_RxErrCnt "CAN";
BA_ "CANzero_SDO_AccessType" SG_ 1490 BrakeR_OD_CAN1_RxErrCnt 1;
BA_ "CANzero_SDO_AccessIfOperational" SG_ 1490 BrakeR_OD_CAN1_RxErrCnt 1;
BA_ "CANzero_SDO_Group" SG_ 1490 BrakeR_OD_CAN1_TxErrCnt "CAN";
BA_ "CANzero_SDO_AccessType" SG_ 1490 BrakeR_OD_CAN1_TxErrCnt 1;
BA_ "CANzero_SDO_AccessIfOperational" SG_ 1490 BrakeR_OD_CAN1_TxErrCnt 1;
BA_ "CANzero_SDO_AccessType" SG_ 1490 BrakeR_OD_BuildTime 1;
BA_ "CANzero_SDO_AccessIfOperational" SG_ 1490 BrakeR_OD_BuildTime 1;
BA_ "CANzero_SDO_AccessType" SG_ 1490 BrakeR_OD_BuildDate 1;
BA_ "CANzero_SDO_AccessIfOperational" SG_ 1490 BrakeR_OD_BuildDate 1;
BA_ "CANzero_SDO_AccessType" SG_ 1490 BrakeR_OD_ChipUID2 1;
BA_ "CANzero_SDO_AccessIfOperational" SG_ 1490 BrakeR_OD_ChipUID2 1;
BA_ "CANzero_SDO_AccessType" SG_ 1490 BrakeR_OD_ChipUID1 1;
BA_ "CANzero_SDO_AccessIfOperational" SG_ 1490 BrakeR_OD_ChipUID1 1;
BA_ "CANzero_SDO_AccessType" SG_ 1490 BrakeR_OD_SdcOut 1;
BA_ "CANzero_SDO_AccessIfOperational" SG_ 1490 BrakeR_OD_SdcOut 1;
BA_ "CANzero_SDO_AccessType" SG_ 1490 BrakeR_OD_SdcIn 1;
BA_ "CANzero_SDO_AccessIfOperational" SG_ 1490 BrakeR_OD_SdcIn 1;
BA_ "CANzero_SDO_AccessType" SG_ 1490 BrakeR_OD_runtime 1;
BA_ "CANzero_SDO_AccessIfOperational" SG_ 1490 BrakeR_OD_runtime 1;
BA_ "CANzero_SDO_AccessType" SG_ 1490 BrakeR_OD_InputVoltage 1;
BA_ "CANzero_SDO_AccessIfOperational" SG_ 1490 BrakeR_OD_InputVoltage 1;
BA_ "CANzero_SDO_AccessType" SG_ 1490 BrakeR_OD_BoardTemp 1;
BA_ "CANzero_SDO_AccessIfOperational" SG_ 1490 BrakeR_OD_BoardTemp 1;
BA_ "GenSigStartValue" SG_ 1490 BrakeR_OD_BoardTemp 3000.0;
BA_ "CANzero_SDO_AccessType" SG_ 1490 BrakeR_OD_MemFree 1;
BA_ "CANzero_SDO_AccessIfOperational" SG_ 1490 BrakeR_OD_MemFree 1;
BA_ "CANzero_SDO_AccessType" SG_ 1490 BrakeR_OD_CpuUsage 1;
BA_ "CANzero_SDO_AccessIfOperational" SG_ 1490 BrakeR_OD_CpuUsage 1;
BA_ "CANzero_SDO_AccessIfOperational" SG_ 1490 BrakeR_OD_OdEntrySendInterval 1;
BA_ "GenSigStartValue" SG_ 1490 BrakeR_OD_OdEntrySendInterval 50.0;
BA_ "CANzero_SDO_Default" SG_ 1490 BrakeR_OD_OdEntrySendInterval 50;
BA_ "CANzero_SDO_AccessIfOperational" SG_ 1490 BrakeR_OD_SendOdOnBootup 1;
BA_ "CANzero_SDO_AccessIfOperational" SG_ 1490 BrakeR_OD_HeartbeatInterval 1;
BA_ "GenSigStartValue" SG_ 1490 BrakeR_OD_HeartbeatInterval 100.0;
BA_ "CANzero_SDO_Default" SG_ 1490 BrakeR_OD_HeartbeatInterval 100;
BA_ "CANzero_SDO_AccessType" SG_ 1490 BrakeR_OD_DbcVersion 1;
BA_ "CANzero_SDO_AccessIfOperational" SG_ 1490 BrakeR_OD_DbcVersion 1;
BA_ "CANzero_SDO_AccessType" SG_ 1490 BrakeR_OD_StackVersion 1;
BA_ "CANzero_SDO_AccessIfOperational" SG_ 1490 BrakeR_OD_StackVersion 1;
BA_ "CANzero_SDO_AccessType" SG_ 1490 BrakeR_OD_ProtocolVersion 1;
BA_ "CANzero_SDO_AccessIfOperational" SG_ 1490 BrakeR_OD_ProtocolVersion 1;
BA_ "GenSigStartValue" SG_ 1490 BrakeR_OD_ProtocolVersion 1.0;
BA_ "CANzero_SDO_Default" SG_ 1490 BrakeR_OD_ProtocolVersion 1;
BA_ "CANzero_SDO_AccessType" SG_ 1490 BrakeR_OD_NodeStatus 1;
BA_ "CANzero_SDO_AccessIfOperational" SG_ 1490 BrakeR_OD_NodeStatus 1;
BA_ "CANzero_SDO_AccessType" SG_ 1490 BrakeR_OD_NodeID 1;
BA_ "CANzero_SDO_AccessIfOperational" SG_ 1490 BrakeR_OD_NodeID 1;
BA_ "GenSigStartValue" SG_ 602 PDU_LPCh9_Dutycycle 200;
BA_ "GenSigStartValue" SG_ 602 PDU_LPCh8_Dutycycle 200;
BA_ "GenSigStartValue" SG_ 602 PDU_LPCh3_Dutycycle 200;
BA_ "GenSigStartValue" SG_ 602 PDU_LPCh2_Dutycycle 200;
BA_ "GenSigStartValue" SG_ 602 PDU_LPCh10_Dutycycle 200;
BA_ "GenSigStartValue" SG_ 602 PDU_LPCh1_Dutycycle 200;
BA_ "GenSigStartValue" SG_ 730 PDU_D4_Dutycycle 200;
BA_ "GenSigStartValue" SG_ 730 PDU_D3_Dutycycle 200;
BA_ "GenSigStartValue" SG_ 730 PDU_D2_Dutycycle 200;
BA_ "GenSigStartValue" SG_ 730 PDU_D1_Dutycycle 200;
BA_ "GenSigStartValue" SG_ 730 PDU_HPCh2_Dutycycle 200;
BA_ "GenSigStartValue" SG_ 730 PDU_HPCh1_Dutycycle 200;
BA_ "CANzero_SDO_AccessIfOperational" SG_ 1434 PDU_OD_CoolingPumpEnabled 1;
BA_ "GenSigStartValue" SG_ 1434 PDU_OD_CoolingPumpEnabled 1.0;
BA_ "CANzero_SDO_Default" SG_ 1434 PDU_OD_CoolingPumpEnabled 1;
BA_ "CANzero_SDO_AccessIfOperational" SG_ 1434 PDU_OD_LedCommands 1;
BA_ "GenSigStartValue" SG_ 1434 PDU_OD_LedCommands 1.0;
BA_ "CANzero_SDO_Default" SG_ 1434 PDU_OD_LedCommands 1;
BA_ "CANzero_SDO_AccessIfOperational" SG_ 1434 PDU_OD_projectXXEnabled 1;
BA_ "GenSigStartValue" SG_ 1434 PDU_OD_projectXXEnabled 1.0;
BA_ "CANzero_SDO_Default" SG_ 1434 PDU_OD_projectXXEnabled 1;
BA_ "CANzero_SDO_AccessIfOperational" SG_ 1434 PDU_OD_watchdogTimeout 1;
BA_ "GenSigStartValue" SG_ 1434 PDU_OD_watchdogTimeout 25.0;
BA_ "CANzero_SDO_Default" SG_ 1434 PDU_OD_watchdogTimeout 25;
BA_ "CANzero_SDO_AccessIfOperational" SG_ 1434 PDU_OD_statusSendInterval 1;
BA_ "GenSigStartValue" SG_ 1434 PDU_OD_statusSendInterval 20.0;
BA_ "CANzero_SDO_Default" SG_ 1434 PDU_OD_statusSendInterval 20;
BA_ "CANzero_SDO_AccessIfOperational" SG_ 1434 PDU_OD_currentReadInterval 1;
BA_ "GenSigStartValue" SG_ 1434 PDU_OD_currentReadInterval 100.0;
BA_ "CANzero_SDO_Default" SG_ 1434 PDU_OD_currentReadInterval 100;
BA_ "CANzero_SDO_AccessIfOperational" SG_ 1434 PDU_OD_batteryOvercurrent 1;
BA_ "GenSigStartValue" SG_ 1434 PDU_OD_batteryOvercurrent 1500.0;
BA_ "CANzero_SDO_Default" SG_ 1434 PDU_OD_batteryOvercurrent 15;
BA_ "CANzero_SDO_AccessIfOperational" SG_ 1434 PDU_OD_overTempCritical 1;
BA_ "GenSigStartValue" SG_ 1434 PDU_OD_overTempCritical 700.0;
BA_ "CANzero_SDO_Default" SG_ 1434 PDU_OD_overTempCritical 70;
BA_ "CANzero_SDO_AccessIfOperational" SG_ 1434 PDU_OD_overTempWarn 1;
BA_ "GenSigStartValue" SG_ 1434 PDU_OD_overTempWarn 400.0;
BA_ "CANzero_SDO_Default" SG_ 1434 PDU_OD_overTempWarn 40;
BA_ "CANzero_SDO_AccessIfOperational" SG_ 1434 PDU_OD_batterVoltageCritical 1;
BA_ "GenSigStartValue" SG_ 1434 PDU_OD_batterVoltageCritical 2100.0;
BA_ "CANzero_SDO_Default" SG_ 1434 PDU_OD_batterVoltageCritical 21.0;
BA_ "CANzero_SDO_AccessIfOperational" SG_ 1434 PDU_OD_batterVoltageLow 1;
BA_ "GenSigStartValue" SG_ 1434 PDU_OD_batterVoltageLow 2220.0;
BA_ "CANzero_SDO_Default" SG_ 1434 PDU_OD_batterVoltageLow 22.2;
BA_ "CANzero_SDO_Group" SG_ 1434 PDU_OD_CAN2_DelayedTxMessages "CAN";
BA_ "CANzero_SDO_AccessType" SG_ 1434 PDU_OD_CAN2_DelayedTxMessages 1;
BA_ "CANzero_SDO_AccessIfOperational" SG_ 1434 PDU_OD_CAN2_DelayedTxMessages 1;
BA_ "CANzero_SDO_Group" SG_ 1434 PDU_OD_CAN2_ErrorStatus "CAN";
BA_ "CANzero_SDO_AccessType" SG_ 1434 PDU_OD_CAN2_ErrorStatus 1;
BA_ "CANzero_SDO_AccessIfOperational" SG_ 1434 PDU_OD_CAN2_ErrorStatus 1;
BA_ "CANzero_SDO_Group" SG_ 1434 PDU_OD_CAN2_DiscardedTxMessages "CAN";
BA_ "CANzero_SDO_AccessType" SG_ 1434 PDU_OD_CAN2_DiscardedTxMessages 1;
BA_ "CANzero_SDO_AccessIfOperational" SG_ 1434 PDU_OD_CAN2_DiscardedTxMessages 1;
BA_ "CANzero_SDO_Group" SG_ 1434 PDU_OD_CAN2_Status "CAN";
BA_ "CANzero_SDO_AccessType" SG_ 1434 PDU_OD_CAN2_Status 1;
BA_ "CANzero_SDO_AccessIfOperational" SG_ 1434 PDU_OD_CAN2_Status 1;
BA_ "CANzero_SDO_Group" SG_ 1434 PDU_OD_CAN2_Baudrate "CAN";
BA_ "CANzero_SDO_AccessIfOperational" SG_ 1434 PDU_OD_CAN2_Baudrate 1;
BA_ "GenSigStartValue" SG_ 1434 PDU_OD_CAN2_Baudrate 1000.0;
BA_ "CANzero_SDO_Default" SG_ 1434 PDU_OD_CAN2_Baudrate 1000;
BA_ "CANzero_SDO_Group" SG_ 1434 PDU_OD_CAN2_autoErrorReset "CAN";
BA_ "CANzero_SDO_AccessIfOperational" SG_ 1434 PDU_OD_CAN2_autoErrorReset 1;
BA_ "GenSigStartValue" SG_ 1434 PDU_OD_CAN2_autoErrorReset 1.0;
BA_ "CANzero_SDO_Default" SG_ 1434 PDU_OD_CAN2_autoErrorReset 1;
BA_ "CANzero_SDO_Group" SG_ 1434 PDU_OD_CAN2_lastErrorCode "CAN";
BA_ "CANzero_SDO_AccessType" SG_ 1434 PDU_OD_CAN2_lastErrorCode 1;
BA_ "CANzero_SDO_AccessIfOperational" SG_ 1434 PDU_OD_CAN2_lastErrorCode 1;
BA_ "CANzero_SDO_Group" SG_ 1434 PDU_OD_CAN2_RxErrCnt "CAN";
BA_ "CANzero_SDO_AccessType" SG_ 1434 PDU_OD_CAN2_RxErrCnt 1;
BA_ "CANzero_SDO_AccessIfOperational" SG_ 1434 PDU_OD_CAN2_RxErrCnt 1;
BA_ "CANzero_SDO_Group" SG_ 1434 PDU_OD_CAN2_TxErrCnt "CAN";
BA_ "CANzero_SDO_AccessType" SG_ 1434 PDU_OD_CAN2_TxErrCnt 1;
BA_ "CANzero_SDO_AccessIfOperational" SG_ 1434 PDU_OD_CAN2_TxErrCnt 1;
BA_ "CANzero_SDO_Group" SG_ 1434 PDU_OD_CAN1_DelayedTxMessages "CAN";
BA_ "CANzero_SDO_AccessType" SG_ 1434 PDU_OD_CAN1_DelayedTxMessages 1;
BA_ "CANzero_SDO_AccessIfOperational" SG_ 1434 PDU_OD_CAN1_DelayedTxMessages 1;
BA_ "CANzero_SDO_Group" SG_ 1434 PDU_OD_CAN1_ErrorStatus "CAN";
BA_ "CANzero_SDO_AccessType" SG_ 1434 PDU_OD_CAN1_ErrorStatus 1;
BA_ "CANzero_SDO_AccessIfOperational" SG_ 1434 PDU_OD_CAN1_ErrorStatus 1;
BA_ "CANzero_SDO_Group" SG_ 1434 PDU_OD_CAN1_DiscardedTxMessages "CAN";
BA_ "CANzero_SDO_AccessType" SG_ 1434 PDU_OD_CAN1_DiscardedTxMessages 1;
BA_ "CANzero_SDO_AccessIfOperational" SG_ 1434 PDU_OD_CAN1_DiscardedTxMessages 1;
BA_ "CANzero_SDO_Group" SG_ 1434 PDU_OD_CAN1_Status "CAN";
BA_ "CANzero_SDO_AccessType" SG_ 1434 PDU_OD_CAN1_Status 1;
BA_ "CANzero_SDO_AccessIfOperational" SG_ 1434 PDU_OD_CAN1_Status 1;
BA_ "CANzero_SDO_Group" SG_ 1434 PDU_OD_CAN1_Baudrate "CAN";
BA_ "CANzero_SDO_AccessIfOperational" SG_ 1434 PDU_OD_CAN1_Baudrate 1;
BA_ "GenSigStartValue" SG_ 1434 PDU_OD_CAN1_Baudrate 1000.0;
BA_ "CANzero_SDO_Default" SG_ 1434 PDU_OD_CAN1_Baudrate 1000;
BA_ "CANzero_SDO_Group" SG_ 1434 PDU_OD_CAN1_autoErrorReset "CAN";
BA_ "CANzero_SDO_AccessIfOperational" SG_ 1434 PDU_OD_CAN1_autoErrorReset 1;
BA_ "GenSigStartValue" SG_ 1434 PDU_OD_CAN1_autoErrorReset 1.0;
BA_ "CANzero_SDO_Default" SG_ 1434 PDU_OD_CAN1_autoErrorReset 1;
BA_ "CANzero_SDO_Group" SG_ 1434 PDU_OD_CAN1_lastErrorCode "CAN";
BA_ "CANzero_SDO_AccessType" SG_ 1434 PDU_OD_CAN1_lastErrorCode 1;
BA_ "CANzero_SDO_AccessIfOperational" SG_ 1434 PDU_OD_CAN1_lastErrorCode 1;
BA_ "CANzero_SDO_Group" SG_ 1434 PDU_OD_CAN1_RxErrCnt "CAN";
BA_ "CANzero_SDO_AccessType" SG_ 1434 PDU_OD_CAN1_RxErrCnt 1;
BA_ "CANzero_SDO_AccessIfOperational" SG_ 1434 PDU_OD_CAN1_RxErrCnt 1;
BA_ "CANzero_SDO_Group" SG_ 1434 PDU_OD_CAN1_TxErrCnt "CAN";
BA_ "CANzero_SDO_AccessType" SG_ 1434 PDU_OD_CAN1_TxErrCnt 1;
BA_ "CANzero_SDO_AccessIfOperational" SG_ 1434 PDU_OD_CAN1_TxErrCnt 1;
BA_ "CANzero_SDO_AccessType" SG_ 1434 PDU_OD_BuildTime 1;
BA_ "CANzero_SDO_AccessIfOperational" SG_ 1434 PDU_OD_BuildTime 1;
BA_ "CANzero_SDO_AccessType" SG_ 1434 PDU_OD_BuildDate 1;
BA_ "CANzero_SDO_AccessIfOperational" SG_ 1434 PDU_OD_BuildDate 1;
BA_ "CANzero_SDO_AccessType" SG_ 1434 PDU_OD_ChipUID2 1;
BA_ "CANzero_SDO_AccessIfOperational" SG_ 1434 PDU_OD_ChipUID2 1;
BA_ "CANzero_SDO_AccessType" SG_ 1434 PDU_OD_ChipUID1 1;
BA_ "CANzero_SDO_AccessIfOperational" SG_ 1434 PDU_OD_ChipUID1 1;
BA_ "CANzero_SDO_AccessType" SG_ 1434 PDU_OD_SdcOut 1;
BA_ "CANzero_SDO_AccessIfOperational" SG_ 1434 PDU_OD_SdcOut 1;
BA_ "CANzero_SDO_AccessType" SG_ 1434 PDU_OD_SdcIn 1;
BA_ "CANzero_SDO_AccessIfOperational" SG_ 1434 PDU_OD_SdcIn 1;
BA_ "CANzero_SDO_AccessType" SG_ 1434 PDU_OD_runtime 1;
BA_ "CANzero_SDO_AccessIfOperational" SG_ 1434 PDU_OD_runtime 1;
BA_ "CANzero_SDO_AccessType" SG_ 1434 PDU_OD_InputVoltage 1;
BA_ "CANzero_SDO_AccessIfOperational" SG_ 1434 PDU_OD_InputVoltage 1;
BA_ "CANzero_SDO_AccessType" SG_ 1434 PDU_OD_BoardTemp 1;
BA_ "CANzero_SDO_AccessIfOperational" SG_ 1434 PDU_OD_BoardTemp 1;
BA_ "GenSigStartValue" SG_ 1434 PDU_OD_BoardTemp 3000.0;
BA_ "CANzero_SDO_AccessType" SG_ 1434 PDU_OD_MemFree 1;
BA_ "CANzero_SDO_AccessIfOperational" SG_ 1434 PDU_OD_MemFree 1;
BA_ "CANzero_SDO_AccessType" SG_ 1434 PDU_OD_CpuUsage 1;
BA_ "CANzero_SDO_AccessIfOperational" SG_ 1434 PDU_OD_CpuUsage 1;
BA_ "CANzero_SDO_AccessIfOperational" SG_ 1434 PDU_OD_OdEntrySendInterval 1;
BA_ "GenSigStartValue" SG_ 1434 PDU_OD_OdEntrySendInterval 50.0;
BA_ "CANzero_SDO_Default" SG_ 1434 PDU_OD_OdEntrySendInterval 50;
BA_ "CANzero_SDO_AccessIfOperational" SG_ 1434 PDU_OD_SendOdOnBootup 1;
BA_ "CANzero_SDO_AccessIfOperational" SG_ 1434 PDU_OD_HeartbeatInterval 1;
BA_ "GenSigStartValue" SG_ 1434 PDU_OD_HeartbeatInterval 250.0;
BA_ "CANzero_SDO_Default" SG_ 1434 PDU_OD_HeartbeatInterval 250;
BA_ "CANzero_SDO_AccessType" SG_ 1434 PDU_OD_DbcVersion 1;
BA_ "CANzero_SDO_AccessIfOperational" SG_ 1434 PDU_OD_DbcVersion 1;
BA_ "CANzero_SDO_AccessType" SG_ 1434 PDU_OD_StackVersion 1;
BA_ "CANzero_SDO_AccessIfOperational" SG_ 1434 PDU_OD_StackVersion 1;
BA_ "CANzero_SDO_AccessType" SG_ 1434 PDU_OD_ProtocolVersion 1;
BA_ "CANzero_SDO_AccessIfOperational" SG_ 1434 PDU_OD_ProtocolVersion 1;
BA_ "GenSigStartValue" SG_ 1434 PDU_OD_ProtocolVersion 1.0;
BA_ "CANzero_SDO_Default" SG_ 1434 PDU_OD_ProtocolVersion 1;
BA_ "CANzero_SDO_AccessType" SG_ 1434 PDU_OD_NodeStatus 1;
BA_ "CANzero_SDO_AccessIfOperational" SG_ 1434 PDU_OD_NodeStatus 1;
BA_ "CANzero_SDO_AccessType" SG_ 1434 PDU_OD_NodeID 1;
BA_ "CANzero_SDO_AccessIfOperational" SG_ 1434 PDU_OD_NodeID 1;
BA_ "CANzero_SDO_AccessIfOperational" SG_ 1498 PDU_OD_CoolingPumpEnabled 1;
BA_ "GenSigStartValue" SG_ 1498 PDU_OD_CoolingPumpEnabled 1.0;
BA_ "CANzero_SDO_Default" SG_ 1498 PDU_OD_CoolingPumpEnabled 1;
BA_ "CANzero_SDO_AccessIfOperational" SG_ 1498 PDU_OD_LedCommands 1;
BA_ "GenSigStartValue" SG_ 1498 PDU_OD_LedCommands 1.0;
BA_ "CANzero_SDO_Default" SG_ 1498 PDU_OD_LedCommands 1;
BA_ "CANzero_SDO_AccessIfOperational" SG_ 1498 PDU_OD_projectXXEnabled 1;
BA_ "GenSigStartValue" SG_ 1498 PDU_OD_projectXXEnabled 1.0;
BA_ "CANzero_SDO_Default" SG_ 1498 PDU_OD_projectXXEnabled 1;
BA_ "CANzero_SDO_AccessIfOperational" SG_ 1498 PDU_OD_watchdogTimeout 1;
BA_ "GenSigStartValue" SG_ 1498 PDU_OD_watchdogTimeout 25.0;
BA_ "CANzero_SDO_Default" SG_ 1498 PDU_OD_watchdogTimeout 25;
BA_ "CANzero_SDO_AccessIfOperational" SG_ 1498 PDU_OD_statusSendInterval 1;
BA_ "GenSigStartValue" SG_ 1498 PDU_OD_statusSendInterval 20.0;
BA_ "CANzero_SDO_Default" SG_ 1498 PDU_OD_statusSendInterval 20;
BA_ "CANzero_SDO_AccessIfOperational" SG_ 1498 PDU_OD_currentReadInterval 1;
BA_ "GenSigStartValue" SG_ 1498 PDU_OD_currentReadInterval 100.0;
BA_ "CANzero_SDO_Default" SG_ 1498 PDU_OD_currentReadInterval 100;
BA_ "CANzero_SDO_AccessIfOperational" SG_ 1498 PDU_OD_batteryOvercurrent 1;
BA_ "GenSigStartValue" SG_ 1498 PDU_OD_batteryOvercurrent 1500.0;
BA_ "CANzero_SDO_Default" SG_ 1498 PDU_OD_batteryOvercurrent 15;
BA_ "CANzero_SDO_AccessIfOperational" SG_ 1498 PDU_OD_overTempCritical 1;
BA_ "GenSigStartValue" SG_ 1498 PDU_OD_overTempCritical 700.0;
BA_ "CANzero_SDO_Default" SG_ 1498 PDU_OD_overTempCritical 70;
BA_ "CANzero_SDO_AccessIfOperational" SG_ 1498 PDU_OD_overTempWarn 1;
BA_ "GenSigStartValue" SG_ 1498 PDU_OD_overTempWarn 400.0;
BA_ "CANzero_SDO_Default" SG_ 1498 PDU_OD_overTempWarn 40;
BA_ "CANzero_SDO_AccessIfOperational" SG_ 1498 PDU_OD_batterVoltageCritical 1;
BA_ "GenSigStartValue" SG_ 1498 PDU_OD_batterVoltageCritical 2100.0;
BA_ "CANzero_SDO_Default" SG_ 1498 PDU_OD_batterVoltageCritical 21.0;
BA_ "CANzero_SDO_AccessIfOperational" SG_ 1498 PDU_OD_batterVoltageLow 1;
BA_ "GenSigStartValue" SG_ 1498 PDU_OD_batterVoltageLow 2220.0;
BA_ "CANzero_SDO_Default" SG_ 1498 PDU_OD_batterVoltageLow 22.2;
BA_ "CANzero_SDO_Group" SG_ 1498 PDU_OD_CAN2_DelayedTxMessages "CAN";
BA_ "CANzero_SDO_AccessType" SG_ 1498 PDU_OD_CAN2_DelayedTxMessages 1;
BA_ "CANzero_SDO_AccessIfOperational" SG_ 1498 PDU_OD_CAN2_DelayedTxMessages 1;
BA_ "CANzero_SDO_Group" SG_ 1498 PDU_OD_CAN2_ErrorStatus "CAN";
BA_ "CANzero_SDO_AccessType" SG_ 1498 PDU_OD_CAN2_ErrorStatus 1;
BA_ "CANzero_SDO_AccessIfOperational" SG_ 1498 PDU_OD_CAN2_ErrorStatus 1;
BA_ "CANzero_SDO_Group" SG_ 1498 PDU_OD_CAN2_DiscardedTxMessages "CAN";
BA_ "CANzero_SDO_AccessType" SG_ 1498 PDU_OD_CAN2_DiscardedTxMessages 1;
BA_ "CANzero_SDO_AccessIfOperational" SG_ 1498 PDU_OD_CAN2_DiscardedTxMessages 1;
BA_ "CANzero_SDO_Group" SG_ 1498 PDU_OD_CAN2_Status "CAN";
BA_ "CANzero_SDO_AccessType" SG_ 1498 PDU_OD_CAN2_Status 1;
BA_ "CANzero_SDO_AccessIfOperational" SG_ 1498 PDU_OD_CAN2_Status 1;
BA_ "CANzero_SDO_Group" SG_ 1498 PDU_OD_CAN2_Baudrate "CAN";
BA_ "CANzero_SDO_AccessIfOperational" SG_ 1498 PDU_OD_CAN2_Baudrate 1;
BA_ "GenSigStartValue" SG_ 1498 PDU_OD_CAN2_Baudrate 1000.0;
BA_ "CANzero_SDO_Default" SG_ 1498 PDU_OD_CAN2_Baudrate 1000;
BA_ "CANzero_SDO_Group" SG_ 1498 PDU_OD_CAN2_autoErrorReset "CAN";
BA_ "CANzero_SDO_AccessIfOperational" SG_ 1498 PDU_OD_CAN2_autoErrorReset 1;
BA_ "GenSigStartValue" SG_ 1498 PDU_OD_CAN2_autoErrorReset 1.0;
BA_ "CANzero_SDO_Default" SG_ 1498 PDU_OD_CAN2_autoErrorReset 1;
BA_ "CANzero_SDO_Group" SG_ 1498 PDU_OD_CAN2_lastErrorCode "CAN";
BA_ "CANzero_SDO_AccessType" SG_ 1498 PDU_OD_CAN2_lastErrorCode 1;
BA_ "CANzero_SDO_AccessIfOperational" SG_ 1498 PDU_OD_CAN2_lastErrorCode 1;
BA_ "CANzero_SDO_Group" SG_ 1498 PDU_OD_CAN2_RxErrCnt "CAN";
BA_ "CANzero_SDO_AccessType" SG_ 1498 PDU_OD_CAN2_RxErrCnt 1;
BA_ "CANzero_SDO_AccessIfOperational" SG_ 1498 PDU_OD_CAN2_RxErrCnt 1;
BA_ "CANzero_SDO_Group" SG_ 1498 PDU_OD_CAN2_TxErrCnt "CAN";
BA_ "CANzero_SDO_AccessType" SG_ 1498 PDU_OD_CAN2_TxErrCnt 1;
BA_ "CANzero_SDO_AccessIfOperational" SG_ 1498 PDU_OD_CAN2_TxErrCnt 1;
BA_ "CANzero_SDO_Group" SG_ 1498 PDU_OD_CAN1_DelayedTxMessages "CAN";
BA_ "CANzero_SDO_AccessType" SG_ 1498 PDU_OD_CAN1_DelayedTxMessages 1;
BA_ "CANzero_SDO_AccessIfOperational" SG_ 1498 PDU_OD_CAN1_DelayedTxMessages 1;
BA_ "CANzero_SDO_Group" SG_ 1498 PDU_OD_CAN1_ErrorStatus "CAN";
BA_ "CANzero_SDO_AccessType" SG_ 1498 PDU_OD_CAN1_ErrorStatus 1;
BA_ "CANzero_SDO_AccessIfOperational" SG_ 1498 PDU_OD_CAN1_ErrorStatus 1;
BA_ "CANzero_SDO_Group" SG_ 1498 PDU_OD_CAN1_DiscardedTxMessages "CAN";
BA_ "CANzero_SDO_AccessType" SG_ 1498 PDU_OD_CAN1_DiscardedTxMessages 1;
BA_ "CANzero_SDO_AccessIfOperational" SG_ 1498 PDU_OD_CAN1_DiscardedTxMessages 1;
BA_ "CANzero_SDO_Group" SG_ 1498 PDU_OD_CAN1_Status "CAN";
BA_ "CANzero_SDO_AccessType" SG_ 1498 PDU_OD_CAN1_Status 1;
BA_ "CANzero_SDO_AccessIfOperational" SG_ 1498 PDU_OD_CAN1_Status 1;
BA_ "CANzero_SDO_Group" SG_ 1498 PDU_OD_CAN1_Baudrate "CAN";
BA_ "CANzero_SDO_AccessIfOperational" SG_ 1498 PDU_OD_CAN1_Baudrate 1;
BA_ "GenSigStartValue" SG_ 1498 PDU_OD_CAN1_Baudrate 1000.0;
BA_ "CANzero_SDO_Default" SG_ 1498 PDU_OD_CAN1_Baudrate 1000;
BA_ "CANzero_SDO_Group" SG_ 1498 PDU_OD_CAN1_autoErrorReset "CAN";
BA_ "CANzero_SDO_AccessIfOperational" SG_ 1498 PDU_OD_CAN1_autoErrorReset 1;
BA_ "GenSigStartValue" SG_ 1498 PDU_OD_CAN1_autoErrorReset 1.0;
BA_ "CANzero_SDO_Default" SG_ 1498 PDU_OD_CAN1_autoErrorReset 1;
BA_ "CANzero_SDO_Group" SG_ 1498 PDU_OD_CAN1_lastErrorCode "CAN";
BA_ "CANzero_SDO_AccessType" SG_ 1498 PDU_OD_CAN1_lastErrorCode 1;
BA_ "CANzero_SDO_AccessIfOperational" SG_ 1498 PDU_OD_CAN1_lastErrorCode 1;
BA_ "CANzero_SDO_Group" SG_ 1498 PDU_OD_CAN1_RxErrCnt "CAN";
BA_ "CANzero_SDO_AccessType" SG_ 1498 PDU_OD_CAN1_RxErrCnt 1;
BA_ "CANzero_SDO_AccessIfOperational" SG_ 1498 PDU_OD_CAN1_RxErrCnt 1;
BA_ "CANzero_SDO_Group" SG_ 1498 PDU_OD_CAN1_TxErrCnt "CAN";
BA_ "CANzero_SDO_AccessType" SG_ 1498 PDU_OD_CAN1_TxErrCnt 1;
BA_ "CANzero_SDO_AccessIfOperational" SG_ 1498 PDU_OD_CAN1_TxErrCnt 1;
BA_ "CANzero_SDO_AccessType" SG_ 1498 PDU_OD_BuildTime 1;
BA_ "CANzero_SDO_AccessIfOperational" SG_ 1498 PDU_OD_BuildTime 1;
BA_ "CANzero_SDO_AccessType" SG_ 1498 PDU_OD_BuildDate 1;
BA_ "CANzero_SDO_AccessIfOperational" SG_ 1498 PDU_OD_BuildDate 1;
BA_ "CANzero_SDO_AccessType" SG_ 1498 PDU_OD_ChipUID2 1;
BA_ "CANzero_SDO_AccessIfOperational" SG_ 1498 PDU_OD_ChipUID2 1;
BA_ "CANzero_SDO_AccessType" SG_ 1498 PDU_OD_ChipUID1 1;
BA_ "CANzero_SDO_AccessIfOperational" SG_ 1498 PDU_OD_ChipUID1 1;
BA_ "CANzero_SDO_AccessType" SG_ 1498 PDU_OD_SdcOut 1;
BA_ "CANzero_SDO_AccessIfOperational" SG_ 1498 PDU_OD_SdcOut 1;
BA_ "CANzero_SDO_AccessType" SG_ 1498 PDU_OD_SdcIn 1;
BA_ "CANzero_SDO_AccessIfOperational" SG_ 1498 PDU_OD_SdcIn 1;
BA_ "CANzero_SDO_AccessType" SG_ 1498 PDU_OD_runtime 1;
BA_ "CANzero_SDO_AccessIfOperational" SG_ 1498 PDU_OD_runtime 1;
BA_ "CANzero_SDO_AccessType" SG_ 1498 PDU_OD_InputVoltage 1;
BA_ "CANzero_SDO_AccessIfOperational" SG_ 1498 PDU_OD_InputVoltage 1;
BA_ "CANzero_SDO_AccessType" SG_ 1498 PDU_OD_BoardTemp 1;
BA_ "CANzero_SDO_AccessIfOperational" SG_ 1498 PDU_OD_BoardTemp 1;
BA_ "GenSigStartValue" SG_ 1498 PDU_OD_BoardTemp 3000.0;
BA_ "CANzero_SDO_AccessType" SG_ 1498 PDU_OD_MemFree 1;
BA_ "CANzero_SDO_AccessIfOperational" SG_ 1498 PDU_OD_MemFree 1;
BA_ "CANzero_SDO_AccessType" SG_ 1498 PDU_OD_CpuUsage 1;
BA_ "CANzero_SDO_AccessIfOperational" SG_ 1498 PDU_OD_CpuUsage 1;
BA_ "CANzero_SDO_AccessIfOperational" SG_ 1498 PDU_OD_OdEntrySendInterval 1;
BA_ "GenSigStartValue" SG_ 1498 PDU_OD_OdEntrySendInterval 50.0;
BA_ "CANzero_SDO_Default" SG_ 1498 PDU_OD_OdEntrySendInterval 50;
BA_ "CANzero_SDO_AccessIfOperational" SG_ 1498 PDU_OD_SendOdOnBootup 1;
BA_ "CANzero_SDO_AccessIfOperational" SG_ 1498 PDU_OD_HeartbeatInterval 1;
BA_ "GenSigStartValue" SG_ 1498 PDU_OD_HeartbeatInterval 250.0;
BA_ "CANzero_SDO_Default" SG_ 1498 PDU_OD_HeartbeatInterval 250;
BA_ "CANzero_SDO_AccessType" SG_ 1498 PDU_OD_DbcVersion 1;
BA_ "CANzero_SDO_AccessIfOperational" SG_ 1498 PDU_OD_DbcVersion 1;
BA_ "CANzero_SDO_AccessType" SG_ 1498 PDU_OD_StackVersion 1;
BA_ "CANzero_SDO_AccessIfOperational" SG_ 1498 PDU_OD_StackVersion 1;
BA_ "CANzero_SDO_AccessType" SG_ 1498 PDU_OD_ProtocolVersion 1;
BA_ "CANzero_SDO_AccessIfOperational" SG_ 1498 PDU_OD_ProtocolVersion 1;
BA_ "GenSigStartValue" SG_ 1498 PDU_OD_ProtocolVersion 1.0;
BA_ "CANzero_SDO_Default" SG_ 1498 PDU_OD_ProtocolVersion 1;
BA_ "CANzero_SDO_AccessType" SG_ 1498 PDU_OD_NodeStatus 1;
BA_ "CANzero_SDO_AccessIfOperational" SG_ 1498 PDU_OD_NodeStatus 1;
BA_ "CANzero_SDO_AccessType" SG_ 1498 PDU_OD_NodeID 1;
BA_ "CANzero_SDO_AccessIfOperational" SG_ 1498 PDU_OD_NodeID 1;
BA_ "CANzero_SDO_Group" SG_ 1418 HVCU_OD_CAN2_DelayedTxMessages "CAN";
BA_ "CANzero_SDO_AccessType" SG_ 1418 HVCU_OD_CAN2_DelayedTxMessages 1;
BA_ "CANzero_SDO_AccessIfOperational" SG_ 1418 HVCU_OD_CAN2_DelayedTxMessages 1;
BA_ "CANzero_SDO_Group" SG_ 1418 HVCU_OD_CAN2_ErrorStatus "CAN";
BA_ "CANzero_SDO_AccessType" SG_ 1418 HVCU_OD_CAN2_ErrorStatus 1;
BA_ "CANzero_SDO_AccessIfOperational" SG_ 1418 HVCU_OD_CAN2_ErrorStatus 1;
BA_ "CANzero_SDO_Group" SG_ 1418 HVCU_OD_CAN2_DiscardedTxMessages "CAN";
BA_ "CANzero_SDO_AccessType" SG_ 1418 HVCU_OD_CAN2_DiscardedTxMessages 1;
BA_ "CANzero_SDO_AccessIfOperational" SG_ 1418 HVCU_OD_CAN2_DiscardedTxMessages 1;
BA_ "CANzero_SDO_Group" SG_ 1418 HVCU_OD_CAN2_Status "CAN";
BA_ "CANzero_SDO_AccessType" SG_ 1418 HVCU_OD_CAN2_Status 1;
BA_ "CANzero_SDO_AccessIfOperational" SG_ 1418 HVCU_OD_CAN2_Status 1;
BA_ "CANzero_SDO_Group" SG_ 1418 HVCU_OD_CAN2_Baudrate "CAN";
BA_ "CANzero_SDO_AccessIfOperational" SG_ 1418 HVCU_OD_CAN2_Baudrate 1;
BA_ "GenSigStartValue" SG_ 1418 HVCU_OD_CAN2_Baudrate 1000.0;
BA_ "CANzero_SDO_Default" SG_ 1418 HVCU_OD_CAN2_Baudrate 1000;
BA_ "CANzero_SDO_Group" SG_ 1418 HVCU_OD_CAN2_autoErrorReset "CAN";
BA_ "CANzero_SDO_AccessIfOperational" SG_ 1418 HVCU_OD_CAN2_autoErrorReset 1;
BA_ "GenSigStartValue" SG_ 1418 HVCU_OD_CAN2_autoErrorReset 1.0;
BA_ "CANzero_SDO_Default" SG_ 1418 HVCU_OD_CAN2_autoErrorReset 1;
BA_ "CANzero_SDO_Group" SG_ 1418 HVCU_OD_CAN2_lastErrorCode "CAN";
BA_ "CANzero_SDO_AccessType" SG_ 1418 HVCU_OD_CAN2_lastErrorCode 1;
BA_ "CANzero_SDO_AccessIfOperational" SG_ 1418 HVCU_OD_CAN2_lastErrorCode 1;
BA_ "CANzero_SDO_Group" SG_ 1418 HVCU_OD_CAN2_RxErrCnt "CAN";
BA_ "CANzero_SDO_AccessType" SG_ 1418 HVCU_OD_CAN2_RxErrCnt 1;
BA_ "CANzero_SDO_AccessIfOperational" SG_ 1418 HVCU_OD_CAN2_RxErrCnt 1;
BA_ "CANzero_SDO_Group" SG_ 1418 HVCU_OD_CAN2_TxErrCnt "CAN";
BA_ "CANzero_SDO_AccessType" SG_ 1418 HVCU_OD_CAN2_TxErrCnt 1;
BA_ "CANzero_SDO_AccessIfOperational" SG_ 1418 HVCU_OD_CAN2_TxErrCnt 1;
BA_ "CANzero_SDO_Group" SG_ 1418 HVCU_OD_CAN1_DelayedTxMessages "CAN";
BA_ "CANzero_SDO_AccessType" SG_ 1418 HVCU_OD_CAN1_DelayedTxMessages 1;
BA_ "CANzero_SDO_AccessIfOperational" SG_ 1418 HVCU_OD_CAN1_DelayedTxMessages 1;
BA_ "CANzero_SDO_Group" SG_ 1418 HVCU_OD_CAN1_ErrorStatus "CAN";
BA_ "CANzero_SDO_AccessType" SG_ 1418 HVCU_OD_CAN1_ErrorStatus 1;
BA_ "CANzero_SDO_AccessIfOperational" SG_ 1418 HVCU_OD_CAN1_ErrorStatus 1;
BA_ "CANzero_SDO_Group" SG_ 1418 HVCU_OD_CAN1_DiscardedTxMessages "CAN";
BA_ "CANzero_SDO_AccessType" SG_ 1418 HVCU_OD_CAN1_DiscardedTxMessages 1;
BA_ "CANzero_SDO_AccessIfOperational" SG_ 1418 HVCU_OD_CAN1_DiscardedTxMessages 1;
BA_ "CANzero_SDO_Group" SG_ 1418 HVCU_OD_CAN1_Status "CAN";
BA_ "CANzero_SDO_AccessType" SG_ 1418 HVCU_OD_CAN1_Status 1;
BA_ "CANzero_SDO_AccessIfOperational" SG_ 1418 HVCU_OD_CAN1_Status 1;
BA_ "CANzero_SDO_Group" SG_ 1418 HVCU_OD_CAN1_Baudrate "CAN";
BA_ "CANzero_SDO_AccessIfOperational" SG_ 1418 HVCU_OD_CAN1_Baudrate 1;
BA_ "GenSigStartValue" SG_ 1418 HVCU_OD_CAN1_Baudrate 1000.0;
BA_ "CANzero_SDO_Default" SG_ 1418 HVCU_OD_CAN1_Baudrate 1000;
BA_ "CANzero_SDO_Group" SG_ 1418 HVCU_OD_CAN1_autoErrorReset "CAN";
BA_ "CANzero_SDO_AccessIfOperational" SG_ 1418 HVCU_OD_CAN1_autoErrorReset 1;
BA_ "GenSigStartValue" SG_ 1418 HVCU_OD_CAN1_autoErrorReset 1.0;
BA_ "CANzero_SDO_Default" SG_ 1418 HVCU_OD_CAN1_autoErrorReset 1;
BA_ "CANzero_SDO_Group" SG_ 1418 HVCU_OD_CAN1_lastErrorCode "CAN";
BA_ "CANzero_SDO_AccessType" SG_ 1418 HVCU_OD_CAN1_lastErrorCode 1;
BA_ "CANzero_SDO_AccessIfOperational" SG_ 1418 HVCU_OD_CAN1_lastErrorCode 1;
BA_ "CANzero_SDO_Group" SG_ 1418 HVCU_OD_CAN1_RxErrCnt "CAN";
BA_ "CANzero_SDO_AccessType" SG_ 1418 HVCU_OD_CAN1_RxErrCnt 1;
BA_ "CANzero_SDO_AccessIfOperational" SG_ 1418 HVCU_OD_CAN1_RxErrCnt 1;
BA_ "CANzero_SDO_Group" SG_ 1418 HVCU_OD_CAN1_TxErrCnt "CAN";
BA_ "CANzero_SDO_AccessType" SG_ 1418 HVCU_OD_CAN1_TxErrCnt 1;
BA_ "CANzero_SDO_AccessIfOperational" SG_ 1418 HVCU_OD_CAN1_TxErrCnt 1;
BA_ "CANzero_SDO_AccessType" SG_ 1418 HVCU_OD_BuildTime 1;
BA_ "CANzero_SDO_AccessIfOperational" SG_ 1418 HVCU_OD_BuildTime 1;
BA_ "CANzero_SDO_AccessType" SG_ 1418 HVCU_OD_BuildDate 1;
BA_ "CANzero_SDO_AccessIfOperational" SG_ 1418 HVCU_OD_BuildDate 1;
BA_ "CANzero_SDO_AccessType" SG_ 1418 HVCU_OD_ChipUID2 1;
BA_ "CANzero_SDO_AccessIfOperational" SG_ 1418 HVCU_OD_ChipUID2 1;
BA_ "CANzero_SDO_AccessType" SG_ 1418 HVCU_OD_ChipUID1 1;
BA_ "CANzero_SDO_AccessIfOperational" SG_ 1418 HVCU_OD_ChipUID1 1;
BA_ "CANzero_SDO_AccessType" SG_ 1418 HVCU_OD_SdcOut 1;
BA_ "CANzero_SDO_AccessIfOperational" SG_ 1418 HVCU_OD_SdcOut 1;
BA_ "CANzero_SDO_AccessType" SG_ 1418 HVCU_OD_SdcIn 1;
BA_ "CANzero_SDO_AccessIfOperational" SG_ 1418 HVCU_OD_SdcIn 1;
BA_ "CANzero_SDO_AccessType" SG_ 1418 HVCU_OD_runtime 1;
BA_ "CANzero_SDO_AccessIfOperational" SG_ 1418 HVCU_OD_runtime 1;
BA_ "CANzero_SDO_AccessType" SG_ 1418 HVCU_OD_InputVoltage 1;
BA_ "CANzero_SDO_AccessIfOperational" SG_ 1418 HVCU_OD_InputVoltage 1;
BA_ "CANzero_SDO_AccessType" SG_ 1418 HVCU_OD_BoardTemp 1;
BA_ "CANzero_SDO_AccessIfOperational" SG_ 1418 HVCU_OD_BoardTemp 1;
BA_ "GenSigStartValue" SG_ 1418 HVCU_OD_BoardTemp 3000.0;
BA_ "CANzero_SDO_AccessType" SG_ 1418 HVCU_OD_MemFree 1;
BA_ "CANzero_SDO_AccessIfOperational" SG_ 1418 HVCU_OD_MemFree 1;
BA_ "CANzero_SDO_AccessType" SG_ 1418 HVCU_OD_CpuUsage 1;
BA_ "CANzero_SDO_AccessIfOperational" SG_ 1418 HVCU_OD_CpuUsage 1;
BA_ "CANzero_SDO_AccessIfOperational" SG_ 1418 HVCU_OD_OdEntrySendInterval 1;
BA_ "GenSigStartValue" SG_ 1418 HVCU_OD_OdEntrySendInterval 10.0;
BA_ "CANzero_SDO_Default" SG_ 1418 HVCU_OD_OdEntrySendInterval 10;
BA_ "CANzero_SDO_AccessIfOperational" SG_ 1418 HVCU_OD_SendOdOnBootup 1;
BA_ "CANzero_SDO_AccessIfOperational" SG_ 1418 HVCU_OD_HeartbeatInterval 1;
BA_ "GenSigStartValue" SG_ 1418 HVCU_OD_HeartbeatInterval 250.0;
BA_ "CANzero_SDO_Default" SG_ 1418 HVCU_OD_HeartbeatInterval 250;
BA_ "CANzero_SDO_AccessType" SG_ 1418 HVCU_OD_DbcVersion 1;
BA_ "CANzero_SDO_AccessIfOperational" SG_ 1418 HVCU_OD_DbcVersion 1;
BA_ "CANzero_SDO_AccessType" SG_ 1418 HVCU_OD_StackVersion 1;
BA_ "CANzero_SDO_AccessIfOperational" SG_ 1418 HVCU_OD_StackVersion 1;
BA_ "CANzero_SDO_AccessType" SG_ 1418 HVCU_OD_ProtocolVersion 1;
BA_ "CANzero_SDO_AccessIfOperational" SG_ 1418 HVCU_OD_ProtocolVersion 1;
BA_ "GenSigStartValue" SG_ 1418 HVCU_OD_ProtocolVersion 1.0;
BA_ "CANzero_SDO_Default" SG_ 1418 HVCU_OD_ProtocolVersion 1;
BA_ "CANzero_SDO_AccessType" SG_ 1418 HVCU_OD_NodeStatus 1;
BA_ "CANzero_SDO_AccessIfOperational" SG_ 1418 HVCU_OD_NodeStatus 1;
BA_ "CANzero_SDO_AccessType" SG_ 1418 HVCU_OD_NodeID 1;
BA_ "CANzero_SDO_AccessIfOperational" SG_ 1418 HVCU_OD_NodeID 1;
VAL_ 1538 SensorR_SDO_ID 0 "Reserved" 1 "NodeID" 2 "NodeStatus" 3 "ProtocolVersion" 4 "StackVersion" 5 "DbcVersion" 16 "HeartbeatInterval" 32 "SendOdOnBootup" 33 "OdEntrySendInterval" 1040 "CpuUsage" 1041 "MemFree" 1042 "BoardTemp" 1043 "InputVoltage" 1044 "runtime" 1045 "SdcIn" 1046 "SdcOut" 1056 "ChipUID1" 1057 "ChipUID2" 1072 "BuildDate" 1073 "BuildTime" 1104 "CAN1_TxErrCnt" 1105 "CAN1_RxErrCnt" 1106 "CAN1_lastErrorCode" 1107 "CAN1_autoErrorReset" 1108 "CAN1_Baudrate" 1110 "CAN1_Status" 1111 "CAN1_DiscardedTxMessages" 1112 "CAN1_ErrorStatus" 1113 "CAN1_DelayedTxMessages" 1120 "CAN2_TxErrCnt" 1121 "CAN2_RxErrCnt" 1122 "CAN2_lastErrorCode" 1123 "CAN2_autoErrorReset" 1124 "CAN2_Baudrate" 1126 "CAN2_Status" 1127 "CAN2_DiscardedTxMessages" 1128 "CAN2_ErrorStatus" 1129 "CAN2_DelayedTxMessages" 2048 "samplingInterval" 2576 "EncoderWheelDiameter" 2586 "EncoderResetPosition" 2592 "IMU_number" 2597 "IMU1_Temperature" 2598 "IMU2_Temperature" 2599 "IMU3_Temperature" 2608 "ExecTimeOverall" 2609 "ExecTimeStateEst" 2610 "ExecTimeControl" 2611 "ExecTimeReadSensors" 2624 "OpcKp" 2625 "OpcKi" 2626 "CtrlMode" 2627 "CurrentReq" 2628 "PodMass" 2629 "FmaxCtrl" 2630 "FminCtrl" 2631 "MaxCtrlError" 2632 "MaxCtrlErrorDuration" 2633 "WarningThreshholdForLimModelOutOfBoundaries" 2634 "MaxRequiredVelocity" 2635 "VdcReduceFactor" 2636 "RunMode" 2637 "SetFinish" 2816 "RunProfile_T0" 2817 "RunProfile_V0" 2818 "RunProfile_T1" 2819 "RunProfile_V1" 2820 "RunProfile_T2" 2821 "RunProfile_V2" 2822 "RunProfile_T3" 2823 "RunProfile_V3" 2824 "RunProfile_T4" 2825 "RunProfile_V4" 2826 "EstimatedRunLength" 3072 "TC_I" 3073 "TC_f" 3074 "VelocityController" 3075 "CVOPCImax" 3076 "CVOPCTcf" 3077 "CVOPCTcI" 3078 "CVOPCSmoothingDeltaVelocity" 3079 "CVOPCDeltaVelHigherCurrent" 3080 "CVOPCReduceCurrentWhileCruising" 3081 "CVOPCHystereseF" 3088 "AccAtCurrentMeasured" 3089 "CurrentForConstantVelocity" 3090 "CascadedMaxSetForceDelta" 3091 "CascadedFreqCurUpdate" 3092 "CascadedKpIncreaseCurrent" 3093 "CascadedKpDecreaseCurrent" 3094 "CVOPCImin" 3095 "CVOPCTcFreq" 3096 "AdaptModelByCurrent" 3097 "Current4Stopping" 3104 "FinishedDelay" 3105 "maxRunDistance" 3106 "opc_ratelimiter_f" 3107 "DebugCascadedIreq" 3108 "DebugCVOPCfreq" 3109 "opc_brakeFlag" 3110 "opc_t_run_max" 3111 "opc_F_max" 3112 "opc_T_acc" 3113 "opc_v_max" 3120 "opc_v_threshold" 3121 "opc_F_decrease" 3122 "opc_lowpass_Tcf" 3123 "opc_lowpass_TcI" 3329 "StripeMode" 3330 "ReflectorDistance" 3331 "PositionGlitch" 3332 "EnableSignalGeneration" 3585 "accDeviation" 3586 "velDeviationEncoder" 3587 "velDeviationOptic" 3588 "posDeviationEncoder" 3589 "posDeviationOptic" ;
VAL_ 1794 SensorR_NodeState 0 "Bootup" 4 "Stopped" 5 "Operational" 127 "Pre-Operational" ;
VAL_ 145 BrakeF_E5_retractUnsuccesful_ope 0 "Ok" 1 "ERR" ;
VAL_ 145 BrakeF_E4_retractUnsuccesful_not 0 "Ok" 1 "ERR" ;
VAL_ 145 BrakeF_E3_retractUnsuccesful_err 0 "Ok" 1 "ERR" ;
VAL_ 145 BrakeF_E2_commWatchdogTimeout 0 "Ok" 1 "ERR" ;
VAL_ 145 BrakeF_E1_pressureTooLow 0 "Ok" 1 "ERR" ;
VAL_ 145 BrakeF_E0_pressureTooHigh 0 "Ok" 1 "ERR" ;
VAL_ 145 BrakeF_W3_externalError 0 "Ok" 1 "WARN" ;
VAL_ 145 BrakeF_W2_enableWithAnError 0 "Ok" 1 "WARN" ;
VAL_ 145 BrakeF_W1_highPressureRetracting 0 "Ok" 1 "WARN" ;
VAL_ 145 BrakeF_W0_highPressureActingCham 0 "Ok" 1 "WARN" ;
VAL_ 401 BrakeF_TX_SDC_Input 1 "Closed" 0 "Open" ;
VAL_ 401 BrakeF_TX_ErrorFlag 1 "Error" 0 "No Error" ;
VAL_ 401 BrakeF_TX_Enabled 1 "Enabled" 0 "Disabled" ;
VAL_ 401 BrakeF_TX_Status 2 "EngagedService" 1 "EngagedEmergency" 0 "Disengaged" ;
VAL_ 465 BrakeF_RX_Engage 2 "EngageService" 1 "EngageEmergency" 0 "Disengage" ;
VAL_ 465 BrakeF_RX_Enable 1 "Enable" 0 "Disable" ;
VAL_ 465 BrakeF_RX_ErrorReset 1 "Reset" 0 "No Reset" ;
VAL_ 1425 BrakeF_OD_CAN2_ErrorStatus 0 "Ok" 1 "Warn" 2 "Error Passive" 3 "Bus Off" ;
VAL_ 1425 BrakeF_OD_CAN2_Status 0 "Reset" 1 "Ready" 2 "Listening" 3 "Sleep_Pending" 4 "Sleep_Active" 5 "ERROR" ;
VAL_ 1425 BrakeF_OD_CAN2_autoErrorReset 0 "Disabled" 1 "Enabled" ;
VAL_ 1425 BrakeF_OD_CAN2_lastErrorCode 0 "No Error" 1 "Stuff Error" 2 "Form Error" 3 "Ack Error" 4 "Bit recessive Error" 5 "Bit dominant Error" 6 "CRC Error" ;
VAL_ 1425 BrakeF_OD_CAN1_ErrorStatus 0 "Ok" 1 "Warn" 2 "Error Passive" 3 "Bus Off" ;
VAL_ 1425 BrakeF_OD_CAN1_Status 0 "Reset" 1 "Ready" 2 "Listening" 3 "Sleep_Pending" 4 "Sleep_Active" 5 "ERROR" ;
VAL_ 1425 BrakeF_OD_CAN1_autoErrorReset 0 "Disabled" 1 "Enabled" ;
VAL_ 1425 BrakeF_OD_CAN1_lastErrorCode 0 "No Error" 1 "Stuff Error" 2 "Form Error" 3 "Ack Error" 4 "Bit recessive Error" 5 "Bit dominant Error" 6 "CRC Error" ;
VAL_ 1425 BrakeF_OD_SendOdOnBootup 0 "Disabled" 1 "Enabled" ;
VAL_ 1425 BrakeF_OD_NodeStatus 0 "Bootup" 4 "Stopped" 5 "Operational" 127 "Pre-Operational" 128 "Reset" ;
VAL_ 1425 BrakeF_SDO_RespCode 5 "ERR: Out of range" 4 "ERR: No access in this state" 3 "ERR: Read only object" 2 "ERR: Write only object" 1 "ERR: Non existing object" 0 "OK" ;
VAL_ 1425 BrakeF_SDO_ID 0 "Reserved" 1 "NodeID" 2 "NodeStatus" 3 "ProtocolVersion" 4 "StackVersion" 5 "DbcVersion" 16 "HeartbeatInterval" 32 "SendOdOnBootup" 33 "OdEntrySendInterval" 1040 "CpuUsage" 1041 "MemFree" 1042 "BoardTemp" 1043 "InputVoltage" 1044 "runtime" 1045 "SdcIn" 1046 "SdcOut" 1056 "ChipUID1" 1057 "ChipUID2" 1072 "BuildDate" 1073 "BuildTime" 1104 "CAN1_TxErrCnt" 1105 "CAN1_RxErrCnt" 1106 "CAN1_lastErrorCode" 1107 "CAN1_autoErrorReset" 1108 "CAN1_Baudrate" 1110 "CAN1_Status" 1111 "CAN1_DiscardedTxMessages" 1112 "CAN1_ErrorStatus" 1113 "CAN1_DelayedTxMessages" 1120 "CAN2_TxErrCnt" 1121 "CAN2_RxErrCnt" 1122 "CAN2_lastErrorCode" 1123 "CAN2_autoErrorReset" 1124 "CAN2_Baudrate" 1126 "CAN2_Status" 1127 "CAN2_DiscardedTxMessages" 1128 "CAN2_ErrorStatus" 1129 "CAN2_DelayedTxMessages" 2048 "tankLowerControlLimit" 2049 "tankUpperControlLimit" 2050 "delay" 2051 "counterLimit" 2052 "commWatchdog" 2053 "valveUpperTolerance" ;
VAL_ 1489 BrakeF_OD_CAN2_ErrorStatus 0 "Ok" 1 "Warn" 2 "Error Passive" 3 "Bus Off" ;
VAL_ 1489 BrakeF_OD_CAN2_Status 0 "Reset" 1 "Ready" 2 "Listening" 3 "Sleep_Pending" 4 "Sleep_Active" 5 "ERROR" ;
VAL_ 1489 BrakeF_OD_CAN2_autoErrorReset 0 "Disabled" 1 "Enabled" ;
VAL_ 1489 BrakeF_OD_CAN2_lastErrorCode 0 "No Error" 1 "Stuff Error" 2 "Form Error" 3 "Ack Error" 4 "Bit recessive Error" 5 "Bit dominant Error" 6 "CRC Error" ;
VAL_ 1489 BrakeF_OD_CAN1_ErrorStatus 0 "Ok" 1 "Warn" 2 "Error Passive" 3 "Bus Off" ;
VAL_ 1489 BrakeF_OD_CAN1_Status 0 "Reset" 1 "Ready" 2 "Listening" 3 "Sleep_Pending" 4 "Sleep_Active" 5 "ERROR" ;
VAL_ 1489 BrakeF_OD_CAN1_autoErrorReset 0 "Disabled" 1 "Enabled" ;
VAL_ 1489 BrakeF_OD_CAN1_lastErrorCode 0 "No Error" 1 "Stuff Error" 2 "Form Error" 3 "Ack Error" 4 "Bit recessive Error" 5 "Bit dominant Error" 6 "CRC Error" ;
VAL_ 1489 BrakeF_OD_SendOdOnBootup 0 "Disabled" 1 "Enabled" ;
VAL_ 1489 BrakeF_OD_NodeStatus 0 "Bootup" 4 "Stopped" 5 "Operational" 127 "Pre-Operational" 128 "Reset" ;
VAL_ 1489 BrakeF_SDO_ID 0 "Reserved" 1 "NodeID" 2 "NodeStatus" 3 "ProtocolVersion" 4 "StackVersion" 5 "DbcVersion" 16 "HeartbeatInterval" 32 "SendOdOnBootup" 33 "OdEntrySendInterval" 1040 "CpuUsage" 1041 "MemFree" 1042 "BoardTemp" 1043 "InputVoltage" 1044 "runtime" 1045 "SdcIn" 1046 "SdcOut" 1056 "ChipUID1" 1057 "ChipUID2" 1072 "BuildDate" 1073 "BuildTime" 1104 "CAN1_TxErrCnt" 1105 "CAN1_RxErrCnt" 1106 "CAN1_lastErrorCode" 1107 "CAN1_autoErrorReset" 1108 "CAN1_Baudrate" 1110 "CAN1_Status" 1111 "CAN1_DiscardedTxMessages" 1112 "CAN1_ErrorStatus" 1113 "CAN1_DelayedTxMessages" 1120 "CAN2_TxErrCnt" 1121 "CAN2_RxErrCnt" 1122 "CAN2_lastErrorCode" 1123 "CAN2_autoErrorReset" 1124 "CAN2_Baudrate" 1126 "CAN2_Status" 1127 "CAN2_DiscardedTxMessages" 1128 "CAN2_ErrorStatus" 1129 "CAN2_DelayedTxMessages" 2048 "tankLowerControlLimit" 2049 "tankUpperControlLimit" 2050 "delay" 2051 "counterLimit" 2052 "commWatchdog" 2053 "valveUpperTolerance" ;
VAL_ 1553 BrakeF_SDO_ID 0 "Reserved" 1 "NodeID" 2 "NodeStatus" 3 "ProtocolVersion" 4 "StackVersion" 5 "DbcVersion" 16 "HeartbeatInterval" 32 "SendOdOnBootup" 33 "OdEntrySendInterval" 1040 "CpuUsage" 1041 "MemFree" 1042 "BoardTemp" 1043 "InputVoltage" 1044 "runtime" 1045 "SdcIn" 1046 "SdcOut" 1056 "ChipUID1" 1057 "ChipUID2" 1072 "BuildDate" 1073 "BuildTime" 1104 "CAN1_TxErrCnt" 1105 "CAN1_RxErrCnt" 1106 "CAN1_lastErrorCode" 1107 "CAN1_autoErrorReset" 1108 "CAN1_Baudrate" 1110 "CAN1_Status" 1111 "CAN1_DiscardedTxMessages" 1112 "CAN1_ErrorStatus" 1113 "CAN1_DelayedTxMessages" 1120 "CAN2_TxErrCnt" 1121 "CAN2_RxErrCnt" 1122 "CAN2_lastErrorCode" 1123 "CAN2_autoErrorReset" 1124 "CAN2_Baudrate" 1126 "CAN2_Status" 1127 "CAN2_DiscardedTxMessages" 1128 "CAN2_ErrorStatus" 1129 "CAN2_DelayedTxMessages" 2048 "tankLowerControlLimit" 2049 "tankUpperControlLimit" 2050 "delay" 2051 "counterLimit" 2052 "commWatchdog" 2053 "valveUpperTolerance" ;
VAL_ 1809 BrakeF_NodeState 0 "Bootup" 4 "Stopped" 5 "Operational" 127 "Pre-Operational" ;
VAL_ 146 BrakeR_E5_retractUnsuccesful_ope 0 "Ok" 1 "ERR" ;
VAL_ 146 BrakeR_E4_retractUnsuccesful_not 0 "Ok" 1 "ERR" ;
VAL_ 146 BrakeR_E3_retractUnsuccesful_err 0 "Ok" 1 "ERR" ;
VAL_ 146 BrakeR_E2_commWatchdogTimeout 0 "Ok" 1 "ERR" ;
VAL_ 146 BrakeR_E1_pressureTooLow 0 "Ok" 1 "ERR" ;
VAL_ 146 BrakeR_E0_pressureTooHigh 0 "Ok" 1 "ERR" ;
VAL_ 146 BrakeR_W3_externalError 0 "Ok" 1 "WARN" ;
VAL_ 146 BrakeR_W2_enableWithAnError 0 "Ok" 1 "WARN" ;
VAL_ 146 BrakeR_W1_highPressureRetracting 0 "Ok" 1 "WARN" ;
VAL_ 146 BrakeR_W0_highPressureActingCham 0 "Ok" 1 "WARN" ;
VAL_ 402 BrakeR_TX_SDC_Input 1 "Closed" 0 "Open" ;
VAL_ 402 BrakeR_TX_ErrorFlag 1 "Error" 0 "No Error" ;
VAL_ 402 BrakeR_TX_Enabled 1 "Enabled" 0 "Disabled" ;
VAL_ 402 BrakeR_TX_Status 2 "EngagedService" 1 "EngagedEmergency" 0 "Disengaged" ;
VAL_ 466 BrakeR_RX_Engage 2 "EngageService" 1 "EngageEmergency" 0 "Disengage" ;
VAL_ 466 BrakeR_RX_Enable 1 "Enable" 0 "Disable" ;
VAL_ 466 BrakeR_RX_ErrorReset 1 "Reset" 0 "No Reset" ;
VAL_ 1426 BrakeR_OD_CAN2_ErrorStatus 0 "Ok" 1 "Warn" 2 "Error Passive" 3 "Bus Off" ;
VAL_ 1426 BrakeR_OD_CAN2_Status 0 "Reset" 1 "Ready" 2 "Listening" 3 "Sleep_Pending" 4 "Sleep_Active" 5 "ERROR" ;
VAL_ 1426 BrakeR_OD_CAN2_autoErrorReset 0 "Disabled" 1 "Enabled" ;
VAL_ 1426 BrakeR_OD_CAN2_lastErrorCode 0 "No Error" 1 "Stuff Error" 2 "Form Error" 3 "Ack Error" 4 "Bit recessive Error" 5 "Bit dominant Error" 6 "CRC Error" ;
VAL_ 1426 BrakeR_OD_CAN1_ErrorStatus 0 "Ok" 1 "Warn" 2 "Error Passive" 3 "Bus Off" ;
VAL_ 1426 BrakeR_OD_CAN1_Status 0 "Reset" 1 "Ready" 2 "Listening" 3 "Sleep_Pending" 4 "Sleep_Active" 5 "ERROR" ;
VAL_ 1426 BrakeR_OD_CAN1_autoErrorReset 0 "Disabled" 1 "Enabled" ;
VAL_ 1426 BrakeR_OD_CAN1_lastErrorCode 0 "No Error" 1 "Stuff Error" 2 "Form Error" 3 "Ack Error" 4 "Bit recessive Error" 5 "Bit dominant Error" 6 "CRC Error" ;
VAL_ 1426 BrakeR_OD_SendOdOnBootup 0 "Disabled" 1 "Enabled" ;
VAL_ 1426 BrakeR_OD_NodeStatus 0 "Bootup" 4 "Stopped" 5 "Operational" 127 "Pre-Operational" 128 "Reset" ;
VAL_ 1426 BrakeR_SDO_RespCode 5 "ERR: Out of range" 4 "ERR: No access in this state" 3 "ERR: Read only object" 2 "ERR: Write only object" 1 "ERR: Non existing object" 0 "OK" ;
VAL_ 1426 BrakeR_SDO_ID 0 "Reserved" 1 "NodeID" 2 "NodeStatus" 3 "ProtocolVersion" 4 "StackVersion" 5 "DbcVersion" 16 "HeartbeatInterval" 32 "SendOdOnBootup" 33 "OdEntrySendInterval" 1040 "CpuUsage" 1041 "MemFree" 1042 "BoardTemp" 1043 "InputVoltage" 1044 "runtime" 1045 "SdcIn" 1046 "SdcOut" 1056 "ChipUID1" 1057 "ChipUID2" 1072 "BuildDate" 1073 "BuildTime" 1104 "CAN1_TxErrCnt" 1105 "CAN1_RxErrCnt" 1106 "CAN1_lastErrorCode" 1107 "CAN1_autoErrorReset" 1108 "CAN1_Baudrate" 1110 "CAN1_Status" 1111 "CAN1_DiscardedTxMessages" 1112 "CAN1_ErrorStatus" 1113 "CAN1_DelayedTxMessages" 1120 "CAN2_TxErrCnt" 1121 "CAN2_RxErrCnt" 1122 "CAN2_lastErrorCode" 1123 "CAN2_autoErrorReset" 1124 "CAN2_Baudrate" 1126 "CAN2_Status" 1127 "CAN2_DiscardedTxMessages" 1128 "CAN2_ErrorStatus" 1129 "CAN2_DelayedTxMessages" 2048 "tankLowerControlLimit" 2049 "tankUpperControlLimit" 2050 "delay" 2051 "counterLimit" 2052 "commWatchdog" 2053 "valveUpperTolerance" ;
VAL_ 1490 BrakeR_OD_CAN2_ErrorStatus 0 "Ok" 1 "Warn" 2 "Error Passive" 3 "Bus Off" ;
VAL_ 1490 BrakeR_OD_CAN2_Status 0 "Reset" 1 "Ready" 2 "Listening" 3 "Sleep_Pending" 4 "Sleep_Active" 5 "ERROR" ;
VAL_ 1490 BrakeR_OD_CAN2_autoErrorReset 0 "Disabled" 1 "Enabled" ;
VAL_ 1490 BrakeR_OD_CAN2_lastErrorCode 0 "No Error" 1 "Stuff Error" 2 "Form Error" 3 "Ack Error" 4 "Bit recessive Error" 5 "Bit dominant Error" 6 "CRC Error" ;
VAL_ 1490 BrakeR_OD_CAN1_ErrorStatus 0 "Ok" 1 "Warn" 2 "Error Passive" 3 "Bus Off" ;
VAL_ 1490 BrakeR_OD_CAN1_Status 0 "Reset" 1 "Ready" 2 "Listening" 3 "Sleep_Pending" 4 "Sleep_Active" 5 "ERROR" ;
VAL_ 1490 BrakeR_OD_CAN1_autoErrorReset 0 "Disabled" 1 "Enabled" ;
VAL_ 1490 BrakeR_OD_CAN1_lastErrorCode 0 "No Error" 1 "Stuff Error" 2 "Form Error" 3 "Ack Error" 4 "Bit recessive Error" 5 "Bit dominant Error" 6 "CRC Error" ;
VAL_ 1490 BrakeR_OD_SendOdOnBootup 0 "Disabled" 1 "Enabled" ;
VAL_ 1490 BrakeR_OD_NodeStatus 0 "Bootup" 4 "Stopped" 5 "Operational" 127 "Pre-Operational" 128 "Reset" ;
VAL_ 1490 BrakeR_SDO_ID 0 "Reserved" 1 "NodeID" 2 "NodeStatus" 3 "ProtocolVersion" 4 "StackVersion" 5 "DbcVersion" 16 "HeartbeatInterval" 32 "SendOdOnBootup" 33 "OdEntrySendInterval" 1040 "CpuUsage" 1041 "MemFree" 1042 "BoardTemp" 1043 "InputVoltage" 1044 "runtime" 1045 "SdcIn" 1046 "SdcOut" 1056 "ChipUID1" 1057 "ChipUID2" 1072 "BuildDate" 1073 "BuildTime" 1104 "CAN1_TxErrCnt" 1105 "CAN1_RxErrCnt" 1106 "CAN1_lastErrorCode" 1107 "CAN1_autoErrorReset" 1108 "CAN1_Baudrate" 1110 "CAN1_Status" 1111 "CAN1_DiscardedTxMessages" 1112 "CAN1_ErrorStatus" 1113 "CAN1_DelayedTxMessages" 1120 "CAN2_TxErrCnt" 1121 "CAN2_RxErrCnt" 1122 "CAN2_lastErrorCode" 1123 "CAN2_autoErrorReset" 1124 "CAN2_Baudrate" 1126 "CAN2_Status" 1127 "CAN2_DiscardedTxMessages" 1128 "CAN2_ErrorStatus" 1129 "CAN2_DelayedTxMessages" 2048 "tankLowerControlLimit" 2049 "tankUpperControlLimit" 2050 "delay" 2051 "counterLimit" 2052 "commWatchdog" 2053 "valveUpperTolerance" ;
VAL_ 1554 BrakeR_SDO_ID 0 "Reserved" 1 "NodeID" 2 "NodeStatus" 3 "ProtocolVersion" 4 "StackVersion" 5 "DbcVersion" 16 "HeartbeatInterval" 32 "SendOdOnBootup" 33 "OdEntrySendInterval" 1040 "CpuUsage" 1041 "MemFree" 1042 "BoardTemp" 1043 "InputVoltage" 1044 "runtime" 1045 "SdcIn" 1046 "SdcOut" 1056 "ChipUID1" 1057 "ChipUID2" 1072 "BuildDate" 1073 "BuildTime" 1104 "CAN1_TxErrCnt" 1105 "CAN1_RxErrCnt" 1106 "CAN1_lastErrorCode" 1107 "CAN1_autoErrorReset" 1108 "CAN1_Baudrate" 1110 "CAN1_Status" 1111 "CAN1_DiscardedTxMessages" 1112 "CAN1_ErrorStatus" 1113 "CAN1_DelayedTxMessages" 1120 "CAN2_TxErrCnt" 1121 "CAN2_RxErrCnt" 1122 "CAN2_lastErrorCode" 1123 "CAN2_autoErrorReset" 1124 "CAN2_Baudrate" 1126 "CAN2_Status" 1127 "CAN2_DiscardedTxMessages" 1128 "CAN2_ErrorStatus" 1129 "CAN2_DelayedTxMessages" 2048 "tankLowerControlLimit" 2049 "tankUpperControlLimit" 2050 "delay" 2051 "counterLimit" 2052 "commWatchdog" 2053 "valveUpperTolerance" ;
VAL_ 1810 BrakeR_NodeState 0 "Bootup" 4 "Stopped" 5 "Operational" 127 "Pre-Operational" ;
VAL_ 154 PDU_E4_watchdogStateMachine 0 "Ok" 1 "ERR" ;
VAL_ 154 PDU_E3_batterTempCritical 0 "Ok" 1 "ERR" ;
VAL_ 154 PDU_E2_batteryOvercurrent 0 "Ok" 1 "ERR" ;
VAL_ 154 PDU_E1_batterVoltageCritical 0 "Ok" 1 "ERR" ;
VAL_ 154 PDU_E0_OtherError 0 "Ok" 1 "ERR" ;
VAL_ 154 PDU_W2_batterTempHigh 0 "Ok" 1 "WARN" ;
VAL_ 154 PDU_W1_batterVoltageLow 0 "Ok" 1 "WARN" ;
VAL_ 154 PDU_W0_OtherWarning 0 "Ok" 1 "WARN" ;
VAL_ 410 PDU_TX_PEHWEnabled 1 "Enabled" 0 "Disabled" ;
VAL_ 410 PDU_TX_ErrorFlag 1 "Error" 0 "No Error" ;
VAL_ 410 PDU_TX_Enabled 1 "Enabled" 0 "Disabled" ;
VAL_ 474 PDU_RX_PEHWEnable 1 "Enable" 0 "Disable" ;
VAL_ 474 PDU_RX_ErrorReset 1 "Reset" 0 "No Reset" ;
VAL_ 474 PDU_RX_Enable 1 "Enable" 0 "Disable" ;
VAL_ 1178 PDU_LPCh1_State 3 "External Voltage" 2 "Output Short Circuit" 1 "Status Change Pending" 0 "OK" ;
VAL_ 1434 PDU_OD_CoolingPumpEnabled 0 "Disable" 1 "Enable" ;
VAL_ 1434 PDU_OD_LedCommands 0 "None" 1 "whipeanimation" 2 "mugreenanimation" 3 "rainbowanimation" 4 "flashlights" 5 "snakeanimation" 6 "blinkpink" 7 "multiwhipe" 8 "Emergency" ;
VAL_ 1434 PDU_OD_projectXXEnabled 0 "Disable" 1 "Enable" ;
VAL_ 1434 PDU_OD_CAN2_ErrorStatus 0 "Ok" 1 "Warn" 2 "Error Passive" 3 "Bus Off" ;
VAL_ 1434 PDU_OD_CAN2_Status 0 "Reset" 1 "Ready" 2 "Listening" 3 "Sleep_Pending" 4 "Sleep_Active" 5 "ERROR" ;
VAL_ 1434 PDU_OD_CAN2_autoErrorReset 0 "Disabled" 1 "Enabled" ;
VAL_ 1434 PDU_OD_CAN2_lastErrorCode 0 "No Error" 1 "Stuff Error" 2 "Form Error" 3 "Ack Error" 4 "Bit recessive Error" 5 "Bit dominant Error" 6 "CRC Error" ;
VAL_ 1434 PDU_OD_CAN1_ErrorStatus 0 "Ok" 1 "Warn" 2 "Error Passive" 3 "Bus Off" ;
VAL_ 1434 PDU_OD_CAN1_Status 0 "Reset" 1 "Ready" 2 "Listening" 3 "Sleep_Pending" 4 "Sleep_Active" 5 "ERROR" ;
VAL_ 1434 PDU_OD_CAN1_autoErrorReset 0 "Disabled" 1 "Enabled" ;
VAL_ 1434 PDU_OD_CAN1_lastErrorCode 0 "No Error" 1 "Stuff Error" 2 "Form Error" 3 "Ack Error" 4 "Bit recessive Error" 5 "Bit dominant Error" 6 "CRC Error" ;
VAL_ 1434 PDU_OD_SendOdOnBootup 0 "Disabled" 1 "Enabled" ;
VAL_ 1434 PDU_OD_NodeStatus 0 "Bootup" 4 "Stopped" 5 "Operational" 127 "Pre-Operational" 128 "Reset" ;
VAL_ 1434 PDU_SDO_RespCode 5 "ERR: Out of range" 4 "ERR: No access in this state" 3 "ERR: Read only object" 2 "ERR: Write only object" 1 "ERR: Non existing object" 0 "OK" ;
VAL_ 1434 PDU_SDO_ID 0 "Reserved" 1 "NodeID" 2 "NodeStatus" 3 "ProtocolVersion" 4 "StackVersion" 5 "DbcVersion" 16 "HeartbeatInterval" 32 "SendOdOnBootup" 33 "OdEntrySendInterval" 1040 "CpuUsage" 1041 "MemFree" 1042 "BoardTemp" 1043 "InputVoltage" 1044 "runtime" 1045 "SdcIn" 1046 "SdcOut" 1056 "ChipUID1" 1057 "ChipUID2" 1072 "BuildDate" 1073 "BuildTime" 1104 "CAN1_TxErrCnt" 1105 "CAN1_RxErrCnt" 1106 "CAN1_lastErrorCode" 1107 "CAN1_autoErrorReset" 1108 "CAN1_Baudrate" 1110 "CAN1_Status" 1111 "CAN1_DiscardedTxMessages" 1112 "CAN1_ErrorStatus" 1113 "CAN1_DelayedTxMessages" 1120 "CAN2_TxErrCnt" 1121 "CAN2_RxErrCnt" 1122 "CAN2_lastErrorCode" 1123 "CAN2_autoErrorReset" 1124 "CAN2_Baudrate" 1126 "CAN2_Status" 1127 "CAN2_DiscardedTxMessages" 1128 "CAN2_ErrorStatus" 1129 "CAN2_DelayedTxMessages" 2048 "batterVoltageLow" 2049 "batterVoltageCritical" 2050 "overTempWarn" 2051 "overTempCritical" 2128 "batteryOvercurrent" 2304 "currentReadInterval" 2305 "statusSendInterval" 2306 "watchdogTimeout" 2560 "projectXXEnabled" 2562 "LedCommands" 2816 "CoolingPumpEnabled" ;
VAL_ 1498 PDU_OD_CoolingPumpEnabled 0 "Disable" 1 "Enable" ;
VAL_ 1498 PDU_OD_LedCommands 0 "None" 1 "whipeanimation" 2 "mugreenanimation" 3 "rainbowanimation" 4 "flashlights" 5 "snakeanimation" 6 "blinkpink" 7 "multiwhipe" 8 "Emergency" ;
VAL_ 1498 PDU_OD_projectXXEnabled 0 "Disable" 1 "Enable" ;
VAL_ 1498 PDU_OD_CAN2_ErrorStatus 0 "Ok" 1 "Warn" 2 "Error Passive" 3 "Bus Off" ;
VAL_ 1498 PDU_OD_CAN2_Status 0 "Reset" 1 "Ready" 2 "Listening" 3 "Sleep_Pending" 4 "Sleep_Active" 5 "ERROR" ;
VAL_ 1498 PDU_OD_CAN2_autoErrorReset 0 "Disabled" 1 "Enabled" ;
VAL_ 1498 PDU_OD_CAN2_lastErrorCode 0 "No Error" 1 "Stuff Error" 2 "Form Error" 3 "Ack Error" 4 "Bit recessive Error" 5 "Bit dominant Error" 6 "CRC Error" ;
VAL_ 1498 PDU_OD_CAN1_ErrorStatus 0 "Ok" 1 "Warn" 2 "Error Passive" 3 "Bus Off" ;
VAL_ 1498 PDU_OD_CAN1_Status 0 "Reset" 1 "Ready" 2 "Listening" 3 "Sleep_Pending" 4 "Sleep_Active" 5 "ERROR" ;
VAL_ 1498 PDU_OD_CAN1_autoErrorReset 0 "Disabled" 1 "Enabled" ;
VAL_ 1498 PDU_OD_CAN1_lastErrorCode 0 "No Error" 1 "Stuff Error" 2 "Form Error" 3 "Ack Error" 4 "Bit recessive Error" 5 "Bit dominant Error" 6 "CRC Error" ;
VAL_ 1498 PDU_OD_SendOdOnBootup 0 "Disabled" 1 "Enabled" ;
VAL_ 1498 PDU_OD_NodeStatus 0 "Bootup" 4 "Stopped" 5 "Operational" 127 "Pre-Operational" 128 "Reset" ;
VAL_ 1498 PDU_SDO_ID 0 "Reserved" 1 "NodeID" 2 "NodeStatus" 3 "ProtocolVersion" 4 "StackVersion" 5 "DbcVersion" 16 "HeartbeatInterval" 32 "SendOdOnBootup" 33 "OdEntrySendInterval" 1040 "CpuUsage" 1041 "MemFree" 1042 "BoardTemp" 1043 "InputVoltage" 1044 "runtime" 1045 "SdcIn" 1046 "SdcOut" 1056 "ChipUID1" 1057 "ChipUID2" 1072 "BuildDate" 1073 "BuildTime" 1104 "CAN1_TxErrCnt" 1105 "CAN1_RxErrCnt" 1106 "CAN1_lastErrorCode" 1107 "CAN1_autoErrorReset" 1108 "CAN1_Baudrate" 1110 "CAN1_Status" 1111 "CAN1_DiscardedTxMessages" 1112 "CAN1_ErrorStatus" 1113 "CAN1_DelayedTxMessages" 1120 "CAN2_TxErrCnt" 1121 "CAN2_RxErrCnt" 1122 "CAN2_lastErrorCode" 1123 "CAN2_autoErrorReset" 1124 "CAN2_Baudrate" 1126 "CAN2_Status" 1127 "CAN2_DiscardedTxMessages" 1128 "CAN2_ErrorStatus" 1129 "CAN2_DelayedTxMessages" 2048 "batterVoltageLow" 2049 "batterVoltageCritical" 2050 "overTempWarn" 2051 "overTempCritical" 2128 "batteryOvercurrent" 2304 "currentReadInterval" 2305 "statusSendInterval" 2306 "watchdogTimeout" 2560 "projectXXEnabled" 2562 "LedCommands" 2816 "CoolingPumpEnabled" ;
VAL_ 1562 PDU_SDO_ID 0 "Reserved" 1 "NodeID" 2 "NodeStatus" 3 "ProtocolVersion" 4 "StackVersion" 5 "DbcVersion" 16 "HeartbeatInterval" 32 "SendOdOnBootup" 33 "OdEntrySendInterval" 1040 "CpuUsage" 1041 "MemFree" 1042 "BoardTemp" 1043 "InputVoltage" 1044 "runtime" 1045 "SdcIn" 1046 "SdcOut" 1056 "ChipUID1" 1057 "ChipUID2" 1072 "BuildDate" 1073 "BuildTime" 1104 "CAN1_TxErrCnt" 1105 "CAN1_RxErrCnt" 1106 "CAN1_lastErrorCode" 1107 "CAN1_autoErrorReset" 1108 "CAN1_Baudrate" 1110 "CAN1_Status" 1111 "CAN1_DiscardedTxMessages" 1112 "CAN1_ErrorStatus" 1113 "CAN1_DelayedTxMessages" 1120 "CAN2_TxErrCnt" 1121 "CAN2_RxErrCnt" 1122 "CAN2_lastErrorCode" 1123 "CAN2_autoErrorReset" 1124 "CAN2_Baudrate" 1126 "CAN2_Status" 1127 "CAN2_DiscardedTxMessages" 1128 "CAN2_ErrorStatus" 1129 "CAN2_DelayedTxMessages" 2048 "batterVoltageLow" 2049 "batterVoltageCritical" 2050 "overTempWarn" 2051 "overTempCritical" 2128 "batteryOvercurrent" 2304 "currentReadInterval" 2305 "statusSendInterval" 2306 "watchdogTimeout" 2560 "projectXXEnabled" 2562 "LedCommands" 2816 "CoolingPumpEnabled" ;
VAL_ 1818 PDU_NodeState 0 "Bootup" 4 "Stopped" 5 "Operational" 127 "Pre-Operational" ;
VAL_ 138 HVCU_E19_ChargingModeError 0 "Ok" 1 "ERR" ;
VAL_ 138 HVCU_E18_SDCSwitchError 0 "Ok" 1 "ERR" ;
VAL_ 138 HVCU_E17_ControlMessageTimeout 0 "Ok" 1 "ERR" ;
VAL_ 138 HVCU_E16_NoEnable 0 "Ok" 1 "ERR" ;
VAL_ 138 HVCU_E15_SDCOpen 0 "Ok" 1 "ERR" ;
VAL_ 138 HVCU_E14_HVMPError 0 "Ok" 1 "ERR" ;
VAL_ 138 HVCU_E13_BIR4Error 0 "Ok" 1 "ERR" ;
VAL_ 138 HVCU_E12_BIR3Error 0 "Ok" 1 "ERR" ;
VAL_ 138 HVCU_E11_BIR2Error 0 "Ok" 1 "ERR" ;
VAL_ 138 HVCU_E10_BIR1Error 0 "Ok" 1 "ERR" ;
VAL_ 138 HVCU_E9_HVSLError 0 "Ok" 1 "ERR" ;
VAL_ 138 HVCU_E8_VoltageMeasuring 0 "Ok" 1 "ERR" ;
VAL_ 138 HVCU_E7_BALError 0 "Ok" 1 "ERR" ;
VAL_ 138 HVCU_E6_DischargeError 0 "Ok" 1 "ERR" ;
VAL_ 138 HVCU_E5_DischargeTimeout 0 "Ok" 1 "ERR" ;
VAL_ 138 HVCU_E4_BMSPermissionMissing 0 "Ok" 1 "ERR" ;
VAL_ 138 HVCU_E3_PrechargeError 0 "Ok" 1 "ERR" ;
VAL_ 138 HVCU_E2_BMSError 0 "Ok" 1 "ERR" ;
VAL_ 138 HVCU_E1_IMDError 0 "Ok" 1 "ERR" ;
VAL_ 138 HVCU_E0_OtherError 0 "Ok" 1 "ERR" ;
VAL_ 138 HVCU_W8_ChargingMode 0 "Ok" 1 "WARN" ;
VAL_ 138 HVCU_W7_IsolationResistanceLow 0 "Ok" 1 "WARN" ;
VAL_ 138 HVCU_W6_Bir4On 0 "Ok" 1 "WARN" ;
VAL_ 138 HVCU_W5_Bir3On 0 "Ok" 1 "WARN" ;
VAL_ 138 HVCU_W4_Bir2On 0 "Ok" 1 "WARN" ;
VAL_ 138 HVCU_W3_Bir1On 0 "Ok" 1 "WARN" ;
VAL_ 138 HVCU_W2_PreChargeOn 0 "Ok" 1 "WARN" ;
VAL_ 138 HVCU_W1_HighVoltage 0 "Ok" 1 "WARN" ;
VAL_ 138 HVCU_W0_OtherWarning 0 "Ok" 1 "WARN" ;
VAL_ 394 HVCU_TX_Enabled 1 "Enabled" 0 "Disabled" ;
VAL_ 394 HVCU_TX_ErrorFlag 1 "Error" 0 "No Error" ;
VAL_ 394 HVCU_TX_Status 4 "Error" 3 "Shutdown" 2 "Startup" 1 "Activated" 0 "Deactivated" ;
VAL_ 394 HVCU_TX_InternalStatus 7 "Error" 6 "Disable SDC" 5 "Discharging" 4 "Active" 3 "Precharging" 2 "Enable SDC" 1 "Idle" 0 "Startup" ;
VAL_ 458 HVCU_RX_Charging 1 "Charging" 0 "Not Charging" ;
VAL_ 458 HVCU_RX_ErrorReset 1 "Reset" 0 "No Reset" ;
VAL_ 458 HVCU_RX_Activate 1 "Activate" 0 "Deactivate" ;
VAL_ 458 HVCU_RX_Enable 1 "Enable" 0 "Disable" ;
VAL_ 1418 HVCU_OD_CAN2_ErrorStatus 0 "Ok" 1 "Warn" 2 "Error Passive" 3 "Bus Off" ;
VAL_ 1418 HVCU_OD_CAN2_Status 0 "Reset" 1 "Ready" 2 "Listening" 3 "Sleep_Pending" 4 "Sleep_Active" 5 "ERROR" ;
VAL_ 1418 HVCU_OD_CAN2_autoErrorReset 0 "Disabled" 1 "Enabled" ;
VAL_ 1418 HVCU_OD_CAN2_lastErrorCode 0 "No Error" 1 "Stuff Error" 2 "Form Error" 3 "Ack Error" 4 "Bit recessive Error" 5 "Bit dominant Error" 6 "CRC Error" ;
VAL_ 1418 HVCU_OD_CAN1_ErrorStatus 0 "Ok" 1 "Warn" 2 "Error Passive" 3 "Bus Off" ;
VAL_ 1418 HVCU_OD_CAN1_Status 0 "Reset" 1 "Ready" 2 "Listening" 3 "Sleep_Pending" 4 "Sleep_Active" 5 "ERROR" ;
VAL_ 1418 HVCU_OD_CAN1_autoErrorReset 0 "Disabled" 1 "Enabled" ;
VAL_ 1418 HVCU_OD_CAN1_lastErrorCode 0 "No Error" 1 "Stuff Error" 2 "Form Error" 3 "Ack Error" 4 "Bit recessive Error" 5 "Bit dominant Error" 6 "CRC Error" ;
VAL_ 1418 HVCU_OD_SendOdOnBootup 0 "Disabled" 1 "Enabled" ;
VAL_ 1418 HVCU_OD_NodeStatus 0 "Bootup" 4 "Stopped" 5 "Operational" 127 "Pre-Operational" 128 "Reset" ;
VAL_ 1418 HVCU_SDO_RespCode 5 "ERR: Out of range" 4 "ERR: No access in this state" 3 "ERR: Read only object" 2 "ERR: Write only object" 1 "ERR: Non existing object" 0 "OK" ;
VAL_ 1418 HVCU_SDO_ID 0 "Reserved" 1 "NodeID" 2 "NodeStatus" 3 "ProtocolVersion" 4 "StackVersion" 5 "DbcVersion" 16 "HeartbeatInterval" 32 "SendOdOnBootup" 33 "OdEntrySendInterval" 1040 "CpuUsage" 1041 "MemFree" 1042 "BoardTemp" 1043 "InputVoltage" 1044 "runtime" 1045 "SdcIn" 1046 "SdcOut" 1056 "ChipUID1" 1057 "ChipUID2" 1072 "BuildDate" 1073 "BuildTime" 1104 "CAN1_TxErrCnt" 1105 "CAN1_RxErrCnt" 1106 "CAN1_lastErrorCode" 1107 "CAN1_autoErrorReset" 1108 "CAN1_Baudrate" 1110 "CAN1_Status" 1111 "CAN1_DiscardedTxMessages" 1112 "CAN1_ErrorStatus" 1113 "CAN1_DelayedTxMessages" 1120 "CAN2_TxErrCnt" 1121 "CAN2_RxErrCnt" 1122 "CAN2_lastErrorCode" 1123 "CAN2_autoErrorReset" 1124 "CAN2_Baudrate" 1126 "CAN2_Status" 1127 "CAN2_DiscardedTxMessages" 1128 "CAN2_ErrorStatus" 1129 "CAN2_DelayedTxMessages" ;
